VERSION "ZCUD_CAN1"

NS_ :

BS_:

BU_: ETC OGM POT SRS3 TRM ZCUD

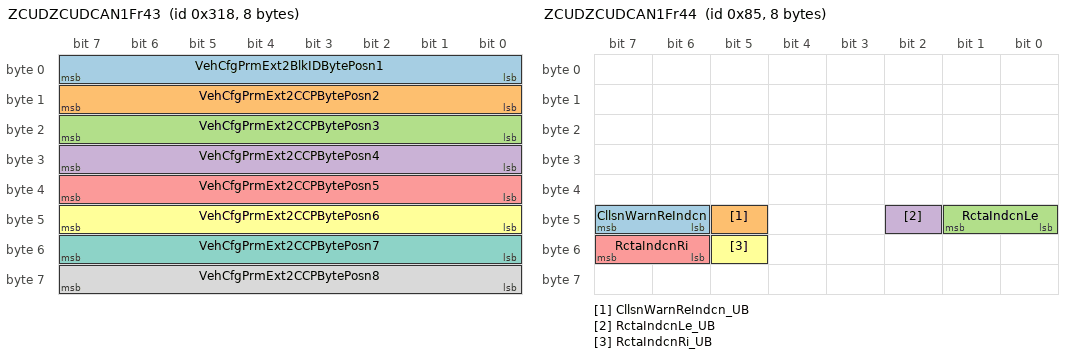
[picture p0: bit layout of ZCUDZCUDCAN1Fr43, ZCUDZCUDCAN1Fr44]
BO_ 792 ZCUDZCUDCAN1Fr43: 8 ZCUD
 SG_ VehCfgPrmExt2BlkIDBytePosn1 : 7|8@0+ (1,0) [0|255] "Unitless"  OGM,POT,SRS3,TRM
 SG_ VehCfgPrmExt2CCPBytePosn2 : 15|8@0+ (1,0) [0|255] "Unitless"  OGM,POT,SRS3,TRM
 SG_ VehCfgPrmExt2CCPBytePosn3 : 23|8@0+ (1,0) [0|255] "Unitless"  OGM,POT,SRS3,TRM
 SG_ VehCfgPrmExt2CCPBytePosn4 : 31|8@0+ (1,0) [0|255] "Unitless"  OGM,POT,SRS3,TRM
 SG_ VehCfgPrmExt2CCPBytePosn5 : 39|8@0+ (1,0) [0|255] "Unitless"  OGM,POT,SRS3,TRM
 SG_ VehCfgPrmExt2CCPBytePosn6 : 47|8@0+ (1,0) [0|255] "Unitless"  OGM,POT,SRS3,TRM
 SG_ VehCfgPrmExt2CCPBytePosn7 : 55|8@0+ (1,0) [0|255] "Unitless"  OGM,POT,SRS3,TRM
 SG_ VehCfgPrmExt2CCPBytePosn8 : 63|8@0+ (1,0) [0|255] "Unitless"  OGM,POT,SRS3,TRM

BO_ 133 ZCUDZCUDCAN1Fr44: 8 ZCUD
 SG_ CllsnWarnReIndcn : 47|2@0+ (1,0) [0|3] "" Vector__XXX
 SG_ CllsnWarnReIndcn_UB : 45|1@0+ (1,0) [0|1] "" Vector__XXX
 SG_ RctaIndcnLe : 41|2@0+ (1,0) [0|3] "" Vector__XXX
 SG_ RctaIndcnLe_UB : 42|1@0+ (1,0) [0|1] "" Vector__XXX
 SG_ RctaIndcnRi : 55|2@0+ (1,0) [0|3] "" Vector__XXX
 SG_ RctaIndcnRi_UB : 53|1@0+ (1,0) [0|1] "" Vector__XXX

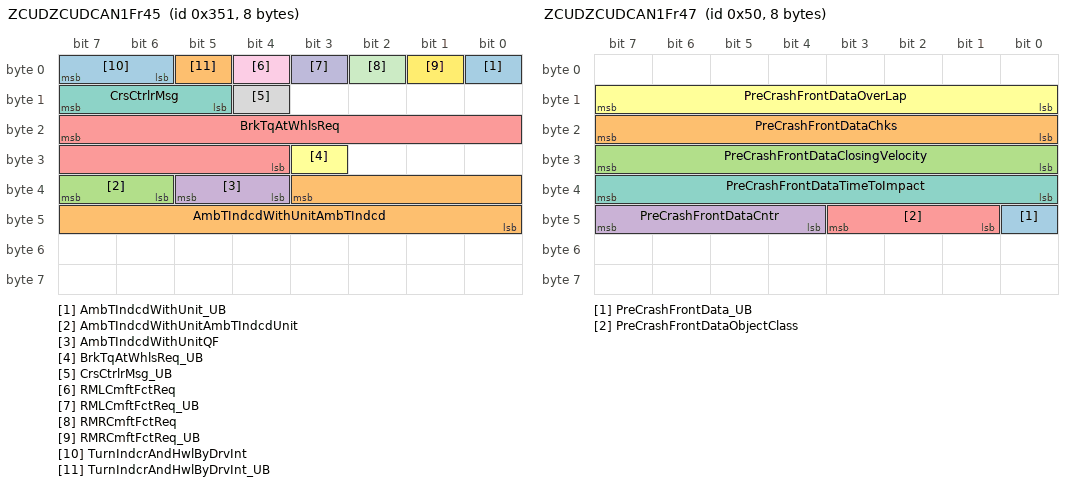
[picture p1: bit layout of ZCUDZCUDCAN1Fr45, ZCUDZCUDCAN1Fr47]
BO_ 849 ZCUDZCUDCAN1Fr45: 8 ZCUD
 SG_ AmbTIndcdWithUnit_UB : 0|1@0+ (1,0) [0|1] ""  SRS3
 SG_ AmbTIndcdWithUnitAmbTIndcd : 35|12@0+ (0.1,-100) [-100|309.5] "Unitless"  SRS3
 SG_ AmbTIndcdWithUnitAmbTIndcdUnit : 39|2@0+ (1,0) [0|3] ""  SRS3
 SG_ AmbTIndcdWithUnitQF : 37|2@0+ (1,0) [0|3] ""  SRS3
 SG_ BrkTqAtWhlsReq : 23|12@0+ (4,0) [0|16380] "Nm"  SRS3
 SG_ BrkTqAtWhlsReq_UB : 27|1@0+ (1,0) [0|1] ""  SRS3
 SG_ CrsCtrlrMsg : 15|3@0+ (1,0) [0|7] ""  SRS3
 SG_ CrsCtrlrMsg_UB : 12|1@0+ (1,0) [0|1] ""  SRS3
 SG_ RMLCmftFctReq : 4|1@0+ (1,0) [0|1] "" Vector__XXX
 SG_ RMLCmftFctReq_UB : 3|1@0+ (1,0) [0|1] "" Vector__XXX
 SG_ RMRCmftFctReq : 2|1@0+ (1,0) [0|1] "" Vector__XXX
 SG_ RMRCmftFctReq_UB : 1|1@0+ (1,0) [0|1] "" Vector__XXX
 SG_ TurnIndcrAndHwlByDrvInt : 7|2@0+ (1,0) [0|3] ""  SRS3
 SG_ TurnIndcrAndHwlByDrvInt_UB : 5|1@0+ (1,0) [0|1] ""  SRS3

BO_ 528 ZCUDZCUDCAN1Fr46: 8 ZCUD
 SG_ ADTakeoverReqGroup_UB : 7|1@0+ (1,0) [0|1] "" Vector__XXX
 SG_ ADTakeoverReqGroupADTakeoverAudi : 23|2@0+ (1,0) [0|3] "" Vector__XXX
 SG_ ADTakeoverReqGroupADTakeoverMsg : 6|3@0+ (1,0) [0|7] "" Vector__XXX
 SG_ ADTakeoverReqGroupChks : 15|8@0+ (1,0) [0|255] "Unitless" Vector__XXX
 SG_ ADTakeoverReqGroupCntr : 3|4@0+ (1,0) [0|15] "Unitless" Vector__XXX
 SG_ AsySftyFctStsToEDR_UB : 49|1@0+ (1,0) [0|1] ""  SRS3
 SG_ AsySftyFctStsToEDRACCFctSTs : 21|3@0+ (1,0) [0|7] ""  SRS3
 SG_ AsySftyFctStsToEDRACSFB1FctSts : 18|3@0+ (1,0) [0|7] ""  SRS3
 SG_ AsySftyFctStsToEDRACSFB2FctSts : 31|3@0+ (1,0) [0|7] ""  SRS3
 SG_ AsySftyFctStsToEDRACSFCFctSts : 28|3@0+ (1,0) [0|7] ""  SRS3
 SG_ AsySftyFctStsToEDRACSFDFctSts : 39|3@0+ (1,0) [0|7] ""  SRS3
 SG_ AsySftyFctStsToEDRACSFEFctSts : 36|3@0+ (1,0) [0|7] ""  SRS3
 SG_ AsySftyFctStsToEDRAEBSFctSts : 47|3@0+ (1,0) [0|7] ""  SRS3
 SG_ AsySftyFctStsToEDRCSFFctSts : 44|3@0+ (1,0) [0|7] ""  SRS3
 SG_ AsySftyFctStsToEDRESFFctSts : 55|3@0+ (1,0) [0|7] ""  SRS3
 SG_ AsySftyFctStsToEDRLDWSFctSts : 52|3@0+ (1,0) [0|7] ""  SRS3
 SG_ SeatDownLumPosCtrlDrvr : 63|7@0+ (1,0) [0|127] "%" Vector__XXX
 SG_ SeatDownLumPosCtrlDrvr_UB : 56|1@0+ (1,0) [0|1] "" Vector__XXX

BO_ 80 ZCUDZCUDCAN1Fr47: 8 ZCUD
 SG_ PreCrashFrontData_UB : 40|1@0+ (1,0) [0|1] ""  SRS3
 SG_ PreCrashFrontDataChks : 23|8@0+ (1,0) [0|255] "Unitless"  SRS3
 SG_ PreCrashFrontDataClosingVelocity : 31|8@0+ (0.167,0) [0|42.585] "m/s"  SRS3
 SG_ PreCrashFrontDataCntr : 47|4@0+ (1,0) [0|15] "Unitless"  SRS3
 SG_ PreCrashFrontDataObjectClass : 43|3@0+ (1,0) [0|7] ""  SRS3
 SG_ PreCrashFrontDataOverLap : 15|8@0+ (1,-100) [-100|100] "%"  SRS3
 SG_ PreCrashFrontDataTimeToImpact : 39|8@0+ (0.004,0) [0|1.02] "s"  SRS3

BO_ 521 ZCUDZCUDCAN1Fr48: 8 ZCUD
 SG_ DrvrSeatAdpvSideSpprtSetg : 45|2@0+ (1,0) [0|3] "" Vector__XXX
 SG_ DrvrSeatAdpvSideSpprtSetg_UB : 43|1@0+ (1,0) [0|1] "" Vector__XXX
 SG_ DrvrSeatSideSpprtSetg : 42|2@0+ (1,0) [0|3] "" Vector__XXX
 SG_ DrvrSeatSideSpprtSetg_UB : 40|1@0+ (1,0) [0|1] "" Vector__XXX
 SG_ HmiSeatHeatAutStrtRowSecLe : 25|1@0+ (1,0) [0|1] "" Vector__XXX
 SG_ HmiSeatHeatAutStrtRowSecLe_UB : 24|1@0+ (1,0) [0|1] "" Vector__XXX
 SG_ HmiSeatHeatAutStrtRowSecRi : 39|1@0+ (1,0) [0|1] "" Vector__XXX
 SG_ HmiSeatHeatAutStrtRowSecRi_UB : 38|1@0+ (1,0) [0|1] "" Vector__XXX
 SG_ HmiSeatHeatAutStrtRowThrdLe : 37|1@0+ (1,0) [0|1] "" Vector__XXX
 SG_ HmiSeatHeatAutStrtRowThrdLe_UB : 36|1@0+ (1,0) [0|1] "" Vector__XXX
 SG_ HmiSeatHeatAutStrtRowThrdRi : 35|1@0+ (1,0) [0|1] "" Vector__XXX
 SG_ HmiSeatHeatAutStrtRowThrdRi_UB : 34|1@0+ (1,0) [0|1] "" Vector__XXX
 SG_ HmiSeatVentAutStrtRowSecLe : 33|1@0+ (1,0) [0|1] "" Vector__XXX
 SG_ HmiSeatVentAutStrtRowSecLe_UB : 32|1@0+ (1,0) [0|1] "" Vector__XXX
 SG_ HmiSeatVentAutStrtRowSecRi : 47|1@0+ (1,0) [0|1] "" Vector__XXX
 SG_ HmiSeatVentAutStrtRowSecRi_UB : 46|1@0+ (1,0) [0|1] "" Vector__XXX
 SG_ SeatClimaDurgClimaHmiSeatHeatgFo : 23|2@0+ (1,0) [0|3] "" Vector__XXX
 SG_ SeatClimaDurgClimaHmiSeatHe_0000 : 21|1@0+ (1,0) [0|1] "" Vector__XXX
 SG_ SeatClimaDurgClimaHmiSeatHe_0001 : 20|2@0+ (1,0) [0|3] "" Vector__XXX
 SG_ SeatClimaDurgClimaHmiSeatHe_0002 : 18|1@0+ (1,0) [0|1] "" Vector__XXX
 SG_ SeatClimaDurgClimaHmiSeatVentnFo : 31|2@0+ (1,0) [0|3] "" Vector__XXX
 SG_ SeatClimaDurgClimaHmiSeatVe_0000 : 29|1@0+ (1,0) [0|1] "" Vector__XXX
 SG_ SeatClimaDurgClimaHmiSeatVe_0001 : 28|2@0+ (1,0) [0|3] "" Vector__XXX
 SG_ SeatClimaDurgClimaHmiSeatVe_0002 : 26|1@0+ (1,0) [0|1] "" Vector__XXX
 SG_ SeatMassgBackBlstrCtrlDrvr : 55|2@0+ (1,0) [0|3] "" Vector__XXX
 SG_ SeatMassgBackBlstrCtrlDrvr_UB : 53|1@0+ (1,0) [0|1] "" Vector__XXX
 SG_ SeatMassgBackBlstrEnaDrvr : 52|1@0+ (1,0) [0|1] "" Vector__XXX
 SG_ SeatMassgBackBlstrEnaDrvr_UB : 51|1@0+ (1,0) [0|1] "" Vector__XXX
 SG_ SeatMassgCushBlstrCtrlDrvr : 50|2@0+ (1,0) [0|3] "" Vector__XXX
 SG_ SeatMassgCushBlstrCtrlDrvr_UB : 48|1@0+ (1,0) [0|1] "" Vector__XXX
 SG_ SeatMassgCushBlstrEnaDrvr : 63|1@0+ (1,0) [0|1] "" Vector__XXX
 SG_ SeatMassgCushBlstrEnaDrvr_UB : 62|1@0+ (1,0) [0|1] "" Vector__XXX
 SG_ SeatMassgCushLiftCtrlDrvr : 61|1@0+ (1,0) [0|1] "" Vector__XXX
 SG_ SeatMassgCushLiftCtrlDrvr_UB : 60|1@0+ (1,0) [0|1] "" Vector__XXX
 SG_ SeatMassgCushLiftEnaDrvr : 59|1@0+ (1,0) [0|1] "" Vector__XXX
 SG_ SeatMassgCushLiftEnaDrvr_UB : 58|1@0+ (1,0) [0|1] "" Vector__XXX
 SG_ SeatMassgLumExtnCtrlDrvr : 57|2@0+ (1,0) [0|3] "" Vector__XXX
 SG_ SeatMassgLumExtnCtrlDrvr_UB : 16|1@0+ (1,0) [0|1] "" Vector__XXX
 SG_ WhlMotSysSpdAct : 7|16@0+ (1,-20000) [-20000|45535] "rpm"  SRS3
 SG_ WhlMotSysSpdAct_UB : 17|1@0+ (1,0) [0|1] ""  SRS3

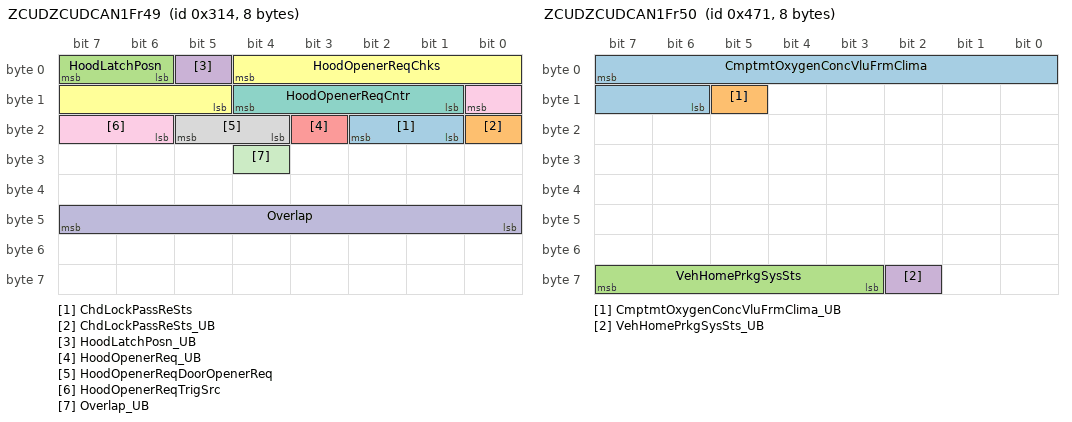
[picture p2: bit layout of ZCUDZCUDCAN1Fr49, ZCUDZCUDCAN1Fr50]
BO_ 788 ZCUDZCUDCAN1Fr49: 8 ZCUD
 SG_ ChdLockPassReSts : 18|2@0+ (1,0) [0|3] "" Vector__XXX
 SG_ ChdLockPassReSts_UB : 16|1@0+ (1,0) [0|1] "" Vector__XXX
 SG_ HoodLatchPosn : 7|2@0+ (1,0) [0|3] "" Vector__XXX
 SG_ HoodLatchPosn_UB : 5|1@0+ (1,0) [0|1] "" Vector__XXX
 SG_ HoodOpenerReq_UB : 19|1@0+ (1,0) [0|1] "" Vector__XXX
 SG_ HoodOpenerReqChks : 4|8@0+ (1,0) [0|255] "Unitless" Vector__XXX
 SG_ HoodOpenerReqCntr : 12|4@0+ (1,0) [0|15] "Unitless" Vector__XXX
 SG_ HoodOpenerReqDoorOpenerReq : 21|2@0+ (1,0) [0|3] "" Vector__XXX
 SG_ HoodOpenerReqTrigSrc : 8|3@0+ (1,0) [0|7] "" Vector__XXX
 SG_ Overlap : 47|8@0+ (1,-100) [-100|100] "%"  SRS3
 SG_ Overlap_UB : 28|1@0+ (1,0) [0|1] ""  SRS3

BO_ 1137 ZCUDZCUDCAN1Fr50: 8 ZCUD
 SG_ CmptmtOxygenConcVluFrmClima : 7|10@0+ (0.1,0) [0|100] "%"  OGM
 SG_ CmptmtOxygenConcVluFrmClima_UB : 13|1@0+ (1,0) [0|1] ""  OGM
 SG_ VehHomePrkgSysSts : 63|5@0+ (1,0) [0|31] ""  SRS3
 SG_ VehHomePrkgSysSts_UB : 58|1@0+ (1,0) [0|1] ""  SRS3

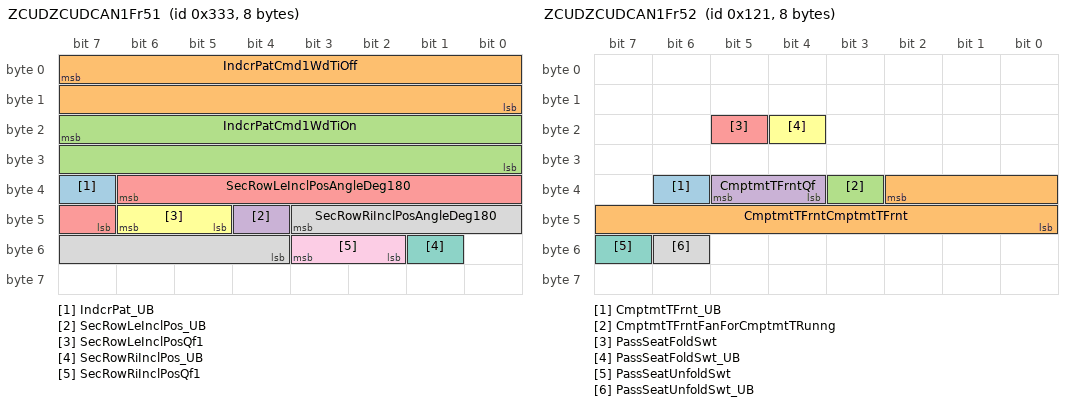
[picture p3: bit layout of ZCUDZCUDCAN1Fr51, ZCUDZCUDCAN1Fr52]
BO_ 819 ZCUDZCUDCAN1Fr51: 8 ZCUD
 SG_ IndcrPat_UB : 39|1@0+ (1,0) [0|1] ""  TRM
 SG_ IndcrPatCmd1WdTiOff : 7|16@0+ (0.001,0) [0|65.535] "s"  TRM
 SG_ IndcrPatCmd1WdTiOn : 23|16@0+ (0.001,0) [0|65.535] "s"  TRM
 SG_ SecRowLeInclPos_UB : 44|1@0+ (1,0) [0|1] "" Vector__XXX
 SG_ SecRowLeInclPosAngleDeg180 : 38|8@0+ (1,0) [0|180] "Deg" Vector__XXX
 SG_ SecRowLeInclPosQf1 : 46|2@0+ (1,0) [0|3] "" Vector__XXX
 SG_ SecRowRiInclPos_UB : 49|1@0+ (1,0) [0|1] "" Vector__XXX
 SG_ SecRowRiInclPosAngleDeg180 : 43|8@0+ (1,0) [0|180] "Deg" Vector__XXX
 SG_ SecRowRiInclPosQf1 : 51|2@0+ (1,0) [0|3] "" Vector__XXX

BO_ 289 ZCUDZCUDCAN1Fr52: 8 ZCUD
 SG_ CmptmtTFrnt_UB : 38|1@0+ (1,0) [0|1] "" Vector__XXX
 SG_ CmptmtTFrntCmptmtTFrnt : 34|11@0+ (0.1,-60) [-60|125] "degC" Vector__XXX
 SG_ CmptmtTFrntFanForCmptmtTRunng : 35|1@0+ (1,0) [0|1] "" Vector__XXX
 SG_ CmptmtTFrntQf : 37|2@0+ (1,0) [0|3] "" Vector__XXX
 SG_ PassSeatFoldSwt : 21|1@0+ (1,0) [0|1] "" Vector__XXX
 SG_ PassSeatFoldSwt_UB : 20|1@0+ (1,0) [0|1] "" Vector__XXX
 SG_ PassSeatUnfoldSwt : 55|1@0+ (1,0) [0|1] "" Vector__XXX
 SG_ PassSeatUnfoldSwt_UB : 54|1@0+ (1,0) [0|1] "" Vector__XXX

BO_ 1168 ZCUDZCUDCAN1Fr53: 8 ZCUD
 SG_ AmbTEstimd_UB : 5|1@0+ (1,0) [0|1] "" Vector__XXX
 SG_ AmbTEstimdAmbTEstimd : 2|11@0+ (0.1,-70) [-70|134.7] "degC" Vector__XXX
 SG_ AmbTEstimdQf : 3|1@0+ (1,0) [0|1] "" Vector__XXX
 SG_ AsyNoaBltFastn : 58|2@0+ (1,0) [0|3] "" Vector__XXX
 SG_ AsyNoaBltFastn_UB : 56|1@0+ (1,0) [0|1] "" Vector__XXX
 SG_ ChdLockDrvrReSts : 7|2@0+ (1,0) [0|3] "" Vector__XXX
 SG_ ChdLockDrvrReSts_UB : 4|1@0+ (1,0) [0|1] "" Vector__XXX
 SG_ SeatClimaDurgClima_UB : 63|1@0+ (1,0) [0|1] "" Vector__XXX
 SG_ SeatClimaDurgClimaHmiSeatHe_0003 : 41|2@0+ (1,0) [0|3] "" Vector__XXX
 SG_ SeatClimaDurgClimaHmiSeatHe_0004 : 43|2@0+ (1,0) [0|3] "" Vector__XXX
 SG_ SeatClimaDurgClimaHmiSeatHe_0005 : 45|2@0+ (1,0) [0|3] "" Vector__XXX
 SG_ SeatClimaDurgClimaHmiSeatHe_0006 : 47|2@0+ (1,0) [0|3] "" Vector__XXX
 SG_ SeatClimaDurgClimaHmiSeatVe_0003 : 49|2@0+ (1,0) [0|3] "" Vector__XXX
 SG_ SeatClimaDurgClimaHmiSeatVe_0004 : 51|2@0+ (1,0) [0|3] "" Vector__XXX
 SG_ SeatClimaDurgClimaHmiSeatVe_0005 : 53|2@0+ (1,0) [0|3] "" Vector__XXX
 SG_ SeatClimaDurgClimaHmiSeatVe_0006 : 55|2@0+ (1,0) [0|3] "" Vector__XXX
 SG_ SecRowLeSeatHeatgPwrAllwd : 39|8@0+ (1,0) [0|255] "Unitless" Vector__XXX
 SG_ SecRowLeSeatHeatgPwrAllwd_UB : 62|1@0+ (1,0) [0|1] "" Vector__XXX

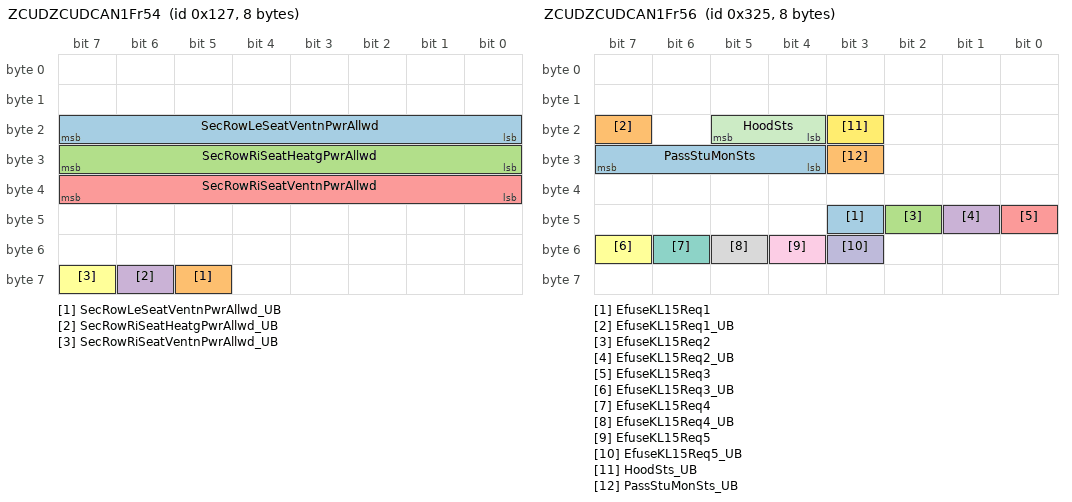
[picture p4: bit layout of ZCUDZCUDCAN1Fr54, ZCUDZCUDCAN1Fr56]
BO_ 295 ZCUDZCUDCAN1Fr54: 8 ZCUD
 SG_ SecRowLeSeatVentnPwrAllwd : 23|8@0+ (1,0) [0|255] "Unitless" Vector__XXX
 SG_ SecRowLeSeatVentnPwrAllwd_UB : 61|1@0+ (1,0) [0|1] "" Vector__XXX
 SG_ SecRowRiSeatHeatgPwrAllwd : 31|8@0+ (1,0) [0|255] "Unitless" Vector__XXX
 SG_ SecRowRiSeatHeatgPwrAllwd_UB : 62|1@0+ (1,0) [0|1] "" Vector__XXX
 SG_ SecRowRiSeatVentnPwrAllwd : 39|8@0+ (1,0) [0|255] "Unitless" Vector__XXX
 SG_ SecRowRiSeatVentnPwrAllwd_UB : 63|1@0+ (1,0) [0|1] "" Vector__XXX

BO_ 805 ZCUDZCUDCAN1Fr56: 8 ZCUD
 SG_ EfuseKL15Req1 : 43|1@0+ (1,0) [0|1] ""  SRS3
 SG_ EfuseKL15Req1_UB : 23|1@0+ (1,0) [0|1] ""  SRS3
 SG_ EfuseKL15Req2 : 42|1@0+ (1,0) [0|1] ""  SRS3
 SG_ EfuseKL15Req2_UB : 41|1@0+ (1,0) [0|1] ""  SRS3
 SG_ EfuseKL15Req3 : 40|1@0+ (1,0) [0|1] ""  SRS3
 SG_ EfuseKL15Req3_UB : 55|1@0+ (1,0) [0|1] ""  SRS3
 SG_ EfuseKL15Req4 : 54|1@0+ (1,0) [0|1] ""  SRS3
 SG_ EfuseKL15Req4_UB : 53|1@0+ (1,0) [0|1] ""  SRS3
 SG_ EfuseKL15Req5 : 52|1@0+ (1,0) [0|1] ""  SRS3
 SG_ EfuseKL15Req5_UB : 51|1@0+ (1,0) [0|1] ""  SRS3
 SG_ HoodSts : 21|2@0+ (1,0) [0|3] ""  SRS3
 SG_ HoodSts_UB : 19|1@0+ (1,0) [0|1] ""  SRS3
 SG_ PassStuMonSts : 31|4@0+ (1,0) [0|15] "Unitless"  SRS3
 SG_ PassStuMonSts_UB : 27|1@0+ (1,0) [0|1] ""  SRS3

BO_ 612 ZCUDZCUDCAN1Fr57: 8 ZCUD
 SG_ ChgFilElmRst : 57|2@0+ (1,0) [0|3] "Unitless"  OGM
 SG_ ChgFilElmRst_UB : 36|1@0+ (1,0) [0|1] ""  OGM
 SG_ DrvrStuMonSts : 20|4@0+ (1,0) [0|15] "Unitless"  SRS3
 SG_ DrvrStuMonSts_UB : 16|1@0+ (1,0) [0|1] ""  SRS3
 SG_ RollAgGlb_UB : 21|1@0+ (1,0) [0|1] "" Vector__XXX
 SG_ RollAgGlbQf : 23|2@0+ (1,0) [0|3] "" Vector__XXX
 SG_ RollAgGlbVal : 7|16@0- (3.0518E-005,0) [-0.999983306|0.999983306] "rad" Vector__XXX
 SG_ SecLeDiagcStopReq : 35|1@0+ (1,0) [0|1] "" Vector__XXX
 SG_ SecLeDiagcStopReq_UB : 34|1@0+ (1,0) [0|1] "" Vector__XXX
 SG_ SecRiDiagcStopReq : 33|1@0+ (1,0) [0|1] "" Vector__XXX
 SG_ SecRiDiagcStopReq_UB : 32|1@0+ (1,0) [0|1] "" Vector__XXX
 SG_ SecRowRiHeatgLvl : 63|2@0+ (1,0) [0|3] "" Vector__XXX
 SG_ SecRowRiHeatgLvl_UB : 61|1@0+ (1,0) [0|1] "" Vector__XXX
 SG_ SecRowRiVentnLvl : 60|2@0+ (1,0) [0|3] "" Vector__XXX
 SG_ SecRowRiVentnLvl_UB : 58|1@0+ (1,0) [0|1] "" Vector__XXX
 SG_ ThrdLeDiagcStopReq : 50|1@0+ (1,0) [0|1] "" Vector__XXX
 SG_ ThrdLeDiagcStopReq_UB : 49|1@0+ (1,0) [0|1] "" Vector__XXX
 SG_ ThrdRiDiagcStopReq : 48|1@0+ (1,0) [0|1] "" Vector__XXX
 SG_ ThrdRiDiagcStopReq_UB : 41|1@0+ (1,0) [0|1] "" Vector__XXX
 SG_ WinPosnStsAtDrvr : 47|5@0+ (1,0) [0|31] "" Vector__XXX
 SG_ WinPosnStsAtDrvr_UB : 42|1@0+ (1,0) [0|1] "" Vector__XXX
 SG_ WinPosnStsAtReLe : 55|5@0+ (1,0) [0|31] "" Vector__XXX
 SG_ WinPosnStsAtReLe_UB : 40|1@0+ (1,0) [0|1] "" Vector__XXX

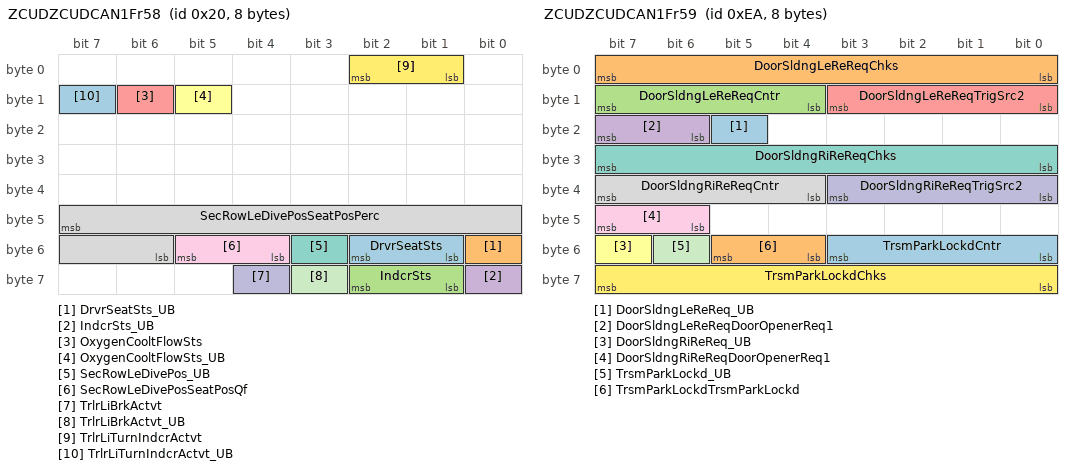
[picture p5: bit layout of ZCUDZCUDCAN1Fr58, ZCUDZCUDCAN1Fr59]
BO_ 32 ZCUDZCUDCAN1Fr58: 8 ZCUD
 SG_ DrvrSeatSts : 50|2@0+ (1,0) [0|3] "" Vector__XXX
 SG_ DrvrSeatSts_UB : 48|1@0+ (1,0) [0|1] "" Vector__XXX
 SG_ IndcrSts : 58|2@0+ (1,0) [0|3] ""  TRM
 SG_ IndcrSts_UB : 56|1@0+ (1,0) [0|1] ""  TRM
 SG_ OxygenCooltFlowSts : 14|1@0+ (1,0) [0|1] ""  OGM
 SG_ OxygenCooltFlowSts_UB : 13|1@0+ (1,0) [0|1] ""  OGM
 SG_ SecRowLeDivePos_UB : 51|1@0+ (1,0) [0|1] "" Vector__XXX
 SG_ SecRowLeDivePosSeatPosPerc : 47|10@0+ (0.1,0) [0|100] "%" Vector__XXX
 SG_ SecRowLeDivePosSeatPosQf : 53|2@0+ (1,0) [0|3] "" Vector__XXX
 SG_ TrlrLiBrkActvt : 60|1@0+ (1,0) [0|1] ""  TRM
 SG_ TrlrLiBrkActvt_UB : 59|1@0+ (1,0) [0|1] ""  TRM
 SG_ TrlrLiTurnIndcrActvt : 2|2@0+ (1,0) [0|3] ""  TRM
 SG_ TrlrLiTurnIndcrActvt_UB : 15|1@0+ (1,0) [0|1] ""  TRM

BO_ 234 ZCUDZCUDCAN1Fr59: 8 ZCUD
 SG_ DoorSldngLeReReq_UB : 21|1@0+ (1,0) [0|1] "" Vector__XXX
 SG_ DoorSldngLeReReqChks : 7|8@0+ (1,0) [0|255] "Unitless" Vector__XXX
 SG_ DoorSldngLeReReqCntr : 15|4@0+ (1,0) [0|15] "Unitless" Vector__XXX
 SG_ DoorSldngLeReReqDoorOpenerReq1 : 23|2@0+ (1,0) [0|3] "" Vector__XXX
 SG_ DoorSldngLeReReqTrigSrc2 : 11|4@0+ (1,0) [0|15] "" Vector__XXX
 SG_ DoorSldngRiReReq_UB : 55|1@0+ (1,0) [0|1] "" Vector__XXX
 SG_ DoorSldngRiReReqChks : 31|8@0+ (1,0) [0|255] "Unitless" Vector__XXX
 SG_ DoorSldngRiReReqCntr : 39|4@0+ (1,0) [0|15] "Unitless" Vector__XXX
 SG_ DoorSldngRiReReqDoorOpenerReq1 : 47|2@0+ (1,0) [0|3] "" Vector__XXX
 SG_ DoorSldngRiReReqTrigSrc2 : 35|4@0+ (1,0) [0|15] "" Vector__XXX
 SG_ TrsmParkLockd_UB : 54|1@0+ (1,0) [0|1] "" Vector__XXX
 SG_ TrsmParkLockdChks : 63|8@0+ (1,0) [0|255] "Unitless" Vector__XXX
 SG_ TrsmParkLockdCntr : 51|4@0+ (1,0) [0|15] "Unitless" Vector__XXX
 SG_ TrsmParkLockdTrsmParkLockd : 53|2@0+ (1,0) [0|3] "" Vector__XXX

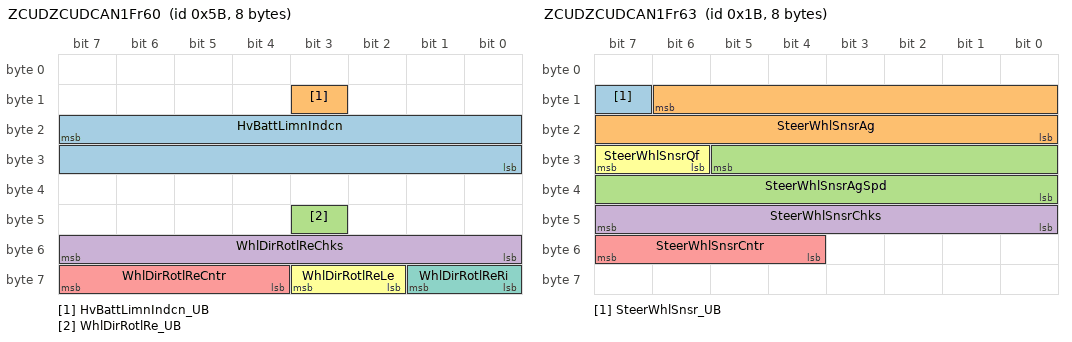
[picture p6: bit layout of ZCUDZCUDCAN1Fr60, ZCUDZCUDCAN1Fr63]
BO_ 91 ZCUDZCUDCAN1Fr60: 8 ZCUD
 SG_ HvBattLimnIndcn : 23|16@0+ (1,0) [0|65535] "Unitless" Vector__XXX
 SG_ HvBattLimnIndcn_UB : 11|1@0+ (1,0) [0|1] "" Vector__XXX
 SG_ WhlDirRotlRe_UB : 43|1@0+ (1,0) [0|1] ""  SRS3
 SG_ WhlDirRotlReChks : 55|8@0+ (1,0) [0|255] "Unitless"  SRS3
 SG_ WhlDirRotlReCntr : 63|4@0+ (1,0) [0|15] "Unitless"  SRS3
 SG_ WhlDirRotlReLe : 59|2@0+ (1,0) [0|3] ""  SRS3
 SG_ WhlDirRotlReRi : 57|2@0+ (1,0) [0|3] ""  SRS3

BO_ 27 ZCUDZCUDCAN1Fr63: 8 ZCUD
 SG_ SteerWhlSnsr_UB : 15|1@0+ (1,0) [0|1] "" Vector__XXX
 SG_ SteerWhlSnsrAg : 14|15@0- (0.0009765625,0) [-14.5|14.5] "rad" Vector__XXX
 SG_ SteerWhlSnsrAgSpd : 29|14@0- (0.0078125,0) [-50|50] "rad/s" Vector__XXX
 SG_ SteerWhlSnsrChks : 47|8@0+ (1,0) [0|255] "Unitless" Vector__XXX
 SG_ SteerWhlSnsrCntr : 55|4@0+ (1,0) [0|15] "Unitless" Vector__XXX
 SG_ SteerWhlSnsrQf : 31|2@0+ (1,0) [0|3] "" Vector__XXX

BO_ 533 ZCUDZCUDCAN1Fr65: 8 ZCUD
 SG_ ChrgnOrDisChrgnStsFb : 7|5@0+ (1,0) [0|31] "" Vector__XXX
 SG_ ChrgnOrDisChrgnStsFb_UB : 2|1@0+ (1,0) [0|1] "" Vector__XXX
 SG_ DrvrPfmncAlrmReqFromDHU : 15|3@0+ (1,0) [0|7] "" Vector__XXX
 SG_ DrvrPfmncAlrmReqFromDHU_UB : 12|1@0+ (1,0) [0|1] "" Vector__XXX
 SG_ OxygenSplyReq : 11|2@0+ (1,0) [0|3] ""  OGM
 SG_ OxygenSplyReq_UB : 9|1@0+ (1,0) [0|1] ""  OGM
 SG_ SecRowSeatLeChildLockSet : 52|1@0+ (1,0) [0|1] "" Vector__XXX
 SG_ SecRowSeatLeChildLockSet_UB : 51|1@0+ (1,0) [0|1] "" Vector__XXX
 SG_ SecRowSeatRiChildLockSet : 50|1@0+ (1,0) [0|1] "" Vector__XXX
 SG_ SecRowSeatRiChildLockSet_UB : 49|1@0+ (1,0) [0|1] "" Vector__XXX
 SG_ ThrdRowLeSeatHeatgPwrAllwd : 23|8@0+ (1,0) [0|255] "Unitless" Vector__XXX
 SG_ ThrdRowLeSeatHeatgPwrAllwd_UB : 8|1@0+ (1,0) [0|1] "" Vector__XXX
 SG_ ThrdRowLeSeatVentnPwrAllwd : 31|8@0+ (1,0) [0|255] "Unitless" Vector__XXX
 SG_ ThrdRowLeSeatVentnPwrAllwd_UB : 55|1@0+ (1,0) [0|1] "" Vector__XXX
 SG_ ThrdRowRiSeatHeatgPwrAllwd : 39|8@0+ (1,0) [0|255] "Unitless" Vector__XXX
 SG_ ThrdRowRiSeatHeatgPwrAllwd_UB : 54|1@0+ (1,0) [0|1] "" Vector__XXX
 SG_ ThrdRowRiSeatVentnPwrAllwd : 47|8@0+ (1,0) [0|255] "Unitless" Vector__XXX
 SG_ ThrdRowRiSeatVentnPwrAllwd_UB : 53|1@0+ (1,0) [0|1] "" Vector__XXX
 SG_ ThrdRowSeatLeChildLockSet : 63|1@0+ (1,0) [0|1] "" Vector__XXX
 SG_ ThrdRowSeatLeChildLockSet_UB : 62|1@0+ (1,0) [0|1] "" Vector__XXX
 SG_ ThrdRowSeatRiChildLockSet : 61|1@0+ (1,0) [0|1] "" Vector__XXX
 SG_ ThrdRowSeatRiChildLockSet_UB : 60|1@0+ (1,0) [0|1] "" Vector__XXX
 SG_ UpperLowerTrSelnSwt : 1|1@0+ (1,0) [0|1] "" Vector__XXX
 SG_ UpperLowerTrSelnSwt_UB : 0|1@0+ (1,0) [0|1] "" Vector__XXX

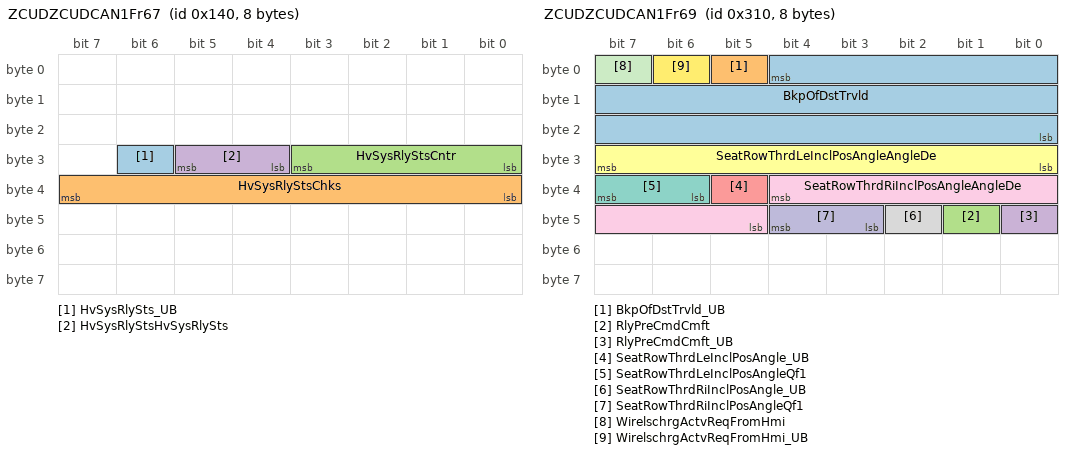
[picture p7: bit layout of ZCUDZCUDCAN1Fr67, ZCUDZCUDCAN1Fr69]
BO_ 320 ZCUDZCUDCAN1Fr67: 8 ZCUD
 SG_ HvSysRlySts_UB : 30|1@0+ (1,0) [0|1] "" Vector__XXX
 SG_ HvSysRlyStsChks : 39|8@0+ (1,0) [0|255] "Unitless" Vector__XXX
 SG_ HvSysRlyStsCntr : 27|4@0+ (1,0) [0|15] "Unitless" Vector__XXX
 SG_ HvSysRlyStsHvSysRlySts : 29|2@0+ (1,0) [0|3] "" Vector__XXX

BO_ 384 ZCUDZCUDCAN1Fr68: 8 ZCUD
 SG_ TrlrLiRvsgActvt : 56|1@0+ (1,0) [0|1] ""  TRM
 SG_ TrlrLiRvsgActvt_UB : 57|1@0+ (1,0) [0|1] ""  TRM

BO_ 784 ZCUDZCUDCAN1Fr69: 8 ZCUD
 SG_ BkpOfDstTrvld : 4|21@0+ (1,0) [0|2000000] "km"  OGM,POT,SRS3,TRM
 SG_ BkpOfDstTrvld_UB : 5|1@0+ (1,0) [0|1] ""  OGM,POT,SRS3,TRM
 SG_ RlyPreCmdCmft : 41|1@0+ (1,0) [0|1] ""  OGM
 SG_ RlyPreCmdCmft_UB : 40|1@0+ (1,0) [0|1] ""  OGM
 SG_ SeatRowThrdLeInclPosAngle_UB : 37|1@0+ (1,0) [0|1] "" Vector__XXX
 SG_ SeatRowThrdLeInclPosAngleAngleDe : 31|8@0+ (1,0) [0|180] "Deg" Vector__XXX
 SG_ SeatRowThrdLeInclPosAngleQf1 : 39|2@0+ (1,0) [0|3] "" Vector__XXX
 SG_ SeatRowThrdRiInclPosAngle_UB : 42|1@0+ (1,0) [0|1] "" Vector__XXX
 SG_ SeatRowThrdRiInclPosAngleAngleDe : 36|8@0+ (1,0) [0|180] "Deg" Vector__XXX
 SG_ SeatRowThrdRiInclPosAngleQf1 : 44|2@0+ (1,0) [0|3] "" Vector__XXX
 SG_ WirelschrgActvReqFromHmi : 7|1@0+ (1,0) [0|1] "" Vector__XXX
 SG_ WirelschrgActvReqFromHmi_UB : 6|1@0+ (1,0) [0|1] "" Vector__XXX

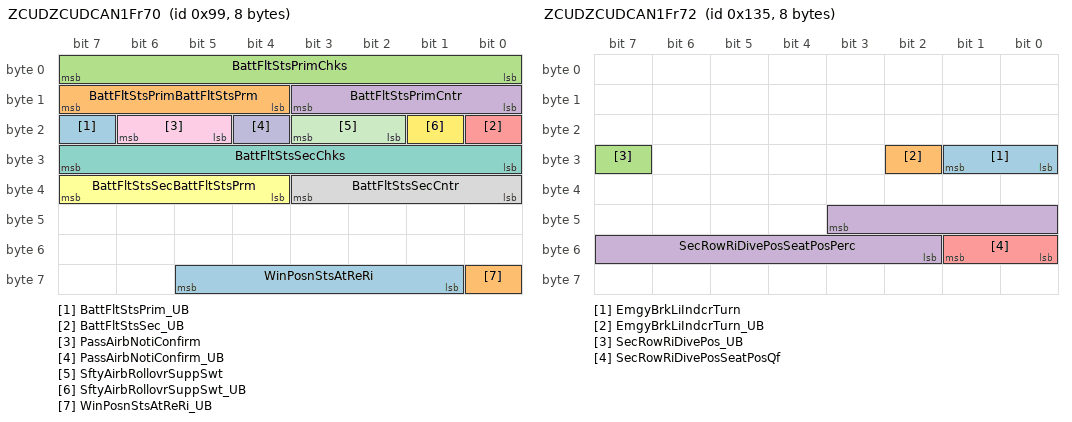
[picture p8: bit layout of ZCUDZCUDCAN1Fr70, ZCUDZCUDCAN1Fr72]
BO_ 153 ZCUDZCUDCAN1Fr70: 8 ZCUD
 SG_ BattFltStsPrim_UB : 23|1@0+ (1,0) [0|1] "" Vector__XXX
 SG_ BattFltStsPrimBattFltStsPrm : 15|4@0+ (1,0) [0|15] "" Vector__XXX
 SG_ BattFltStsPrimChks : 7|8@0+ (1,0) [0|255] "Unitless" Vector__XXX
 SG_ BattFltStsPrimCntr : 11|4@0+ (1,0) [0|15] "Unitless" Vector__XXX
 SG_ BattFltStsSec_UB : 16|1@0+ (1,0) [0|1] "" Vector__XXX
 SG_ BattFltStsSecBattFltStsPrm : 39|4@0+ (1,0) [0|15] "" Vector__XXX
 SG_ BattFltStsSecChks : 31|8@0+ (1,0) [0|255] "Unitless" Vector__XXX
 SG_ BattFltStsSecCntr : 35|4@0+ (1,0) [0|15] "Unitless" Vector__XXX
 SG_ PassAirbNotiConfirm : 22|2@0+ (1,0) [0|3] ""  SRS3
 SG_ PassAirbNotiConfirm_UB : 20|1@0+ (1,0) [0|1] ""  SRS3
 SG_ SftyAirbRollovrSuppSwt : 19|2@0+ (1,0) [0|3] ""  SRS3
 SG_ SftyAirbRollovrSuppSwt_UB : 17|1@0+ (1,0) [0|1] ""  SRS3
 SG_ WinPosnStsAtReRi : 61|5@0+ (1,0) [0|31] "" Vector__XXX
 SG_ WinPosnStsAtReRi_UB : 56|1@0+ (1,0) [0|1] "" Vector__XXX

BO_ 309 ZCUDZCUDCAN1Fr72: 8 ZCUD
 SG_ EmgyBrkLiIndcrTurn : 25|2@0+ (1,0) [0|3] ""  TRM
 SG_ EmgyBrkLiIndcrTurn_UB : 26|1@0+ (1,0) [0|1] ""  TRM
 SG_ SecRowRiDivePos_UB : 31|1@0+ (1,0) [0|1] "" Vector__XXX
 SG_ SecRowRiDivePosSeatPosPerc : 43|10@0+ (0.1,0) [0|100] "%" Vector__XXX
 SG_ SecRowRiDivePosSeatPosQf : 49|2@0+ (1,0) [0|3] "" Vector__XXX

BO_ 820 ZCUDZCUDCAN1Fr73: 8 ZCUD
 SG_ ExtrLtgSts_UB : 4|1@0+ (1,0) [0|1] ""  TRM
 SG_ ExtrLtgStsAFS : 23|2@0+ (1,0) [0|3] ""  TRM
 SG_ ExtrLtgStsAHBC : 21|2@0+ (1,0) [0|3] ""  TRM
 SG_ ExtrLtgStsAHL : 19|2@0+ (1,0) [0|3] ""  TRM
 SG_ ExtrLtgStsAllWL : 17|2@0+ (1,0) [0|3] ""  TRM
 SG_ ExtrLtgStsApproach : 31|2@0+ (1,0) [0|3] ""  TRM
 SG_ ExtrLtgStsChks : 15|8@0+ (1,0) [0|255] "Unitless"  TRM
 SG_ ExtrLtgStsCntr : 3|4@0+ (1,0) [0|15] "Unitless"  TRM
 SG_ ExtrLtgStsCornrgLi : 29|2@0+ (1,0) [0|3] ""  TRM
 SG_ ExtrLtgStsDBL : 27|2@0+ (1,0) [0|3] ""  TRM
 SG_ ExtrLtgStsDRL : 25|2@0+ (1,0) [0|3] ""  TRM
 SG_ ExtrLtgStsFlash : 39|2@0+ (1,0) [0|3] ""  TRM
 SG_ ExtrLtgStsFrntFog : 37|2@0+ (1,0) [0|3] ""  TRM
 SG_ ExtrLtgStsGoodbye : 35|2@0+ (1,0) [0|3] ""  TRM
 SG_ ExtrLtgStsHiBeam : 33|2@0+ (1,0) [0|3] ""  TRM
 SG_ ExtrLtgStsHomeSafe : 47|2@0+ (1,0) [0|3] ""  TRM
 SG_ ExtrLtgStsHWL : 45|2@0+ (1,0) [0|3] ""  TRM
 SG_ ExtrLtgStsLoBeam : 43|2@0+ (1,0) [0|3] ""  TRM
 SG_ ExtrLtgStsLtgShow : 41|2@0+ (1,0) [0|3] ""  TRM
 SG_ ExtrLtgStsPosLiFrnt : 55|2@0+ (1,0) [0|3] ""  TRM
 SG_ ExtrLtgStsPosLiRe : 53|2@0+ (1,0) [0|3] ""  TRM
 SG_ ExtrLtgStsReFog : 51|2@0+ (1,0) [0|3] ""  TRM
 SG_ ExtrLtgStsReverseLi : 49|2@0+ (1,0) [0|3] ""  TRM
 SG_ ExtrLtgStsStopLi : 63|2@0+ (1,0) [0|3] ""  TRM
 SG_ ExtrLtgStsTurnIndrLe : 61|2@0+ (1,0) [0|3] ""  TRM
 SG_ ExtrLtgStsTurnIndrRi : 59|2@0+ (1,0) [0|3] ""  TRM
 SG_ ExtrLtgStsWelcome : 57|2@0+ (1,0) [0|3] ""  TRM

BO_ 625 ZCUDZCUDCAN1Fr74: 8 ZCUD
 SG_ ActvnOfSymIllmn : 5|1@0+ (1,0) [0|1] "" Vector__XXX
 SG_ ActvnOfSymIllmn_UB : 4|1@0+ (1,0) [0|1] "" Vector__XXX
 SG_ CmptmtTRe_UB : 17|1@0+ (1,0) [0|1] "" Vector__XXX
 SG_ CmptmtTReCmptmtTFrnt : 15|11@0+ (0.1,-60) [-60|125] "degC" Vector__XXX
 SG_ CmptmtTReCmptmtTFrntQf : 20|2@0+ (1,0) [0|3] "" Vector__XXX
 SG_ CmptmtTReFanForCmptmtTRunng : 18|1@0+ (1,0) [0|1] "" Vector__XXX
 SG_ HmiSeatVentAutStrtRowThrdLe : 3|1@0+ (1,0) [0|1] "" Vector__XXX
 SG_ HmiSeatVentAutStrtRowThrdLe_UB : 2|1@0+ (1,0) [0|1] "" Vector__XXX
 SG_ HmiSeatVentAutStrtRowThrdRi : 1|1@0+ (1,0) [0|1] "" Vector__XXX
 SG_ HmiSeatVentAutStrtRowThrdRi_UB : 0|1@0+ (1,0) [0|1] "" Vector__XXX
 SG_ RcwmBeltReq : 50|2@0+ (1,0) [0|3] "" Vector__XXX
 SG_ RcwmBeltReq_UB : 48|1@0+ (1,0) [0|1] "" Vector__XXX
 SG_ SeatHeatRowThrdLeEna : 63|1@0+ (1,0) [0|1] "" Vector__XXX
 SG_ SeatHeatRowThrdLeEna_UB : 62|1@0+ (1,0) [0|1] "" Vector__XXX
 SG_ SeatHeatRowThrdRiEna : 61|1@0+ (1,0) [0|1] "" Vector__XXX
 SG_ SeatHeatRowThrdRiEna_UB : 60|1@0+ (1,0) [0|1] "" Vector__XXX
 SG_ SeatVentnRowSecLeEna : 59|1@0+ (1,0) [0|1] "" Vector__XXX
 SG_ SeatVentnRowSecLeEna_UB : 58|1@0+ (1,0) [0|1] "" Vector__XXX
 SG_ SeatVentnRowThrdLeEna : 57|1@0+ (1,0) [0|1] "" Vector__XXX
 SG_ SeatVentnRowThrdLeEna_UB : 56|1@0+ (1,0) [0|1] "" Vector__XXX
 SG_ SeatVentnRowThrdRiEna : 7|1@0+ (1,0) [0|1] "" Vector__XXX
 SG_ SeatVentnRowThrdRiEna_UB : 6|1@0+ (1,0) [0|1] "" Vector__XXX
 SG_ WinPosnStsAtPass : 55|5@0+ (1,0) [0|31] "" Vector__XXX
 SG_ WinPosnStsAtPass_UB : 40|1@0+ (1,0) [0|1] "" Vector__XXX

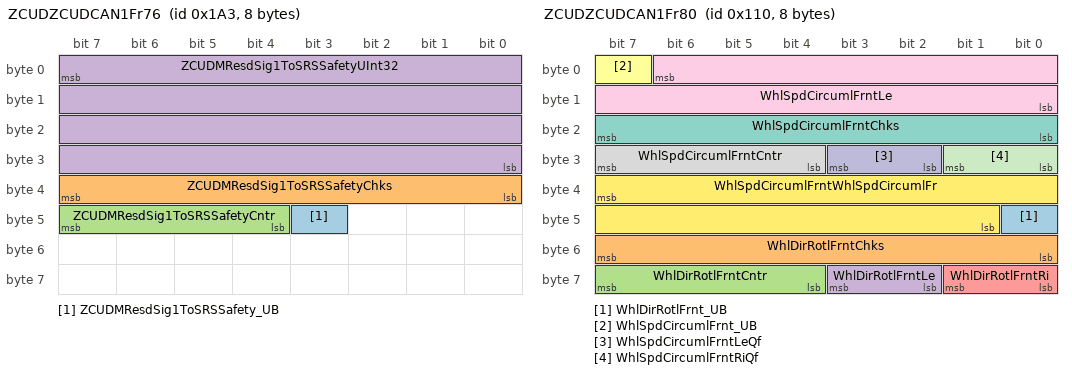
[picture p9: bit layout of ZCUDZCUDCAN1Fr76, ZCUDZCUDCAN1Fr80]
BO_ 419 ZCUDZCUDCAN1Fr76: 8 ZCUD
 SG_ ZCUDMResdSig1ToSRSSafety_UB : 43|1@0+ (1,0) [0|1] ""  SRS3
 SG_ ZCUDMResdSig1ToSRSSafetyChks : 39|8@0+ (1,0) [0|255] "Unitless"  SRS3
 SG_ ZCUDMResdSig1ToSRSSafetyCntr : 47|4@0+ (1,0) [0|15] "Unitless"  SRS3
 SG_ ZCUDMResdSig1ToSRSSafetyUInt32 : 7|32@0+ (1,0) [0|4294967295] "Unitless"  SRS3

BO_ 532 ZCUDZCUDCAN1Fr77: 8 ZCUD
 SG_ RoadIncln_UB : 11|1@0+ (1,0) [0|1] "" Vector__XXX
 SG_ RoadInclnQly : 47|2@0+ (1,0) [0|3] "" Vector__XXX
 SG_ RoadInclnRoadIncln : 31|16@0- (3.0518E-005,0) [-0.999983306|0.999983306] "rad" Vector__XXX
 SG_ SeatHeatRowSecLeEna : 44|1@0+ (1,0) [0|1] "" Vector__XXX
 SG_ SeatHeatRowSecLeEna_UB : 43|1@0+ (1,0) [0|1] "" Vector__XXX
 SG_ SeatHeatRowSecRiEna : 42|1@0+ (1,0) [0|1] "" Vector__XXX
 SG_ SeatHeatRowSecRiEna_UB : 41|1@0+ (1,0) [0|1] "" Vector__XXX
 SG_ SeatMassgFctDrvr_UB : 57|1@0+ (1,0) [0|1] "" Vector__XXX
 SG_ SeatMassgFctDrvrMassgInten : 60|2@0+ (1,0) [0|3] "" Vector__XXX
 SG_ SeatMassgFctDrvrMassgProg : 63|3@0+ (1,0) [0|7] "" Vector__XXX
 SG_ SeatMassgFctDrvrOnOff : 58|1@0+ (1,0) [0|1] "" Vector__XXX
 SG_ SeatMassgLumHeiCtrlDrvr : 15|2@0+ (1,0) [0|3] "" Vector__XXX
 SG_ SeatMassgLumHeiCtrlDrvr_UB : 13|1@0+ (1,0) [0|1] "" Vector__XXX
 SG_ SeatMassgLumMotrEnaDrvr : 10|2@0+ (1,0) [0|3] "" Vector__XXX
 SG_ SeatMassgLumMotrEnaDrvr_UB : 8|1@0+ (1,0) [0|1] "" Vector__XXX
 SG_ SeatMidLumPosCtrlDrvr : 7|7@0+ (1,0) [0|127] "%" Vector__XXX
 SG_ SeatMidLumPosCtrlDrvr_UB : 0|1@0+ (1,0) [0|1] "" Vector__XXX
 SG_ SeatUpLumPosCtrlDrvr : 23|7@0+ (1,0) [0|127] "%" Vector__XXX
 SG_ SeatUpLumPosCtrlDrvr_UB : 16|1@0+ (1,0) [0|1] "" Vector__XXX
 SG_ SeatVentnRowSecRiEna : 55|1@0+ (1,0) [0|1] "" Vector__XXX
 SG_ SeatVentnRowSecRiEna_UB : 54|1@0+ (1,0) [0|1] "" Vector__XXX

BO_ 431 ZCUDZCUDCAN1Fr78: 8 ZCUD
 SG_ RadioFrqAM : 7|11@0+ (1,522) [522|1710] "Unitless" Vector__XXX
 SG_ RadioFrqAM_UB : 12|1@0+ (1,0) [0|1] "" Vector__XXX
 SG_ ThrdLeSeatLumDisSts : 37|1@0+ (1,0) [0|1] "" Vector__XXX
 SG_ ThrdLeSeatLumDisSts_UB : 36|1@0+ (1,0) [0|1] "" Vector__XXX
 SG_ ThrdLeSeatMassDisSts : 35|1@0+ (1,0) [0|1] "" Vector__XXX
 SG_ ThrdLeSeatMassDisSts_UB : 34|1@0+ (1,0) [0|1] "" Vector__XXX
 SG_ ThrdLeSeatSideSpprtDisSts : 33|1@0+ (1,0) [0|1] "" Vector__XXX
 SG_ ThrdLeSeatSideSpprtDisSts_UB : 32|1@0+ (1,0) [0|1] "" Vector__XXX
 SG_ ThrdRiSeatLumDisSts : 47|1@0+ (1,0) [0|1] "" Vector__XXX
 SG_ ThrdRiSeatLumDisSts_UB : 46|1@0+ (1,0) [0|1] "" Vector__XXX
 SG_ ThrdRiSeatMassDisSts : 45|1@0+ (1,0) [0|1] "" Vector__XXX
 SG_ ThrdRiSeatMassDisSts_UB : 44|1@0+ (1,0) [0|1] "" Vector__XXX
 SG_ ThrdRiSeatSideSpprtDisSts : 43|1@0+ (1,0) [0|1] "" Vector__XXX
 SG_ ThrdRiSeatSideSpprtDisSts_UB : 42|1@0+ (1,0) [0|1] "" Vector__XXX
 SG_ ThrdRowLeSeatMotPosnCalReq : 29|1@0+ (1,0) [0|1] "" Vector__XXX
 SG_ ThrdRowLeSeatMotPosnCalReq_UB : 26|1@0+ (1,0) [0|1] "" Vector__XXX
 SG_ ThrdRowRiSeatMotPosnCalReq : 28|1@0+ (1,0) [0|1] "" Vector__XXX
 SG_ ThrdRowRiSeatMotPosnCalReq_UB : 27|1@0+ (1,0) [0|1] "" Vector__XXX
 SG_ WPRLActvReqFromHmi : 41|1@0+ (1,0) [0|1] "" Vector__XXX
 SG_ WPRLActvReqFromHmi_UB : 40|1@0+ (1,0) [0|1] "" Vector__XXX
 SG_ WPRRActvReqFromHmi : 55|1@0+ (1,0) [0|1] "" Vector__XXX
 SG_ WPRRActvReqFromHmi_UB : 54|1@0+ (1,0) [0|1] "" Vector__XXX

BO_ 272 ZCUDZCUDCAN1Fr80: 8 ZCUD
 SG_ WhlDirRotlFrnt_UB : 40|1@0+ (1,0) [0|1] ""  SRS3
 SG_ WhlDirRotlFrntChks : 55|8@0+ (1,0) [0|255] "Unitless"  SRS3
 SG_ WhlDirRotlFrntCntr : 63|4@0+ (1,0) [0|15] "Unitless"  SRS3
 SG_ WhlDirRotlFrntLe : 59|2@0+ (1,0) [0|3] ""  SRS3
 SG_ WhlDirRotlFrntRi : 57|2@0+ (1,0) [0|3] ""  SRS3
 SG_ WhlSpdCircumlFrnt_UB : 7|1@0+ (1,0) [0|1] ""  SRS3
 SG_ WhlSpdCircumlFrntChks : 23|8@0+ (1,0) [0|255] "Unitless"  SRS3
 SG_ WhlSpdCircumlFrntCntr : 31|4@0+ (1,0) [0|15] "Unitless"  SRS3
 SG_ WhlSpdCircumlFrntLe : 6|15@0+ (0.00391,0) [0|125.0027] "m/s"  SRS3
 SG_ WhlSpdCircumlFrntLeQf : 27|2@0+ (1,0) [0|3] ""  SRS3
 SG_ WhlSpdCircumlFrntRiQf : 25|2@0+ (1,0) [0|3] ""  SRS3
 SG_ WhlSpdCircumlFrntWhlSpdCircumlFr : 39|15@0+ (0.00391,0) [0|125.0027] "m/s"  SRS3

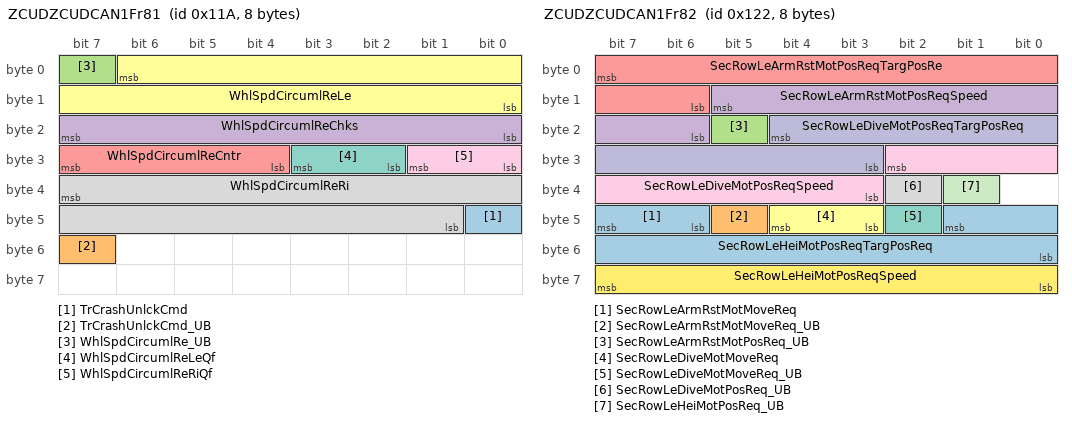
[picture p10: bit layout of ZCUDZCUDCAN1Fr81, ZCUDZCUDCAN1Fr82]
BO_ 282 ZCUDZCUDCAN1Fr81: 8 ZCUD
 SG_ TrCrashUnlckCmd : 40|1@0+ (1,0) [0|1] ""  POT
 SG_ TrCrashUnlckCmd_UB : 55|1@0+ (1,0) [0|1] ""  POT
 SG_ WhlSpdCircumlRe_UB : 7|1@0+ (1,0) [0|1] ""  SRS3
 SG_ WhlSpdCircumlReChks : 23|8@0+ (1,0) [0|255] "Unitless"  SRS3
 SG_ WhlSpdCircumlReCntr : 31|4@0+ (1,0) [0|15] "Unitless"  SRS3
 SG_ WhlSpdCircumlReLe : 6|15@0+ (0.00391,0) [0|125.0027] "m/s"  SRS3
 SG_ WhlSpdCircumlReLeQf : 27|2@0+ (1,0) [0|3] ""  SRS3
 SG_ WhlSpdCircumlReRi : 39|15@0+ (0.00391,0) [0|125.0027] "m/s"  SRS3
 SG_ WhlSpdCircumlReRiQf : 25|2@0+ (1,0) [0|3] ""  SRS3

BO_ 290 ZCUDZCUDCAN1Fr82: 8 ZCUD
 SG_ SecRowLeArmRstMotMoveReq : 47|2@0+ (1,0) [0|3] "" Vector__XXX
 SG_ SecRowLeArmRstMotMoveReq_UB : 45|1@0+ (1,0) [0|1] "" Vector__XXX
 SG_ SecRowLeArmRstMotPosReq_UB : 21|1@0+ (1,0) [0|1] "" Vector__XXX
 SG_ SecRowLeArmRstMotPosReqSpeed : 13|8@0+ (1,0) [0|255] "Unitless" Vector__XXX
 SG_ SecRowLeArmRstMotPosReqTargPosRe : 7|10@0+ (1,0) [0|1023] "Unitless" Vector__XXX
 SG_ SecRowLeDiveMotMoveReq : 44|2@0+ (1,0) [0|3] "" Vector__XXX
 SG_ SecRowLeDiveMotMoveReq_UB : 42|1@0+ (1,0) [0|1] "" Vector__XXX
 SG_ SecRowLeDiveMotPosReq_UB : 34|1@0+ (1,0) [0|1] "" Vector__XXX
 SG_ SecRowLeDiveMotPosReqSpeed : 26|8@0+ (1,0) [0|255] "Unitless" Vector__XXX
 SG_ SecRowLeDiveMotPosReqTargPosReq : 20|10@0+ (1,0) [0|1023] "Unitless" Vector__XXX
 SG_ SecRowLeHeiMotPosReq_UB : 33|1@0+ (1,0) [0|1] "" Vector__XXX
 SG_ SecRowLeHeiMotPosReqSpeed : 63|8@0+ (1,0) [0|255] "Unitless" Vector__XXX
 SG_ SecRowLeHeiMotPosReqTargPosReq : 41|10@0+ (1,0) [0|1023] "Unitless" Vector__XXX

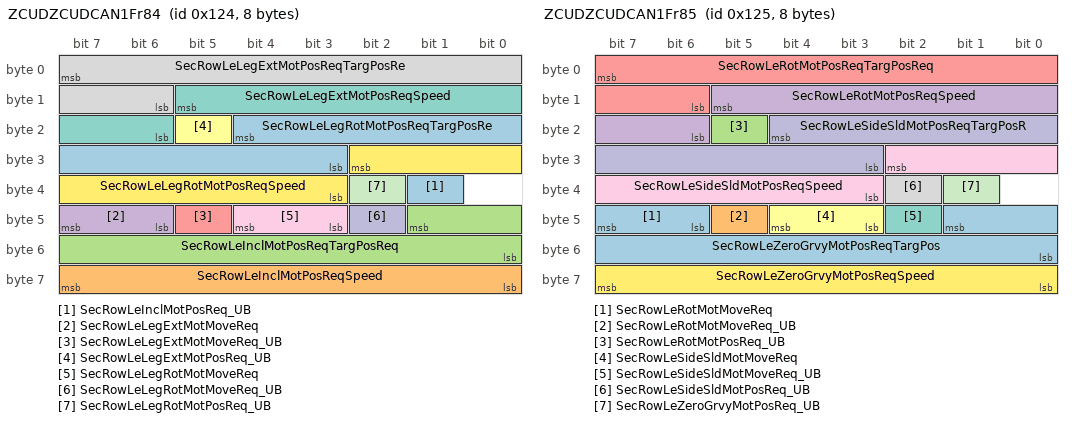
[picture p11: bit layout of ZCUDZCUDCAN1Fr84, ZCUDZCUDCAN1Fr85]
BO_ 292 ZCUDZCUDCAN1Fr84: 8 ZCUD
 SG_ SecRowLeInclMotPosReq_UB : 33|1@0+ (1,0) [0|1] "" Vector__XXX
 SG_ SecRowLeInclMotPosReqSpeed : 63|8@0+ (1,0) [0|255] "Unitless" Vector__XXX
 SG_ SecRowLeInclMotPosReqTargPosReq : 41|10@0+ (1,0) [0|1023] "Unitless" Vector__XXX
 SG_ SecRowLeLegExtMotMoveReq : 47|2@0+ (1,0) [0|3] "" Vector__XXX
 SG_ SecRowLeLegExtMotMoveReq_UB : 45|1@0+ (1,0) [0|1] "" Vector__XXX
 SG_ SecRowLeLegExtMotPosReq_UB : 21|1@0+ (1,0) [0|1] "" Vector__XXX
 SG_ SecRowLeLegExtMotPosReqSpeed : 13|8@0+ (1,0) [0|255] "Unitless" Vector__XXX
 SG_ SecRowLeLegExtMotPosReqTargPosRe : 7|10@0+ (1,0) [0|1023] "Unitless" Vector__XXX
 SG_ SecRowLeLegRotMotMoveReq : 44|2@0+ (1,0) [0|3] "" Vector__XXX
 SG_ SecRowLeLegRotMotMoveReq_UB : 42|1@0+ (1,0) [0|1] "" Vector__XXX
 SG_ SecRowLeLegRotMotPosReq_UB : 34|1@0+ (1,0) [0|1] "" Vector__XXX
 SG_ SecRowLeLegRotMotPosReqSpeed : 26|8@0+ (1,0) [0|255] "Unitless" Vector__XXX
 SG_ SecRowLeLegRotMotPosReqTargPosRe : 20|10@0+ (1,0) [0|1023] "Unitless" Vector__XXX

BO_ 293 ZCUDZCUDCAN1Fr85: 8 ZCUD
 SG_ SecRowLeRotMotMoveReq : 47|2@0+ (1,0) [0|3] "" Vector__XXX
 SG_ SecRowLeRotMotMoveReq_UB : 45|1@0+ (1,0) [0|1] "" Vector__XXX
 SG_ SecRowLeRotMotPosReq_UB : 21|1@0+ (1,0) [0|1] "" Vector__XXX
 SG_ SecRowLeRotMotPosReqSpeed : 13|8@0+ (1,0) [0|255] "Unitless" Vector__XXX
 SG_ SecRowLeRotMotPosReqTargPosReq : 7|10@0+ (1,0) [0|1023] "Unitless" Vector__XXX
 SG_ SecRowLeSideSldMotMoveReq : 44|2@0+ (1,0) [0|3] "" Vector__XXX
 SG_ SecRowLeSideSldMotMoveReq_UB : 42|1@0+ (1,0) [0|1] "" Vector__XXX
 SG_ SecRowLeSideSldMotPosReq_UB : 34|1@0+ (1,0) [0|1] "" Vector__XXX
 SG_ SecRowLeSideSldMotPosReqSpeed : 26|8@0+ (1,0) [0|255] "Unitless" Vector__XXX
 SG_ SecRowLeSideSldMotPosReqTargPosR : 20|10@0+ (1,0) [0|1023] "Unitless" Vector__XXX
 SG_ SecRowLeZeroGrvyMotPosReq_UB : 33|1@0+ (1,0) [0|1] "" Vector__XXX
 SG_ SecRowLeZeroGrvyMotPosReqSpeed : 63|8@0+ (1,0) [0|255] "Unitless" Vector__XXX
 SG_ SecRowLeZeroGrvyMotPosReqTargPos : 41|10@0+ (1,0) [0|1023] "Unitless" Vector__XXX

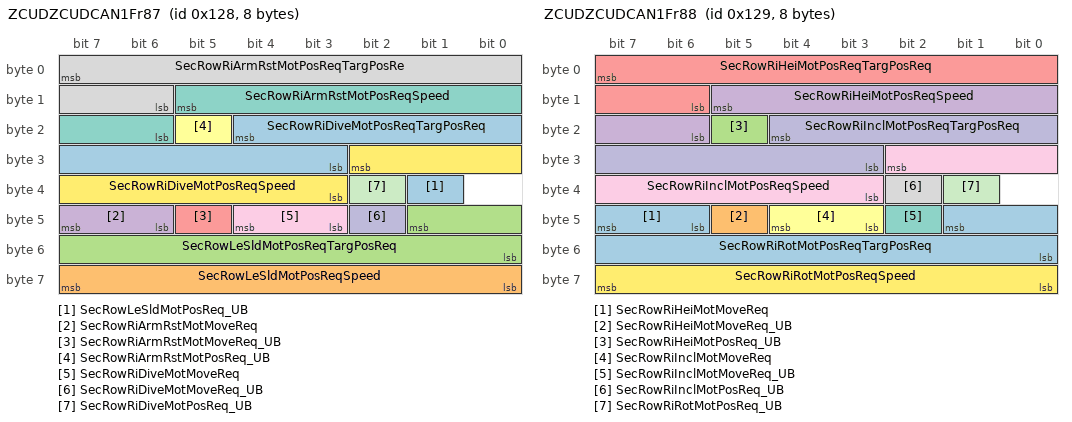
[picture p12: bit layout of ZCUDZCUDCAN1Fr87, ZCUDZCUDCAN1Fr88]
BO_ 296 ZCUDZCUDCAN1Fr87: 8 ZCUD
 SG_ SecRowLeSldMotPosReq_UB : 33|1@0+ (1,0) [0|1] "" Vector__XXX
 SG_ SecRowLeSldMotPosReqSpeed : 63|8@0+ (1,0) [0|255] "Unitless" Vector__XXX
 SG_ SecRowLeSldMotPosReqTargPosReq : 41|10@0+ (1,0) [0|1023] "Unitless" Vector__XXX
 SG_ SecRowRiArmRstMotMoveReq : 47|2@0+ (1,0) [0|3] "" Vector__XXX
 SG_ SecRowRiArmRstMotMoveReq_UB : 45|1@0+ (1,0) [0|1] "" Vector__XXX
 SG_ SecRowRiArmRstMotPosReq_UB : 21|1@0+ (1,0) [0|1] "" Vector__XXX
 SG_ SecRowRiArmRstMotPosReqSpeed : 13|8@0+ (1,0) [0|255] "Unitless" Vector__XXX
 SG_ SecRowRiArmRstMotPosReqTargPosRe : 7|10@0+ (1,0) [0|1023] "Unitless" Vector__XXX
 SG_ SecRowRiDiveMotMoveReq : 44|2@0+ (1,0) [0|3] "" Vector__XXX
 SG_ SecRowRiDiveMotMoveReq_UB : 42|1@0+ (1,0) [0|1] "" Vector__XXX
 SG_ SecRowRiDiveMotPosReq_UB : 34|1@0+ (1,0) [0|1] "" Vector__XXX
 SG_ SecRowRiDiveMotPosReqSpeed : 26|8@0+ (1,0) [0|255] "Unitless" Vector__XXX
 SG_ SecRowRiDiveMotPosReqTargPosReq : 20|10@0+ (1,0) [0|1023] "Unitless" Vector__XXX

BO_ 297 ZCUDZCUDCAN1Fr88: 8 ZCUD
 SG_ SecRowRiHeiMotMoveReq : 47|2@0+ (1,0) [0|3] "" Vector__XXX
 SG_ SecRowRiHeiMotMoveReq_UB : 45|1@0+ (1,0) [0|1] "" Vector__XXX
 SG_ SecRowRiHeiMotPosReq_UB : 21|1@0+ (1,0) [0|1] "" Vector__XXX
 SG_ SecRowRiHeiMotPosReqSpeed : 13|8@0+ (1,0) [0|255] "Unitless" Vector__XXX
 SG_ SecRowRiHeiMotPosReqTargPosReq : 7|10@0+ (1,0) [0|1023] "Unitless" Vector__XXX
 SG_ SecRowRiInclMotMoveReq : 44|2@0+ (1,0) [0|3] "" Vector__XXX
 SG_ SecRowRiInclMotMoveReq_UB : 42|1@0+ (1,0) [0|1] "" Vector__XXX
 SG_ SecRowRiInclMotPosReq_UB : 34|1@0+ (1,0) [0|1] "" Vector__XXX
 SG_ SecRowRiInclMotPosReqSpeed : 26|8@0+ (1,0) [0|255] "Unitless" Vector__XXX
 SG_ SecRowRiInclMotPosReqTargPosReq : 20|10@0+ (1,0) [0|1023] "Unitless" Vector__XXX
 SG_ SecRowRiRotMotPosReq_UB : 33|1@0+ (1,0) [0|1] "" Vector__XXX
 SG_ SecRowRiRotMotPosReqSpeed : 63|8@0+ (1,0) [0|255] "Unitless" Vector__XXX
 SG_ SecRowRiRotMotPosReqTargPosReq : 41|10@0+ (1,0) [0|1023] "Unitless" Vector__XXX

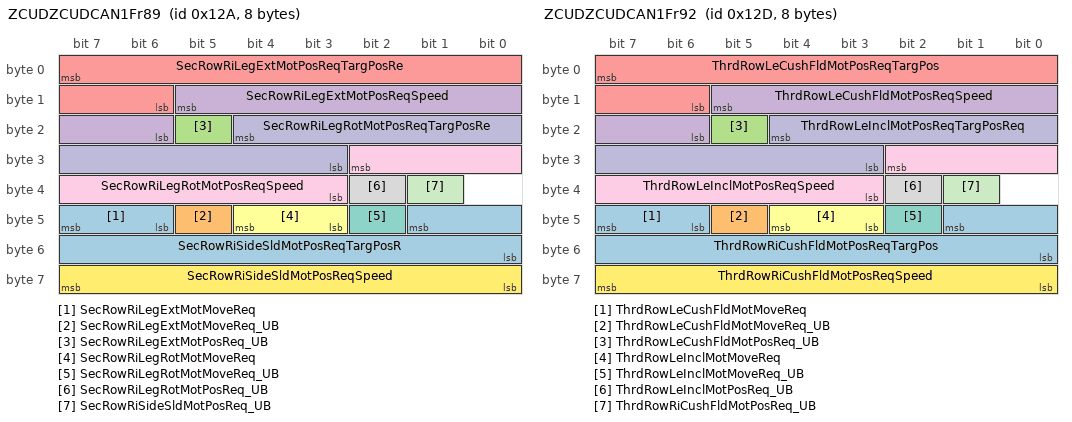
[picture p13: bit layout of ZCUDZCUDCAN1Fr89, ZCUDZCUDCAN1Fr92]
BO_ 298 ZCUDZCUDCAN1Fr89: 8 ZCUD
 SG_ SecRowRiLegExtMotMoveReq : 47|2@0+ (1,0) [0|3] "" Vector__XXX
 SG_ SecRowRiLegExtMotMoveReq_UB : 45|1@0+ (1,0) [0|1] "" Vector__XXX
 SG_ SecRowRiLegExtMotPosReq_UB : 21|1@0+ (1,0) [0|1] "" Vector__XXX
 SG_ SecRowRiLegExtMotPosReqSpeed : 13|8@0+ (1,0) [0|255] "Unitless" Vector__XXX
 SG_ SecRowRiLegExtMotPosReqTargPosRe : 7|10@0+ (1,0) [0|1023] "Unitless" Vector__XXX
 SG_ SecRowRiLegRotMotMoveReq : 44|2@0+ (1,0) [0|3] "" Vector__XXX
 SG_ SecRowRiLegRotMotMoveReq_UB : 42|1@0+ (1,0) [0|1] "" Vector__XXX
 SG_ SecRowRiLegRotMotPosReq_UB : 34|1@0+ (1,0) [0|1] "" Vector__XXX
 SG_ SecRowRiLegRotMotPosReqSpeed : 26|8@0+ (1,0) [0|255] "Unitless" Vector__XXX
 SG_ SecRowRiLegRotMotPosReqTargPosRe : 20|10@0+ (1,0) [0|1023] "Unitless" Vector__XXX
 SG_ SecRowRiSideSldMotPosReq_UB : 33|1@0+ (1,0) [0|1] "" Vector__XXX
 SG_ SecRowRiSideSldMotPosReqSpeed : 63|8@0+ (1,0) [0|255] "Unitless" Vector__XXX
 SG_ SecRowRiSideSldMotPosReqTargPosR : 41|10@0+ (1,0) [0|1023] "Unitless" Vector__XXX

BO_ 300 ZCUDZCUDCAN1Fr91: 8 ZCUD
 SG_ SecRowLeHeiMotMoveReq : 41|2@0+ (1,0) [0|3] "" Vector__XXX
 SG_ SecRowLeHeiMotMoveReq_UB : 55|1@0+ (1,0) [0|1] "" Vector__XXX
 SG_ SecRowLeInclMotMoveReq : 54|2@0+ (1,0) [0|3] "" Vector__XXX
 SG_ SecRowLeInclMotMoveReq_UB : 52|1@0+ (1,0) [0|1] "" Vector__XXX
 SG_ SecRowLeSldMotMoveReq : 51|2@0+ (1,0) [0|3] "" Vector__XXX
 SG_ SecRowLeSldMotMoveReq_UB : 49|1@0+ (1,0) [0|1] "" Vector__XXX
 SG_ SecRowLeZeroGrvyMotMoveReq : 48|2@0+ (1,0) [0|3] "" Vector__XXX
 SG_ SecRowLeZeroGrvyMotMoveReq_UB : 62|1@0+ (1,0) [0|1] "" Vector__XXX
 SG_ SecRowRiRotMotMoveReq : 61|2@0+ (1,0) [0|3] "" Vector__XXX
 SG_ SecRowRiRotMotMoveReq_UB : 59|1@0+ (1,0) [0|1] "" Vector__XXX
 SG_ SecRowRiSideSldMotMoveReq : 58|2@0+ (1,0) [0|3] "" Vector__XXX
 SG_ SecRowRiSideSldMotMoveReq_UB : 56|1@0+ (1,0) [0|1] "" Vector__XXX
 SG_ SecRowRiSldMotMoveReq : 47|2@0+ (1,0) [0|3] "" Vector__XXX
 SG_ SecRowRiSldMotMoveReq_UB : 45|1@0+ (1,0) [0|1] "" Vector__XXX
 SG_ SecRowRiSldMotPosReq_UB : 21|1@0+ (1,0) [0|1] "" Vector__XXX
 SG_ SecRowRiSldMotPosReqSpeed : 13|8@0+ (1,0) [0|255] "Unitless" Vector__XXX
 SG_ SecRowRiSldMotPosReqTargPosReq : 7|10@0+ (1,0) [0|1023] "Unitless" Vector__XXX
 SG_ SecRowRiZeroGrvyMotMoveReq : 44|2@0+ (1,0) [0|3] "" Vector__XXX
 SG_ SecRowRiZeroGrvyMotMoveReq_UB : 42|1@0+ (1,0) [0|1] "" Vector__XXX
 SG_ SecRowRiZeroGrvyMotPosReq_UB : 34|1@0+ (1,0) [0|1] "" Vector__XXX
 SG_ SecRowRiZeroGrvyMotPosReqSpeed : 26|8@0+ (1,0) [0|255] "Unitless" Vector__XXX
 SG_ SecRowRiZeroGrvyMotPosReqTargPos : 20|10@0+ (1,0) [0|1023] "Unitless" Vector__XXX

BO_ 301 ZCUDZCUDCAN1Fr92: 8 ZCUD
 SG_ ThrdRowLeCushFldMotMoveReq : 47|2@0+ (1,0) [0|3] "" Vector__XXX
 SG_ ThrdRowLeCushFldMotMoveReq_UB : 45|1@0+ (1,0) [0|1] "" Vector__XXX
 SG_ ThrdRowLeCushFldMotPosReq_UB : 21|1@0+ (1,0) [0|1] "" Vector__XXX
 SG_ ThrdRowLeCushFldMotPosReqSpeed : 13|8@0+ (1,0) [0|255] "Unitless" Vector__XXX
 SG_ ThrdRowLeCushFldMotPosReqTargPos : 7|10@0+ (1,0) [0|1023] "Unitless" Vector__XXX
 SG_ ThrdRowLeInclMotMoveReq : 44|2@0+ (1,0) [0|3] "" Vector__XXX
 SG_ ThrdRowLeInclMotMoveReq_UB : 42|1@0+ (1,0) [0|1] "" Vector__XXX
 SG_ ThrdRowLeInclMotPosReq_UB : 34|1@0+ (1,0) [0|1] "" Vector__XXX
 SG_ ThrdRowLeInclMotPosReqSpeed : 26|8@0+ (1,0) [0|255] "Unitless" Vector__XXX
 SG_ ThrdRowLeInclMotPosReqTargPosReq : 20|10@0+ (1,0) [0|1023] "Unitless" Vector__XXX
 SG_ ThrdRowRiCushFldMotPosReq_UB : 33|1@0+ (1,0) [0|1] "" Vector__XXX
 SG_ ThrdRowRiCushFldMotPosReqSpeed : 63|8@0+ (1,0) [0|255] "Unitless" Vector__XXX
 SG_ ThrdRowRiCushFldMotPosReqTargPos : 41|10@0+ (1,0) [0|1023] "Unitless" Vector__XXX

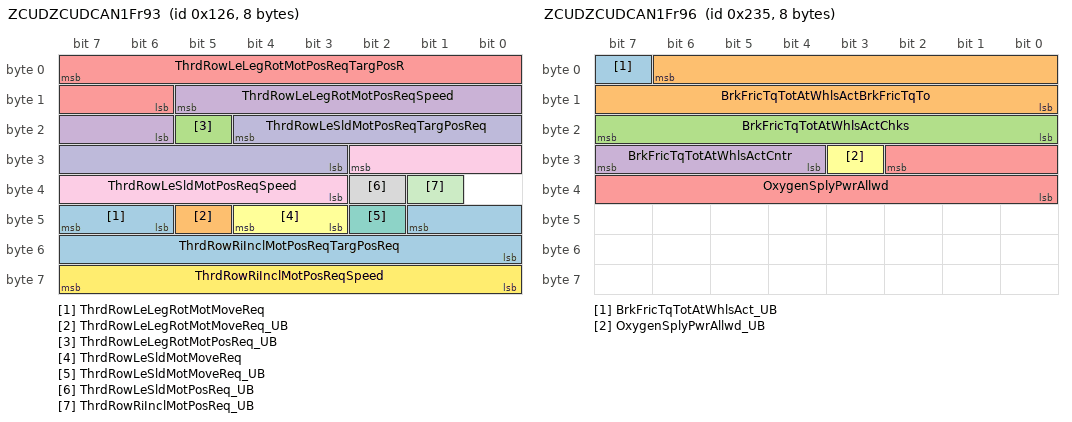
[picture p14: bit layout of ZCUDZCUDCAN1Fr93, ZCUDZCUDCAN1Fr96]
BO_ 294 ZCUDZCUDCAN1Fr93: 8 ZCUD
 SG_ ThrdRowLeLegRotMotMoveReq : 47|2@0+ (1,0) [0|3] "" Vector__XXX
 SG_ ThrdRowLeLegRotMotMoveReq_UB : 45|1@0+ (1,0) [0|1] "" Vector__XXX
 SG_ ThrdRowLeLegRotMotPosReq_UB : 21|1@0+ (1,0) [0|1] "" Vector__XXX
 SG_ ThrdRowLeLegRotMotPosReqSpeed : 13|8@0+ (1,0) [0|255] "Unitless" Vector__XXX
 SG_ ThrdRowLeLegRotMotPosReqTargPosR : 7|10@0+ (1,0) [0|1023] "Unitless" Vector__XXX
 SG_ ThrdRowLeSldMotMoveReq : 44|2@0+ (1,0) [0|3] "" Vector__XXX
 SG_ ThrdRowLeSldMotMoveReq_UB : 42|1@0+ (1,0) [0|1] "" Vector__XXX
 SG_ ThrdRowLeSldMotPosReq_UB : 34|1@0+ (1,0) [0|1] "" Vector__XXX
 SG_ ThrdRowLeSldMotPosReqSpeed : 26|8@0+ (1,0) [0|255] "Unitless" Vector__XXX
 SG_ ThrdRowLeSldMotPosReqTargPosReq : 20|10@0+ (1,0) [0|1023] "Unitless" Vector__XXX
 SG_ ThrdRowRiInclMotPosReq_UB : 33|1@0+ (1,0) [0|1] "" Vector__XXX
 SG_ ThrdRowRiInclMotPosReqSpeed : 63|8@0+ (1,0) [0|255] "Unitless" Vector__XXX
 SG_ ThrdRowRiInclMotPosReqTargPosReq : 41|10@0+ (1,0) [0|1023] "Unitless" Vector__XXX

BO_ 303 ZCUDZCUDCAN1Fr95: 8 ZCUD
 SG_ SecRowLeRotLckMotMoveReq : 55|2@0+ (1,0) [0|3] "" Vector__XXX
 SG_ SecRowLeRotLckMotMoveReq_UB : 53|1@0+ (1,0) [0|1] "" Vector__XXX
 SG_ SecRowRiRotLckMotMoveReq : 52|2@0+ (1,0) [0|3] "" Vector__XXX
 SG_ SecRowRiRotLckMotMoveReq_UB : 50|1@0+ (1,0) [0|1] "" Vector__XXX
 SG_ ThrdRowLeCushFldLckMotReq : 63|2@0+ (1,0) [0|3] "" Vector__XXX
 SG_ ThrdRowLeCushFldLckMotReq_UB : 61|1@0+ (1,0) [0|1] "" Vector__XXX
 SG_ ThrdRowRiCushFldLckMotReq : 60|2@0+ (1,0) [0|3] "" Vector__XXX
 SG_ ThrdRowRiCushFldLckMotReq_UB : 58|1@0+ (1,0) [0|1] "" Vector__XXX
 SG_ ThrdRowRiCushFldMotMoveReq : 33|2@0+ (1,0) [0|3] "" Vector__XXX
 SG_ ThrdRowRiCushFldMotMoveReq_UB : 49|1@0+ (1,0) [0|1] "" Vector__XXX
 SG_ ThrdRowRiInclMotMoveReq : 41|2@0+ (1,0) [0|3] "" Vector__XXX
 SG_ ThrdRowRiInclMotMoveReq_UB : 48|1@0+ (1,0) [0|1] "" Vector__XXX
 SG_ ThrdRowRiLegRotMotMoveReq : 47|2@0+ (1,0) [0|3] "" Vector__XXX
 SG_ ThrdRowRiLegRotMotMoveReq_UB : 45|1@0+ (1,0) [0|1] "" Vector__XXX
 SG_ ThrdRowRiLegRotMotPosReq_UB : 21|1@0+ (1,0) [0|1] "" Vector__XXX
 SG_ ThrdRowRiLegRotMotPosReqSpeed : 13|8@0+ (1,0) [0|255] "Unitless" Vector__XXX
 SG_ ThrdRowRiLegRotMotPosReqTargPosR : 7|10@0+ (1,0) [0|1023] "Unitless" Vector__XXX
 SG_ ThrdRowRiSldMotMoveReq : 44|2@0+ (1,0) [0|3] "" Vector__XXX
 SG_ ThrdRowRiSldMotMoveReq_UB : 42|1@0+ (1,0) [0|1] "" Vector__XXX
 SG_ ThrdRowRiSldMotPosReq_UB : 34|1@0+ (1,0) [0|1] "" Vector__XXX
 SG_ ThrdRowRiSldMotPosReqSpeed : 26|8@0+ (1,0) [0|255] "Unitless" Vector__XXX
 SG_ ThrdRowRiSldMotPosReqTargPosReq : 20|10@0+ (1,0) [0|1023] "Unitless" Vector__XXX

BO_ 565 ZCUDZCUDCAN1Fr96: 8 ZCUD
 SG_ BrkFricTqTotAtWhlsAct_UB : 7|1@0+ (1,0) [0|1] ""  SRS3
 SG_ BrkFricTqTotAtWhlsActBrkFricTqTo : 6|15@0+ (1,0) [0|20000] "NewtonMeter"  SRS3
 SG_ BrkFricTqTotAtWhlsActChks : 23|8@0+ (1,0) [0|255] "Unitless"  SRS3
 SG_ BrkFricTqTotAtWhlsActCntr : 31|4@0+ (1,0) [0|15] "Unitless"  SRS3
 SG_ OxygenSplyPwrAllwd : 26|11@0+ (1,0) [0|2047] "W"  OGM
 SG_ OxygenSplyPwrAllwd_UB : 27|1@0+ (1,0) [0|1] ""  OGM

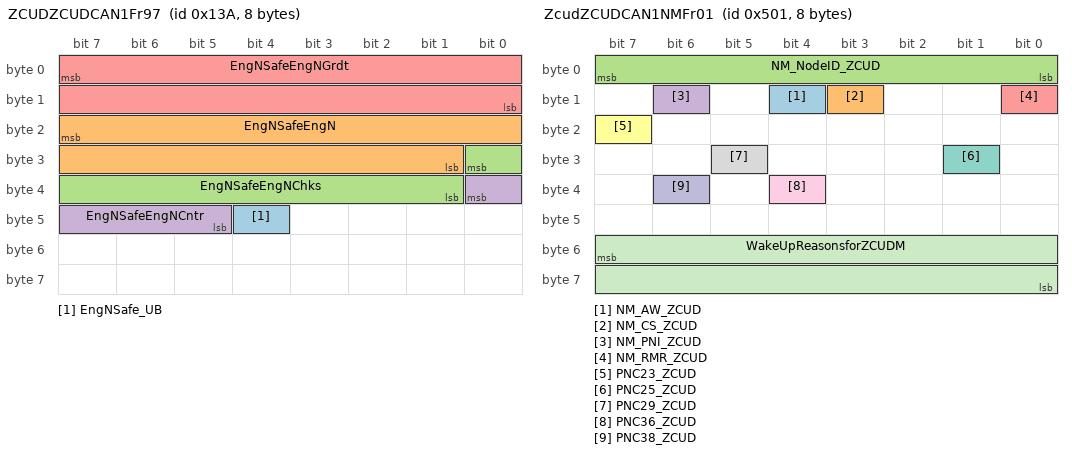
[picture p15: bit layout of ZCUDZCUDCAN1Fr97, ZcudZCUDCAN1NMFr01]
BO_ 314 ZCUDZCUDCAN1Fr97: 8 ZCUD
 SG_ EngNSafe_UB : 44|1@0+ (1,0) [0|1] ""  SRS3
 SG_ EngNSafeEngN : 23|15@0+ (0.5,0) [0|16383.5] "rpm"  SRS3
 SG_ EngNSafeEngNChks : 24|8@0+ (1,0) [0|255] "Unitless"  SRS3
 SG_ EngNSafeEngNCntr : 32|4@0+ (1,0) [0|15] "Unitless"  SRS3
 SG_ EngNSafeEngNGrdt : 7|16@0- (1,0) [-30000|32767] "RpmPerSec"  SRS3

BO_ 1281 ZcudZCUDCAN1NMFr01: 8 ZCUD
 SG_ NM_AW_ZCUD : 12|1@0+ (1,0) [0|0] ""  TRM
 SG_ NM_CS_ZCUD : 11|1@0+ (1,0) [0|0] ""  TRM
 SG_ NM_NodeID_ZCUD : 7|8@0+ (1,0) [0|0] ""  TRM
 SG_ NM_PNI_ZCUD : 14|1@0+ (1,0) [0|0] ""  TRM
 SG_ NM_RMR_ZCUD : 8|1@0+ (1,0) [0|0] ""  TRM
 SG_ PNC23_ZCUD : 23|1@0+ (1,0) [0|0] ""  TRM
 SG_ PNC25_ZCUD : 25|1@0+ (1,0) [0|0] ""  TRM
 SG_ PNC29_ZCUD : 29|1@0+ (1,0) [0|0] ""  TRM
 SG_ PNC36_ZCUD : 36|1@0+ (1,0) [0|0] ""  TRM
 SG_ PNC38_ZCUD : 38|1@0+ (1,0) [0|0] ""  TRM
 SG_ WakeUpReasonsforZCUDM : 55|16@0+ (1,0) [0|65535] "" Vector__XXX

CM_ SG_ 792 VehCfgPrmExt2BlkIDBytePosn1 "CarConfigExtended2 BlockID";
CM_ SG_ 792 VehCfgPrmExt2CCPBytePosn2 "CarConfigExtended2 BytePos2";
CM_ SG_ 792 VehCfgPrmExt2CCPBytePosn3 "CarConfigExtended2 BytePos3";
CM_ SG_ 792 VehCfgPrmExt2CCPBytePosn4 "CarConfigExtended2 BytePos4";
CM_ SG_ 792 VehCfgPrmExt2CCPBytePosn5 "CarConfigExtended2 BytePos5";
CM_ SG_ 792 VehCfgPrmExt2CCPBytePosn6 "CarConfigExtended2 BytePos6";
CM_ SG_ 792 VehCfgPrmExt2CCPBytePosn7 "CarConfigExtended2 BytePos7";
CM_ SG_ 792 VehCfgPrmExt2CCPBytePosn8 "CarConfigExtended2 BytePos8";
CM_ SG_ 133 CllsnWarnReIndcn "Request to activate collision warning against rear object";
CM_ SG_ 133 RctaIndcnLe "RCTA left warning signal";
CM_ SG_ 133 RctaIndcnRi "RCTA right warning signal";
CM_ SG_ 849 AmbTIndcdWithUnitAmbTIndcd "Indicated ambient temperature";
CM_ SG_ 849 AmbTIndcdWithUnitAmbTIndcdUnit "Unit of the indicated temperature";
CM_ SG_ 849 AmbTIndcdWithUnitQF "QF";
CM_ SG_ 849 BrkTqAtWhlsReq "Contains driver requested brake torque and driver support system requested brake torque. The signal is always positive and acts in opposite vehicle motion direction.";
CM_ SG_ 849 CrsCtrlrMsg "The signal triggers visual messages in DIM to inform the driver relevant information about the Cruise Controller";
CM_ SG_ 849 RMLCmftFctReq "Whether the electrical seatbelt comfort functions is turned ON or OFF by the driver";
CM_ SG_ 849 RMRCmftFctReq "Whether the electrical seatbelt comfort functions is turned ON or OFF by the passenger";
CM_ SG_ 849 TurnIndcrAndHwlByDrvInt "Combine turn switch signals and hazard lights signal";
CM_ SG_ 528 ADTakeoverReqGroupADTakeoverAudi "This is to send audio notifications to alert the driver.";
CM_ SG_ 528 ADTakeoverReqGroupADTakeoverMsg "This message group contains messages that ask driver to pay attention to road, or take over the vehicle.";
CM_ SG_ 528 ADTakeoverReqGroupChks "E2E protect";
CM_ SG_ 528 ADTakeoverReqGroupCntr "E2E protect";
CM_ SG_ 528 AsySftyFctStsToEDRACCFctSTs "The signal indicates the function status of the ACC function.";
CM_ SG_ 528 AsySftyFctStsToEDRACSFB1FctSts "The signal indicates the function status of the HWA function.";
CM_ SG_ 528 AsySftyFctStsToEDRACSFB2FctSts "The signal indicates the function status of the ACSF B2.";
CM_ SG_ 528 AsySftyFctStsToEDRACSFCFctSts "The signal indicates the function status of the ALCA function.";
CM_ SG_ 528 AsySftyFctStsToEDRACSFDFctSts "The signal indicates the function status of the ACSF D.";
CM_ SG_ 528 AsySftyFctStsToEDRACSFEFctSts "The signal indicates the function status of the ACSF E.";
CM_ SG_ 528 AsySftyFctStsToEDRAEBSFctSts "The signal indicates the function status of the AEB and FCW function.";
CM_ SG_ 528 AsySftyFctStsToEDRCSFFctSts "The signal indicates the function status of the LKA function.";
CM_ SG_ 528 AsySftyFctStsToEDRESFFctSts "The signal indicates the function status of the ELKA function.";
CM_ SG_ 528 AsySftyFctStsToEDRLDWSFctSts "The signal indicates the function status of the LDW function.";
CM_ SG_ 528 SeatDownLumPosCtrlDrvr "Control lumbar air for bottom part of the driver seat";
CM_ SG_ 80 PreCrashFrontDataChks "crc";
CM_ SG_ 80 PreCrashFrontDataClosingVelocity "collision relative velocity";
CM_ SG_ 80 PreCrashFrontDataCntr "counter";
CM_ SG_ 80 PreCrashFrontDataObjectClass "object type";
CM_ SG_ 80 PreCrashFrontDataOverLap "overlap";
CM_ SG_ 80 PreCrashFrontDataTimeToImpact "time to impact";
CM_ SG_ 521 DrvrSeatAdpvSideSpprtSetg "driver seat adaptive side support setting";
CM_ SG_ 521 DrvrSeatSideSpprtSetg "Driver adaptive side wing adjustment switch on/off";
CM_ SG_ 521 HmiSeatHeatAutStrtRowSecLe "HmiSeatHeatAutStrtRowSecLe";
CM_ SG_ 521 HmiSeatHeatAutStrtRowSecRi "HmiSeatHeatAutStrtRowSecRi";
CM_ SG_ 521 HmiSeatHeatAutStrtRowThrdLe "HmiSeatHeatAutStrtRowThrdLe";
CM_ SG_ 521 HmiSeatHeatAutStrtRowThrdRi "HmiSeatHeatAutStrtRowThrdRi";
CM_ SG_ 521 HmiSeatVentAutStrtRowSecLe "HmiSeatVentAutStrtRowSecLe";
CM_ SG_ 521 HmiSeatVentAutStrtRowSecRi "HmiSeatVentAutStrtRowSecRi";
CM_ SG_ 521 SeatClimaDurgClimaHmiSeatHeatgFo "Used to activate seat heating during parking climatisation.";
CM_ SG_ 521 SeatClimaDurgClimaHmiSeatHe_0001 "Used to activate seat heating during parking climatisation.";
CM_ SG_ 521 SeatClimaDurgClimaHmiSeatVentnFo "Used to activate seat ventilation during parking climatisation.";
CM_ SG_ 521 SeatClimaDurgClimaHmiSeatVe_0001 "Used to activate seat ventilation during parking climatisation.";
CM_ SG_ 521 SeatMassgBackBlstrCtrlDrvr "Backrest Bolster Control";
CM_ SG_ 521 SeatMassgBackBlstrEnaDrvr "Backrest Bolster Enable";
CM_ SG_ 521 SeatMassgCushBlstrCtrlDrvr "Cushion Bolster Control";
CM_ SG_ 521 SeatMassgCushBlstrEnaDrvr "Cushion Bolster Enable";
CM_ SG_ 521 SeatMassgCushLiftCtrlDrvr "Used by air cell adjustment, trigger to deflate or inflate the cushion air cells automatically.";
CM_ SG_ 521 SeatMassgCushLiftEnaDrvr "Configuration signal to tell the massage module if it should expect cushion lift components.";
CM_ SG_ 521 SeatMassgLumExtnCtrlDrvr "Used by air cell adjustment, deflate or inflate the lumbar air cells.";
CM_ SG_ 521 WhlMotSysSpdAct "The actual rotational speed of rear motor";
CM_ SG_ 788 ChdLockPassReSts "Child protection Passenger rear door, child lock status.";
CM_ SG_ 788 HoodLatchPosn "Hood latch position status";
CM_ SG_ 788 HoodOpenerReqChks "Signal checksum";
CM_ SG_ 788 HoodOpenerReqCntr "Signal counter";
CM_ SG_ 788 HoodOpenerReqDoorOpenerReq "Hood opener request";
CM_ SG_ 788 HoodOpenerReqTrigSrc "Hood opener request trigger source";
CM_ SG_ 788 Overlap "predicted Object Overlap, i.e. the portion of the ego vehicle covered by the collision object, is between 25% and 100%.";
CM_ SG_ 1137 CmptmtOxygenConcVluFrmClima "Oxygen concentration information from Oxygen concentration sensor.";
CM_ SG_ 1137 VehHomePrkgSysSts "Home zone parking system status.";
CM_ SG_ 819 IndcrPatCmd1WdTiOff "Used for Hazard Sleep (subfunction to Hazard Warning Light).

This signal holds the pattern of the flashing to use when buses are asleep and TRM/DCUs shall flash synchronized by themselves.

Holds both on and off timing in two separate record items. HWL Off time";
CM_ SG_ 819 IndcrPatCmd1WdTiOn "Used for Hazard Sleep (subfunction to Hazard Warning Light).

This signal holds the pattern of the flashing to use when buses are asleep and TRM/DCUs shall flash synchronized by themselves.

Holds both on and off timing in two separate record items. HWL On time";
CM_ SG_ 819 SecRowLeInclPosAngleDeg180 "Second row left seat inclination position";
CM_ SG_ 819 SecRowLeInclPosQf1 "Qf";
CM_ SG_ 819 SecRowRiInclPosAngleDeg180 "Second row right seat inclination position";
CM_ SG_ 819 SecRowRiInclPosQf1 "Qf";
CM_ SG_ 289 CmptmtTFrntCmptmtTFrnt "Measured temperature in compartment. ";
CM_ SG_ 289 CmptmtTFrntFanForCmptmtTRunng "Fan for component temperature requirement.";
CM_ SG_ 289 CmptmtTFrntQf "Component temperature sensor signal quality.";
CM_ SG_ 289 PassSeatFoldSwt "Passenger seat folding switch";
CM_ SG_ 289 PassSeatUnfoldSwt "Passenger seat expansion switch";
CM_ SG_ 1168 AmbTEstimdAmbTEstimd "Estimated/filtered/modelled amibient temperature based on information from ambient temp sensor and all other available temperature sensors and vehicle information.  Estimated ambient temperature";
CM_ SG_ 1168 AmbTEstimdQf "Estimated/filtered/modelled amibient temperature based on information from ambient temp sensor and all other available temperature sensors and vehicle information.  Quality factor for estimated signal";
CM_ SG_ 1168 AsyNoaBltFastn "Haptic warning for take over in NOA state";
CM_ SG_ 1168 ChdLockDrvrReSts "Child protection Driver rear door, child lock status.";
CM_ SG_ 1168 SeatClimaDurgClimaHmiSeatHe_0003 "Seat heating status for first row left seat";
CM_ SG_ 1168 SeatClimaDurgClimaHmiSeatHe_0004 "Seat heating status for first row right seat.";
CM_ SG_ 1168 SeatClimaDurgClimaHmiSeatHe_0005 "Seat heating status for second row left status.";
CM_ SG_ 1168 SeatClimaDurgClimaHmiSeatHe_0006 "Seat heating status for second row right seat.";
CM_ SG_ 1168 SeatClimaDurgClimaHmiSeatVe_0003 "Seat ventialtion status for first row left seat";
CM_ SG_ 1168 SeatClimaDurgClimaHmiSeatVe_0004 "Seat ventilation status for first row right";
CM_ SG_ 1168 SeatClimaDurgClimaHmiSeatVe_0005 "Seat ventilation status for second row left";
CM_ SG_ 1168 SeatClimaDurgClimaHmiSeatVe_0006 "Seat ventilation status for second row right";
CM_ SG_ 1168 SecRowLeSeatHeatgPwrAllwd "Power limitation for second row left seat climatization.";
CM_ SG_ 295 SecRowLeSeatVentnPwrAllwd "Allowed second row left seat ventilation power.";
CM_ SG_ 295 SecRowRiSeatHeatgPwrAllwd "Power limitation for second row right seat climatization.";
CM_ SG_ 295 SecRowRiSeatVentnPwrAllwd "Allowed second row right seat ventilation power.";
CM_ SG_ 805 EfuseKL15Req1 "ON/OFF";
CM_ SG_ 805 EfuseKL15Req2 "ON/OFF";
CM_ SG_ 805 EfuseKL15Req3 "ON/OFF";
CM_ SG_ 805 EfuseKL15Req4 "ON/OFF";
CM_ SG_ 805 EfuseKL15Req5 "ON/OFF";
CM_ SG_ 805 HoodSts "HoodSts - Hood Status
Ukwn - Unknown status
Opend - Opened
Clsd - Closed";
CM_ SG_ 805 PassStuMonSts "Front passenger body position detection and front and back child seat detection";
CM_ SG_ 612 ChgFilElmRst "Replace and reset the filter element";
CM_ SG_ 612 DrvrStuMonSts "Driver's body position detection";
CM_ SG_ 612 RollAgGlbQf "Lateral inclination of vehicle against horizon Qualifier flag";
CM_ SG_ 612 RollAgGlbVal "Lateral inclination of vehicle against horizon Roll angle in radians";
CM_ SG_ 612 SecLeDiagcStopReq "Second row left seat diagnostic stop request";
CM_ SG_ 612 SecRiDiagcStopReq "Second row right seat diagnostic stop request";
CM_ SG_ 612 SecRowRiHeatgLvl "Second row right seat heating level.";
CM_ SG_ 612 SecRowRiVentnLvl "Second row right seat ventilation level.";
CM_ SG_ 612 ThrdLeDiagcStopReq "Third row left seat diagnostic stop request";
CM_ SG_ 612 ThrdRiDiagcStopReq "Third row right seat diagnostic stop request";
CM_ SG_ 612 WinPosnStsAtDrvr "Signal sent to inform the rest of the car of the window position status for the front driver side door. The value of the signal is either an approximated percentage of openness, of the window is moving or if the position is unkown.
";
CM_ SG_ 612 WinPosnStsAtReLe "Signal sent to inform the rest of the car of the window position status for the rear driver side door. The value of the signal is either an approximated percentage of openness, of the window is moving or if the position is unkown.

";
CM_ SG_ 32 DrvrSeatSts "Describes if an occupant is detected in the driver seat.";
CM_ SG_ 32 IndcrSts "Provides the state and not the event of HWL/Direction Indicator.";
CM_ SG_ 32 OxygenCooltFlowSts "When the cooling flow of the oxygen generator  greater than 2L/min";
CM_ SG_ 32 SecRowLeDivePosSeatPosPerc "Second row left seat dive position";
CM_ SG_ 32 SecRowLeDivePosSeatPosQf "Qf";
CM_ SG_ 32 TrlrLiBrkActvt "Brake Light request for trailer if connected.";
CM_ SG_ 32 TrlrLiTurnIndcrActvt "Turn Indicators activation Trailer.";
CM_ SG_ 234 DoorSldngLeReReqChks "Checksum for E2E";
CM_ SG_ 234 DoorSldngLeReReqCntr "Counter for E2E";
CM_ SG_ 234 DoorSldngLeReReqDoorOpenerReq1 "DoorOpenerReq
DoorOpenerIdle - No request
DoorOpenerOpen - Request to Open
DoorOpenerCls - Request to Close
DoorOpenerStop - Request to stop any ongoing power sliding door movement";
CM_ SG_ 234 DoorSldngLeReReqTrigSrc2 "TrigSrc";
CM_ SG_ 234 DoorSldngRiReReqChks "Checksum for E2E";
CM_ SG_ 234 DoorSldngRiReReqCntr "Counter for E2E";
CM_ SG_ 234 DoorSldngRiReReqDoorOpenerReq1 "DoorOpenerReq
DoorOpenerIdle - No request
DoorOpenerOpen - Request to Open
DoorOpenerCls - Request to Close
DoorOpenerStop - Request to stop any ongoing power slding door movement";
CM_ SG_ 234 DoorSldngRiReReqTrigSrc2 "TrigSrc";
CM_ SG_ 234 TrsmParkLockdChks "Checksum for TrsmParkLockd";
CM_ SG_ 234 TrsmParkLockdCntr "Counter for TrsmParkLockd";
CM_ SG_ 234 TrsmParkLockdTrsmParkLockd "Transmission park lock status";
CM_ SG_ 91 HvBattLimnIndcn "Propulsion related LOS (Limited Operation Strategy) information from Hv Battery. LOS";
CM_ SG_ 91 WhlDirRotlReChks "checksum";
CM_ SG_ 91 WhlDirRotlReCntr "counter";
CM_ SG_ 91 WhlDirRotlReLe "Rotational direction for the rear individual wheels. Wheel rotation direction of rear left wheel.";
CM_ SG_ 91 WhlDirRotlReRi "Rotational direction for the rear individual wheels. Wheel rotation direction of rear right wheel.";
CM_ SG_ 27 SteerWhlSnsrAg "Actual steering wheel angle from the actual centre position of the steering wheel. ";
CM_ SG_ 27 SteerWhlSnsrAgSpd "Actual steering wheel angle from the actual centre position of the steering wheel. Steering angle speed with steering wheel rotation direction.  ";
CM_ SG_ 27 SteerWhlSnsrChks "Checksum for steering wheel sensor data.";
CM_ SG_ 27 SteerWhlSnsrCntr "Counter value for steering wheel sensor data.";
CM_ SG_ 27 SteerWhlSnsrQf "Qf for steering wheel sensor information";
CM_ SG_ 533 ChrgnOrDisChrgnStsFb "Propulsion subsystem feedback charging and discharging status";
CM_ SG_ 533 DrvrPfmncAlrmReqFromDHU "this singal indicate the level of fatigue alarm.";
CM_ SG_ 533 OxygenSplyReq "Oxygen supply on or off request to oxygen supply generater";
CM_ SG_ 533 SecRowSeatLeChildLockSet "Second row left seat child lock set status";
CM_ SG_ 533 SecRowSeatRiChildLockSet "Second row right seat child lock set status";
CM_ SG_ 533 ThrdRowLeSeatHeatgPwrAllwd "Power limitation for second row left seat climatization.";
CM_ SG_ 533 ThrdRowLeSeatVentnPwrAllwd "Allowed third row left seat ventilation power.";
CM_ SG_ 533 ThrdRowRiSeatHeatgPwrAllwd "Power limitation for third row right seat climatization.";
CM_ SG_ 533 ThrdRowRiSeatVentnPwrAllwd "Allowed third row right seat ventilation power.";
CM_ SG_ 533 ThrdRowSeatLeChildLockSet "Third row left seat child lock set status";
CM_ SG_ 533 ThrdRowSeatRiChildLockSet "Third row right seat child lock set status";
CM_ SG_ 533 UpperLowerTrSelnSwt "To select open upper tailgate only or open upper and lower tailgate together";
CM_ SG_ 320 HvSysRlyStsChks "Checksum for E2E";
CM_ SG_ 320 HvSysRlyStsCntr "Counter for E2E";
CM_ SG_ 320 HvSysRlyStsHvSysRlySts "Actual state of the main contactors.";
CM_ SG_ 384 TrlrLiRvsgActvt "Activation of reverse light.";
CM_ SG_ 784 BkpOfDstTrvld "total traveled distance.";
CM_ SG_ 784 RlyPreCmdCmft "Before the comfort relay is disconnected, a pre-disconnection signal needs to be sent to inform the relevant parties.";
CM_ SG_ 784 SeatRowThrdLeInclPosAngleAngleDe "A backrest angle value of 0 degrees is the same as the backrest position being horizontal with the headrest pointing straight forwards.
A backrest angle value of 180 degrees is the same as the backrest position being horizontal with the headrest pointing straight backwards. 
The signal resolution is 1 degree.";
CM_ SG_ 784 SeatRowThrdLeInclPosAngleQf1 "QualityFactor";
CM_ SG_ 784 SeatRowThrdRiInclPosAngleAngleDe "Third row right seat inclination angle";
CM_ SG_ 784 SeatRowThrdRiInclPosAngleQf1 "Qf";
CM_ SG_ 784 WirelschrgActvReqFromHmi "On Off";
CM_ SG_ 153 BattFltStsPrimBattFltStsPrm "Battery fault status primary.";
CM_ SG_ 153 BattFltStsPrimChks "CheckSum";
CM_ SG_ 153 BattFltStsPrimCntr "Counter";
CM_ SG_ 153 BattFltStsSecBattFltStsPrm "Battery fault status Secondary";
CM_ SG_ 153 BattFltStsSecChks "CheckSum";
CM_ SG_ 153 BattFltStsSecCntr "Counter";
CM_ SG_ 153 PassAirbNotiConfirm "Passenger airbag message confirmation feedback";
CM_ SG_ 153 SftyAirbRollovrSuppSwt "Aigbag roll over deactivate switch request";
CM_ SG_ 153 WinPosnStsAtReRi "Signal sent to inform the rest of the car of the window position status for the rear passenger side door. The value of the signal is either an approximated percentage of openness, of the window is moving or if the position is unkown.
";
CM_ SG_ 309 EmgyBrkLiIndcrTurn "Activation of both rear direction indicators for EBL.";
CM_ SG_ 309 SecRowRiDivePosSeatPosPerc "Second row right seat dive position";
CM_ SG_ 309 SecRowRiDivePosSeatPosQf "Qf";
CM_ SG_ 820 ExtrLtgStsAFS "AFS status";
CM_ SG_ 820 ExtrLtgStsAHBC "AHBC Status";
CM_ SG_ 820 ExtrLtgStsAHL "AHL Status";
CM_ SG_ 820 ExtrLtgStsAllWL "All Weather Light Status";
CM_ SG_ 820 ExtrLtgStsApproach "Approach Light Status";
CM_ SG_ 820 ExtrLtgStsChks "Checksum";
CM_ SG_ 820 ExtrLtgStsCntr "Counter";
CM_ SG_ 820 ExtrLtgStsCornrgLi "Cornering Light Status";
CM_ SG_ 820 ExtrLtgStsDBL "DBL Stataus";
CM_ SG_ 820 ExtrLtgStsDRL "DRL Status";
CM_ SG_ 820 ExtrLtgStsFlash "Flash Light Status";
CM_ SG_ 820 ExtrLtgStsFrntFog "Front Fog Light Status";
CM_ SG_ 820 ExtrLtgStsGoodbye "Good Bye Light Status";
CM_ SG_ 820 ExtrLtgStsHiBeam "Hi Beam Status";
CM_ SG_ 820 ExtrLtgStsHomeSafe "Home Safe Light Status";
CM_ SG_ 820 ExtrLtgStsHWL "HWL Status";
CM_ SG_ 820 ExtrLtgStsLoBeam "Low Beam Status";
CM_ SG_ 820 ExtrLtgStsLtgShow "Light Show Status";
CM_ SG_ 820 ExtrLtgStsPosLiFrnt "Position Light Front Status";
CM_ SG_ 820 ExtrLtgStsPosLiRe "Position Light Rear Status";
CM_ SG_ 820 ExtrLtgStsReFog "Rear Fog Light Status";
CM_ SG_ 820 ExtrLtgStsReverseLi "Reverse Light Status";
CM_ SG_ 820 ExtrLtgStsStopLi "Stop Light Status";
CM_ SG_ 820 ExtrLtgStsTurnIndrLe "Turn Indicator Left Status";
CM_ SG_ 820 ExtrLtgStsTurnIndrRi "Turn Indicator Right Status
";
CM_ SG_ 820 ExtrLtgStsWelcome "Welcome Light Status";
CM_ SG_ 625 ActvnOfSymIllmn "PWM signal to control vehicle switches symbol background illumination.";
CM_ SG_ 625 CmptmtTReCmptmtTFrnt "Rear incar temperature.";
CM_ SG_ 625 CmptmtTReCmptmtTFrntQf "Rear incar temperature quality flag";
CM_ SG_ 625 CmptmtTReFanForCmptmtTRunng "Fan for component temperature requirement.";
CM_ SG_ 625 HmiSeatVentAutStrtRowThrdLe "HmiSeatVentAutStrtRowThrdLe";
CM_ SG_ 625 HmiSeatVentAutStrtRowThrdRi "HmiSeatVentAutStrtRowThrdRi";
CM_ SG_ 625 RcwmBeltReq "ASM-CMSR send a request for seat belt pre-tighten";
CM_ SG_ 625 SeatHeatRowThrdLeEna "Seatheating enable";
CM_ SG_ 625 SeatHeatRowThrdRiEna "Seatheating enable";
CM_ SG_ 625 SeatVentnRowSecLeEna "SeatVentilation  enable";
CM_ SG_ 625 SeatVentnRowThrdLeEna "SeatVentilation  enable";
CM_ SG_ 625 SeatVentnRowThrdRiEna "SeatVentilation  enable";
CM_ SG_ 625 WinPosnStsAtPass "Signal sent to inform the rest of the car of the window position status for the front passenger side door. The value of the signal is either an approximated percentage of openness, of the window is moving or if the position is unkown.
";
CM_ SG_ 419 ZCUDMResdSig1ToSRSSafetyChks "ZCUDMResdSig1ToSRSSafety";
CM_ SG_ 419 ZCUDMResdSig1ToSRSSafetyCntr "ZCUDMResdSig1ToSRSSafety";
CM_ SG_ 419 ZCUDMResdSig1ToSRSSafetyUInt32 "ZCUDMResdSig1ToSRSSafety";
CM_ SG_ 532 RoadInclnQly "Road inclination information. The road inclination is negative when the vehicle is facing uphill and positive when the vehicle is facing downhill. Quality information for road inclination";
CM_ SG_ 532 RoadInclnRoadIncln "Road inclination information. The road inclination is negative when the vehicle is facing uphill and positive when the vehicle is facing downhill.";
CM_ SG_ 532 SeatHeatRowSecLeEna "Seatheating enable";
CM_ SG_ 532 SeatHeatRowSecRiEna "Seatheating enable";
CM_ SG_ 532 SeatMassgFctDrvrMassgInten "Seat Massage Intensity Selection Row First Driver";
CM_ SG_ 532 SeatMassgFctDrvrMassgProg "Seat Massage Program Selection Row First Driver";
CM_ SG_ 532 SeatMassgFctDrvrOnOff "Seat Massage On or Off Row First Driver";
CM_ SG_ 532 SeatMassgLumHeiCtrlDrvr "Seat Massage Lumbar Height Control Row First Driver";
CM_ SG_ 532 SeatMassgLumMotrEnaDrvr "Seat Massage Lumbar Motor Enable Row First Driver";
CM_ SG_ 532 SeatMidLumPosCtrlDrvr "Control lumbar air for middle part of the driver seat";
CM_ SG_ 532 SeatUpLumPosCtrlDrvr "Control lumbar air for upper part of the driver seat";
CM_ SG_ 532 SeatVentnRowSecRiEna "SeatVentilation  enable";
CM_ SG_ 431 RadioFrqAM "radio frequency analog";
CM_ SG_ 431 ThrdLeSeatLumDisSts "Third left seat lumber disable status";
CM_ SG_ 431 ThrdLeSeatMassDisSts "Third left seat massage disable status";
CM_ SG_ 431 ThrdLeSeatSideSpprtDisSts "Third left seat side support disable status";
CM_ SG_ 431 ThrdRiSeatLumDisSts "Third right seat lumber disable status";
CM_ SG_ 431 ThrdRiSeatMassDisSts "Third right seat massage disable status";
CM_ SG_ 431 ThrdRiSeatSideSpprtDisSts "Third right seat side support disable status";
CM_ SG_ 431 ThrdRowLeSeatMotPosnCalReq "ThrdRowLeSeatMotPosnCalReq";
CM_ SG_ 431 ThrdRowRiSeatMotPosnCalReq "ThrdRowRiSeatMotPosnCalReq";
CM_ SG_ 431 WPRLActvReqFromHmi "on off";
CM_ SG_ 431 WPRRActvReqFromHmi "on off";
CM_ SG_ 272 WhlDirRotlFrntChks "check sum";
CM_ SG_ 272 WhlDirRotlFrntCntr "counter";
CM_ SG_ 272 WhlDirRotlFrntLe "Rotational direction for the front individual wheels. Wheel rotation direction of front left wheel.";
CM_ SG_ 272 WhlDirRotlFrntRi "Rotational direction for the front individual wheels. Wheel rotation direction of front right wheel.";
CM_ SG_ 272 WhlSpdCircumlFrntChks "Individual wheel speed from front wheel speed sensors. Checksum";
CM_ SG_ 272 WhlSpdCircumlFrntCntr "Individual wheel speed from front wheel speed sensors. Counter";
CM_ SG_ 272 WhlSpdCircumlFrntLe "Individual wheel speed from front wheel speed sensors. Wheel speed from front left wheel speed sensor using nominal value of wheel radius.";
CM_ SG_ 272 WhlSpdCircumlFrntLeQf "Individual wheel speed from front wheel speed sensors. Qf for wheel speed sensor";
CM_ SG_ 272 WhlSpdCircumlFrntRiQf "Individual wheel speed from front wheel speed sensors. Qf for wheel speed sensor";
CM_ SG_ 272 WhlSpdCircumlFrntWhlSpdCircumlFr "Individual wheel speed from front wheel speed sensors. Wheel speed from front right wheel speed sensor using nominal value of wheel radius";
CM_ SG_ 282 TrCrashUnlckCmd "Trunk Crash Unlock Command";
CM_ SG_ 282 WhlSpdCircumlReChks "Individual wheel speed from rear wheel speed sensors. Checksum";
CM_ SG_ 282 WhlSpdCircumlReCntr "Individual wheel speed from rear wheel speed sensors. Counter";
CM_ SG_ 282 WhlSpdCircumlReLe "Individual wheel speed from rear wheel speed sensors. Wheel speed from rear left wheel speed sensor using nominal value of wheel radius.";
CM_ SG_ 282 WhlSpdCircumlReLeQf "Individual wheel speed from rear wheel speed sensors. Qf for wheel speed sensor";
CM_ SG_ 282 WhlSpdCircumlReRi "Individual wheel speed from rear wheel speed sensors. Wheel speed from rear right wheel speed sensor using nominal value of wheel radius.";
CM_ SG_ 282 WhlSpdCircumlReRiQf "Individual wheel speed from rear wheel speed sensors. Qf for wheel speed sensor";
CM_ SG_ 290 SecRowLeArmRstMotMoveReq "Second row left seat armrest motor move request";
CM_ SG_ 290 SecRowLeArmRstMotPosReqSpeed "speed";
CM_ SG_ 290 SecRowLeArmRstMotPosReqTargPosRe "Second row left seat armrest motor target position request";
CM_ SG_ 290 SecRowLeDiveMotMoveReq "Second row left seat dive motor move request";
CM_ SG_ 290 SecRowLeDiveMotPosReqSpeed "speed";
CM_ SG_ 290 SecRowLeDiveMotPosReqTargPosReq "Second row left seat dive motor target position request";
CM_ SG_ 290 SecRowLeHeiMotPosReqSpeed "speed";
CM_ SG_ 290 SecRowLeHeiMotPosReqTargPosReq "Second row left seat height motor target position request";
CM_ SG_ 292 SecRowLeInclMotPosReqSpeed "speed";
CM_ SG_ 292 SecRowLeInclMotPosReqTargPosReq "Second row left seat inclination motor target position request";
CM_ SG_ 292 SecRowLeLegExtMotMoveReq "Second row left seat legrest extension motor move request";
CM_ SG_ 292 SecRowLeLegExtMotPosReqSpeed "speed";
CM_ SG_ 292 SecRowLeLegExtMotPosReqTargPosRe "Second row left seat legrest extension motor target position request";
CM_ SG_ 292 SecRowLeLegRotMotMoveReq "Second row left seat legrest rotation motor move request";
CM_ SG_ 292 SecRowLeLegRotMotPosReqSpeed "speed";
CM_ SG_ 292 SecRowLeLegRotMotPosReqTargPosRe "Second row left seat legrest rotation motor target position request";
CM_ SG_ 293 SecRowLeRotMotMoveReq "Second row left seat rotation motor move request";
CM_ SG_ 293 SecRowLeRotMotPosReqSpeed "speed";
CM_ SG_ 293 SecRowLeRotMotPosReqTargPosReq "Second row left seat rotation motor target position request";
CM_ SG_ 293 SecRowLeSideSldMotMoveReq "Second row left seat side slide motor move request";
CM_ SG_ 293 SecRowLeSideSldMotPosReqSpeed "speed";
CM_ SG_ 293 SecRowLeSideSldMotPosReqTargPosR "Second row left seat side slide motor target position request";
CM_ SG_ 293 SecRowLeZeroGrvyMotPosReqSpeed "speed";
CM_ SG_ 293 SecRowLeZeroGrvyMotPosReqTargPos "Second row left seat zero gravity motor target position request";
CM_ SG_ 296 SecRowLeSldMotPosReqSpeed "speed";
CM_ SG_ 296 SecRowLeSldMotPosReqTargPosReq "Second row left seat slide motor target position request";
CM_ SG_ 296 SecRowRiArmRstMotMoveReq "Second row right seat armrest motor move request";
CM_ SG_ 296 SecRowRiArmRstMotPosReqSpeed "speed";
CM_ SG_ 296 SecRowRiArmRstMotPosReqTargPosRe "Second row right seat armrest motor target position request";
CM_ SG_ 296 SecRowRiDiveMotMoveReq "Second row right seat dive motor move request";
CM_ SG_ 296 SecRowRiDiveMotPosReqSpeed "speed";
CM_ SG_ 296 SecRowRiDiveMotPosReqTargPosReq "Second row right seat dive motor target position request";
CM_ SG_ 297 SecRowRiHeiMotMoveReq "Second row right seat height motor move request";
CM_ SG_ 297 SecRowRiHeiMotPosReqSpeed "speed";
CM_ SG_ 297 SecRowRiHeiMotPosReqTargPosReq "Second row right seat height motor target position request";
CM_ SG_ 297 SecRowRiInclMotMoveReq "Second row right seat inclination motor move request";
CM_ SG_ 297 SecRowRiInclMotPosReqSpeed "speed";
CM_ SG_ 297 SecRowRiInclMotPosReqTargPosReq "Second row right seat inclination motor target position request";
CM_ SG_ 297 SecRowRiRotMotPosReqSpeed "speed";
CM_ SG_ 297 SecRowRiRotMotPosReqTargPosReq "Second row right seat rotation motor target position request";
CM_ SG_ 298 SecRowRiLegExtMotMoveReq "Second row right seat legrest extension motor move request";
CM_ SG_ 298 SecRowRiLegExtMotPosReqSpeed "speed";
CM_ SG_ 298 SecRowRiLegExtMotPosReqTargPosRe "Second row right seat legrest extension motor target position request";
CM_ SG_ 298 SecRowRiLegRotMotMoveReq "Second row right seat legrest rotation motor move request";
CM_ SG_ 298 SecRowRiLegRotMotPosReqSpeed "speed";
CM_ SG_ 298 SecRowRiLegRotMotPosReqTargPosRe "Second row right seat legrest rotation motor target position request";
CM_ SG_ 298 SecRowRiSideSldMotPosReqSpeed "speed";
CM_ SG_ 298 SecRowRiSideSldMotPosReqTargPosR "Second row right seat side slide motor target position request";
CM_ SG_ 300 SecRowLeHeiMotMoveReq "Second row left seat height motor move request";
CM_ SG_ 300 SecRowLeInclMotMoveReq "Second row left seat inclination motor move request";
CM_ SG_ 300 SecRowLeSldMotMoveReq "Second row left seat slide motor move request";
CM_ SG_ 300 SecRowLeZeroGrvyMotMoveReq "Second row left seat zero gravity motor move request";
CM_ SG_ 300 SecRowRiRotMotMoveReq "Second row right seat rotation motor move request";
CM_ SG_ 300 SecRowRiSideSldMotMoveReq "Second row right seat side slide motor move request";
CM_ SG_ 300 SecRowRiSldMotMoveReq "Second row right seat slide motor move request";
CM_ SG_ 300 SecRowRiSldMotPosReqSpeed "speed";
CM_ SG_ 300 SecRowRiSldMotPosReqTargPosReq "Second row right seat slide motor target position request";
CM_ SG_ 300 SecRowRiZeroGrvyMotMoveReq "Second row right seat zero gravity motor move request";
CM_ SG_ 300 SecRowRiZeroGrvyMotPosReqSpeed "speed";
CM_ SG_ 300 SecRowRiZeroGrvyMotPosReqTargPos "Second row right seat zero gravity motor target position request";
CM_ SG_ 301 ThrdRowLeCushFldMotMoveReq "Third row left seat cushion fold motor move request";
CM_ SG_ 301 ThrdRowLeCushFldMotPosReqSpeed "Speed";
CM_ SG_ 301 ThrdRowLeCushFldMotPosReqTargPos "Third row left seat cushion fold motor target position request";
CM_ SG_ 301 ThrdRowLeInclMotMoveReq "Third row left seat inclination motor move request";
CM_ SG_ 301 ThrdRowLeInclMotPosReqSpeed "Speed";
CM_ SG_ 301 ThrdRowLeInclMotPosReqTargPosReq "Third row left seat inclination motor target position request";
CM_ SG_ 301 ThrdRowRiCushFldMotPosReqSpeed "Third row right seat cushion fold motor speed";
CM_ SG_ 301 ThrdRowRiCushFldMotPosReqTargPos "Third row right seat cushion fold motor target postion request";
CM_ SG_ 294 ThrdRowLeLegRotMotMoveReq "Third row left seat legrest rotation motor move request";
CM_ SG_ 294 ThrdRowLeLegRotMotPosReqSpeed "Speed";
CM_ SG_ 294 ThrdRowLeLegRotMotPosReqTargPosR "Third row left seat legrest rotation motor target position request";
CM_ SG_ 294 ThrdRowLeSldMotMoveReq "Third row left seat slide motor move request";
CM_ SG_ 294 ThrdRowLeSldMotPosReqSpeed "Speed";
CM_ SG_ 294 ThrdRowLeSldMotPosReqTargPosReq "Third row left seat slide motor target position request";
CM_ SG_ 294 ThrdRowRiInclMotPosReqSpeed "Third row right seat inclination motor speed";
CM_ SG_ 294 ThrdRowRiInclMotPosReqTargPosReq "Third row right seat inclination motor target postion request";
CM_ SG_ 303 SecRowLeRotLckMotMoveReq "Second row left seat rotation lock motor move request";
CM_ SG_ 303 SecRowRiRotLckMotMoveReq "Second row right seat rotation lock motor move request";
CM_ SG_ 303 ThrdRowLeCushFldLckMotReq "Third row left seat cushion fold lock motor move request";
CM_ SG_ 303 ThrdRowRiCushFldLckMotReq "Third row right seat cushion fold lock motor move request";
CM_ SG_ 303 ThrdRowRiCushFldMotMoveReq "Third row right seat cushion fold motor move request";
CM_ SG_ 303 ThrdRowRiInclMotMoveReq "Third row right seat inclination motor move request";
CM_ SG_ 303 ThrdRowRiLegRotMotMoveReq "Third row right seat legrest rotation motor move request";
CM_ SG_ 303 ThrdRowRiLegRotMotPosReqSpeed "Third row right seat legrest rotation motor speed";
CM_ SG_ 303 ThrdRowRiLegRotMotPosReqTargPosR "Third row right seat legrest rotation motor target postion request";
CM_ SG_ 303 ThrdRowRiSldMotMoveReq "Third row right seat slide motor move request";
CM_ SG_ 303 ThrdRowRiSldMotPosReqSpeed "Third row right seat slide motor speed";
CM_ SG_ 303 ThrdRowRiSldMotPosReqTargPosReq "Third row right seat slide motor target postion request";
CM_ SG_ 565 BrkFricTqTotAtWhlsActBrkFricTqTo "Total actual friction brake toque at all four wheels.";
CM_ SG_ 565 BrkFricTqTotAtWhlsActChks "Total actual friction brake toque at all four wheels. Checksum";
CM_ SG_ 565 BrkFricTqTotAtWhlsActCntr "Total actual friction brake toque at all four wheels. Counter";
CM_ SG_ 565 OxygenSplyPwrAllwd "Power allowed for oxygen supply function";
CM_ SG_ 314 EngNSafeEngN "Engine Speed [rpm] and Engine Speed derivative [rpm/s]";
CM_ SG_ 314 EngNSafeEngNChks "Engine Speed [rpm] and Engine Speed derivative [rpm/s]";
CM_ SG_ 314 EngNSafeEngNCntr "Engine Speed [rpm] and Engine Speed derivative [rpm/s]";
CM_ SG_ 314 EngNSafeEngNGrdt "Engine Speed [rpm] and Engine Speed derivative [rpm/s]";
CM_ SG_ 1281 WakeUpReasonsforZCUDM "WakeUpReasons";
BA_DEF_ BO_  "NmAsrMessage" ENUM  "No","Yes";
BA_DEF_ BO_  "GenMsgStartDelayTime" INT 0 65536;
BA_DEF_ BO_  "GenMsgSendType" ENUM  "cyclic","spontaneous","not-used","not-used","not-used","cyclicAndSpontaneous","not-used","cyclicIfActive","NoMsgSendType";
BA_DEF_ BO_  "GenMsgILSupport" ENUM  "No","Yes";
BA_DEF_ BO_  "GenMsgDelayTime" INT 0 65536;
BA_DEF_ BO_  "GenMsgCycleTime" INT 0 65536;
BA_DEF_ BO_  "CANFD_BRS" ENUM  "0","1";
BA_DEF_ BO_  "VFrameFormat" ENUM  "StandardCAN","ExtendedCAN","reserved","J1939PG","reserved","reserved","reserved","reserved","reserved","reserved","reserved","reserved","reserved","reserved","StandardCAN_FD","ExtendedCAN_FD";
BA_DEF_ SG_  "GenSigStartValue" HEX 0 80000000;
BA_DEF_ SG_  "GenSigSendType" ENUM  "Cyclic","OnWrite","OnWriteWithRepetition","OnChange","OnChangeWithRepetition","IfActive","IfActiveWithRepetition","NoSigSendType";
BA_DEF_ SG_  "GenSigFuncType" ENUM  "NoFunction","n/a","n/a","n/a","n/a","n/a","n/a","n/a","n/a","n/a","n/a","n/a","n/a","n/a","n/a","CHK","CNTR","n/a","n/a","n/a","CNTR_AR_01","CRC_AR_01_BOTH","CRC_AR_01_ALT","CRC_AR_01_LOW","CRC_AR_01_NIBBLE","CNTR_AR_04","CRC_AR_04A","CNTR_AR_05","CRC_AR_05";
BA_DEF_ SG_  "GenSigDataID" STRING ;
BA_DEF_ SG_  "SystemSignalLongSymbol" STRING ;
BA_DEF_ BO_  "SystemMessageLongSymbol" STRING ;
BA_DEF_DEF_  "NmAsrMessage" "No";
BA_DEF_DEF_  "GenMsgStartDelayTime" 0;
BA_DEF_DEF_  "GenMsgSendType" "NoMsgSendType";
BA_DEF_DEF_  "GenMsgILSupport" "Yes";
BA_DEF_DEF_  "GenMsgDelayTime" 0;
BA_DEF_DEF_  "GenMsgCycleTime" 0;
BA_DEF_DEF_  "CANFD_BRS" "1";
BA_DEF_DEF_  "VFrameFormat" "J1939PG";
BA_DEF_DEF_  "GenSigStartValue" 0;
BA_DEF_DEF_  "GenSigSendType" "NoSigSendType";
BA_DEF_DEF_  "GenSigFuncType" "NoFunction";
BA_DEF_DEF_  "GenSigDataID" "";
BA_DEF_DEF_  "SystemSignalLongSymbol" "";
BA_DEF_DEF_  "SystemMessageLongSymbol" "";
BA_ "VFrameFormat" BO_ 792 0;
BA_ "GenMsgSendType" BO_ 792 1;
BA_ "GenMsgDelayTime" BO_ 792 90;
BA_ "VFrameFormat" BO_ 133 0;
BA_ "GenMsgSendType" BO_ 133 0;
BA_ "GenMsgCycleTime" BO_ 133 25;
BA_ "VFrameFormat" BO_ 849 0;
BA_ "GenMsgSendType" BO_ 849 0;
BA_ "GenMsgCycleTime" BO_ 849 420;
BA_ "VFrameFormat" BO_ 528 0;
BA_ "GenMsgSendType" BO_ 528 0;
BA_ "GenMsgCycleTime" BO_ 528 120;
BA_ "VFrameFormat" BO_ 80 0;
BA_ "GenMsgSendType" BO_ 80 0;
BA_ "GenMsgCycleTime" BO_ 80 10;
BA_ "VFrameFormat" BO_ 521 0;
BA_ "GenMsgSendType" BO_ 521 0;
BA_ "GenMsgCycleTime" BO_ 521 100;
BA_ "VFrameFormat" BO_ 788 0;
BA_ "GenMsgSendType" BO_ 788 0;
BA_ "GenMsgCycleTime" BO_ 788 20;
BA_ "VFrameFormat" BO_ 1137 0;
BA_ "GenMsgSendType" BO_ 1137 0;
BA_ "GenMsgCycleTime" BO_ 1137 800;
BA_ "VFrameFormat" BO_ 819 0;
BA_ "GenMsgSendType" BO_ 819 0;
BA_ "GenMsgCycleTime" BO_ 819 250;
BA_ "VFrameFormat" BO_ 289 0;
BA_ "GenMsgSendType" BO_ 289 0;
BA_ "GenMsgCycleTime" BO_ 289 30;
BA_ "VFrameFormat" BO_ 1168 0;
BA_ "GenMsgSendType" BO_ 1168 0;
BA_ "GenMsgCycleTime" BO_ 1168 60;
BA_ "VFrameFormat" BO_ 295 0;
BA_ "GenMsgSendType" BO_ 295 0;
BA_ "GenMsgCycleTime" BO_ 295 100;
BA_ "VFrameFormat" BO_ 805 0;
BA_ "GenMsgSendType" BO_ 805 0;
BA_ "GenMsgCycleTime" BO_ 805 135;
BA_ "VFrameFormat" BO_ 612 0;
BA_ "GenMsgSendType" BO_ 612 0;
BA_ "GenMsgCycleTime" BO_ 612 120;
BA_ "VFrameFormat" BO_ 32 0;
BA_ "GenMsgSendType" BO_ 32 0;
BA_ "GenMsgCycleTime" BO_ 32 200;
BA_ "VFrameFormat" BO_ 234 0;
BA_ "GenMsgSendType" BO_ 234 0;
BA_ "GenMsgCycleTime" BO_ 234 40;
BA_ "VFrameFormat" BO_ 91 0;
BA_ "GenMsgSendType" BO_ 91 0;
BA_ "GenMsgCycleTime" BO_ 91 15;
BA_ "VFrameFormat" BO_ 27 0;
BA_ "GenMsgSendType" BO_ 27 0;
BA_ "GenMsgCycleTime" BO_ 27 10;
BA_ "VFrameFormat" BO_ 533 0;
BA_ "GenMsgSendType" BO_ 533 0;
BA_ "GenMsgCycleTime" BO_ 533 60;
BA_ "VFrameFormat" BO_ 320 0;
BA_ "GenMsgSendType" BO_ 320 0;
BA_ "GenMsgCycleTime" BO_ 320 200;
BA_ "VFrameFormat" BO_ 384 0;
BA_ "GenMsgSendType" BO_ 384 0;
BA_ "GenMsgCycleTime" BO_ 384 200;
BA_ "VFrameFormat" BO_ 784 0;
BA_ "GenMsgSendType" BO_ 784 0;
BA_ "GenMsgCycleTime" BO_ 784 175;
BA_ "VFrameFormat" BO_ 153 0;
BA_ "GenMsgSendType" BO_ 153 0;
BA_ "GenMsgCycleTime" BO_ 153 70;
BA_ "VFrameFormat" BO_ 309 0;
BA_ "GenMsgSendType" BO_ 309 0;
BA_ "GenMsgCycleTime" BO_ 309 200;
BA_ "VFrameFormat" BO_ 820 0;
BA_ "GenMsgSendType" BO_ 820 0;
BA_ "GenMsgCycleTime" BO_ 820 200;
BA_ "VFrameFormat" BO_ 625 0;
BA_ "GenMsgSendType" BO_ 625 0;
BA_ "GenMsgCycleTime" BO_ 625 70;
BA_ "VFrameFormat" BO_ 419 0;
BA_ "GenMsgSendType" BO_ 419 0;
BA_ "GenMsgCycleTime" BO_ 419 50;
BA_ "VFrameFormat" BO_ 532 0;
BA_ "GenMsgSendType" BO_ 532 0;
BA_ "GenMsgCycleTime" BO_ 532 100;
BA_ "VFrameFormat" BO_ 431 0;
BA_ "GenMsgSendType" BO_ 431 0;
BA_ "GenMsgCycleTime" BO_ 431 50;
BA_ "VFrameFormat" BO_ 272 0;
BA_ "GenMsgSendType" BO_ 272 0;
BA_ "GenMsgCycleTime" BO_ 272 15;
BA_ "VFrameFormat" BO_ 282 0;
BA_ "GenMsgSendType" BO_ 282 0;
BA_ "GenMsgCycleTime" BO_ 282 15;
BA_ "VFrameFormat" BO_ 290 0;
BA_ "GenMsgSendType" BO_ 290 0;
BA_ "GenMsgCycleTime" BO_ 290 30;
BA_ "VFrameFormat" BO_ 292 0;
BA_ "GenMsgSendType" BO_ 292 0;
BA_ "GenMsgCycleTime" BO_ 292 30;
BA_ "VFrameFormat" BO_ 293 0;
BA_ "GenMsgSendType" BO_ 293 0;
BA_ "GenMsgCycleTime" BO_ 293 30;
BA_ "VFrameFormat" BO_ 296 0;
BA_ "GenMsgSendType" BO_ 296 0;
BA_ "GenMsgCycleTime" BO_ 296 30;
BA_ "VFrameFormat" BO_ 297 0;
BA_ "GenMsgSendType" BO_ 297 0;
BA_ "GenMsgCycleTime" BO_ 297 30;
BA_ "VFrameFormat" BO_ 298 0;
BA_ "GenMsgSendType" BO_ 298 0;
BA_ "GenMsgCycleTime" BO_ 298 30;
BA_ "VFrameFormat" BO_ 300 0;
BA_ "GenMsgSendType" BO_ 300 0;
BA_ "GenMsgCycleTime" BO_ 300 30;
BA_ "VFrameFormat" BO_ 301 0;
BA_ "GenMsgSendType" BO_ 301 0;
BA_ "GenMsgCycleTime" BO_ 301 30;
BA_ "VFrameFormat" BO_ 294 0;
BA_ "GenMsgSendType" BO_ 294 0;
BA_ "GenMsgCycleTime" BO_ 294 30;
BA_ "VFrameFormat" BO_ 303 0;
BA_ "GenMsgSendType" BO_ 303 0;
BA_ "GenMsgCycleTime" BO_ 303 30;
BA_ "VFrameFormat" BO_ 565 0;
BA_ "GenMsgSendType" BO_ 565 0;
BA_ "GenMsgCycleTime" BO_ 565 70;
BA_ "VFrameFormat" BO_ 314 0;
BA_ "GenMsgSendType" BO_ 314 0;
BA_ "GenMsgCycleTime" BO_ 314 30;
BA_ "VFrameFormat" BO_ 1281 0;
BA_ "GenMsgSendType" BO_ 1281 1;
BA_ "GenMsgILSupport" BO_ 1281 0;
BA_ "NmAsrMessage" BO_ 1281 1;
BA_ "GenMsgDelayTime" BO_ 1281 20;
BA_ "GenSigSendType" SG_ 792 VehCfgPrmExt2BlkIDBytePosn1 1;
BA_ "GenSigSendType" SG_ 792 VehCfgPrmExt2CCPBytePosn2 1;
BA_ "GenSigSendType" SG_ 792 VehCfgPrmExt2CCPBytePosn3 1;
BA_ "GenSigSendType" SG_ 792 VehCfgPrmExt2CCPBytePosn4 1;
BA_ "GenSigSendType" SG_ 792 VehCfgPrmExt2CCPBytePosn5 1;
BA_ "GenSigSendType" SG_ 792 VehCfgPrmExt2CCPBytePosn6 1;
BA_ "GenSigSendType" SG_ 792 VehCfgPrmExt2CCPBytePosn7 1;
BA_ "GenSigSendType" SG_ 792 VehCfgPrmExt2CCPBytePosn8 1;
BA_ "GenSigSendType" SG_ 133 CllsnWarnReIndcn 0;
BA_ "GenSigSendType" SG_ 133 RctaIndcnLe 0;
BA_ "GenSigSendType" SG_ 133 RctaIndcnRi 0;
BA_ "GenSigSendType" SG_ 849 AmbTIndcdWithUnitAmbTIndcd 0;
BA_ "GenSigStartValue" SG_ 849 AmbTIndcdWithUnitAmbTIndcd 1000;
BA_ "GenSigSendType" SG_ 849 AmbTIndcdWithUnitAmbTIndcdUnit 0;
BA_ "GenSigSendType" SG_ 849 AmbTIndcdWithUnitQF 0;
BA_ "GenSigSendType" SG_ 849 BrkTqAtWhlsReq 0;
BA_ "GenSigSendType" SG_ 849 CrsCtrlrMsg 0;
BA_ "GenSigSendType" SG_ 849 RMLCmftFctReq 0;
BA_ "GenSigSendType" SG_ 849 RMRCmftFctReq 0;
BA_ "GenSigSendType" SG_ 849 TurnIndcrAndHwlByDrvInt 0;
BA_ "GenSigSendType" SG_ 528 ADTakeoverReqGroupADTakeoverAudi 0;
BA_ "SystemSignalLongSymbol" SG_ 528 ADTakeoverReqGroupADTakeoverAudi "ADTakeoverReqGroupADTakeoverAudio";
BA_ "GenSigSendType" SG_ 528 ADTakeoverReqGroupADTakeoverMsg 0;
BA_ "GenSigSendType" SG_ 528 ADTakeoverReqGroupChks 0;
BA_ "GenSigSendType" SG_ 528 ADTakeoverReqGroupCntr 0;
BA_ "GenSigSendType" SG_ 528 AsySftyFctStsToEDRACCFctSTs 0;
BA_ "GenSigSendType" SG_ 528 AsySftyFctStsToEDRACSFB1FctSts 0;
BA_ "GenSigSendType" SG_ 528 AsySftyFctStsToEDRACSFB2FctSts 0;
BA_ "GenSigSendType" SG_ 528 AsySftyFctStsToEDRACSFCFctSts 0;
BA_ "GenSigSendType" SG_ 528 AsySftyFctStsToEDRACSFDFctSts 0;
BA_ "GenSigSendType" SG_ 528 AsySftyFctStsToEDRACSFEFctSts 0;
BA_ "GenSigSendType" SG_ 528 AsySftyFctStsToEDRAEBSFctSts 0;
BA_ "GenSigSendType" SG_ 528 AsySftyFctStsToEDRCSFFctSts 0;
BA_ "GenSigSendType" SG_ 528 AsySftyFctStsToEDRESFFctSts 0;
BA_ "GenSigSendType" SG_ 528 AsySftyFctStsToEDRLDWSFctSts 0;
BA_ "GenSigSendType" SG_ 528 SeatDownLumPosCtrlDrvr 0;
BA_ "GenSigStartValue" SG_ 80 PreCrashFrontData_UB 1;
BA_ "GenSigSendType" SG_ 80 PreCrashFrontDataChks 0;
BA_ "GenSigFuncType" SG_ 80 PreCrashFrontDataChks 15;
BA_ "GenSigDataID" SG_ 80 PreCrashFrontDataChks "0x411";
BA_ "GenSigSendType" SG_ 80 PreCrashFrontDataClosingVelocity 0;
BA_ "GenSigSendType" SG_ 80 PreCrashFrontDataCntr 0;
BA_ "GenSigFuncType" SG_ 80 PreCrashFrontDataCntr 16;
BA_ "GenSigSendType" SG_ 80 PreCrashFrontDataObjectClass 0;
BA_ "GenSigSendType" SG_ 80 PreCrashFrontDataOverLap 0;
BA_ "GenSigStartValue" SG_ 80 PreCrashFrontDataOverLap 100;
BA_ "GenSigSendType" SG_ 80 PreCrashFrontDataTimeToImpact 0;
BA_ "GenSigStartValue" SG_ 80 PreCrashFrontDataTimeToImpact 250;
BA_ "GenSigSendType" SG_ 521 DrvrSeatAdpvSideSpprtSetg 0;
BA_ "GenSigSendType" SG_ 521 DrvrSeatSideSpprtSetg 0;
BA_ "GenSigSendType" SG_ 521 HmiSeatHeatAutStrtRowSecLe 0;
BA_ "GenSigSendType" SG_ 521 HmiSeatHeatAutStrtRowSecRi 0;
BA_ "GenSigSendType" SG_ 521 HmiSeatHeatAutStrtRowThrdLe 0;
BA_ "GenSigSendType" SG_ 521 HmiSeatHeatAutStrtRowThrdRi 0;
BA_ "GenSigSendType" SG_ 521 HmiSeatVentAutStrtRowSecLe 0;
BA_ "GenSigSendType" SG_ 521 HmiSeatVentAutStrtRowSecRi 0;
BA_ "GenSigSendType" SG_ 521 SeatClimaDurgClimaHmiSeatHeatgFo 0;
BA_ "SystemSignalLongSymbol" SG_ 521 SeatClimaDurgClimaHmiSeatHeatgFo "SeatClimaDurgClimaHmiSeatHeatgForRowThrdLe";
BA_ "SystemSignalLongSymbol" SG_ 521 SeatClimaDurgClimaHmiSeatHe_0000 "SeatClimaDurgClimaHmiSeatHeatgForRowThrdLe_UB";
BA_ "GenSigSendType" SG_ 521 SeatClimaDurgClimaHmiSeatHe_0001 0;
BA_ "SystemSignalLongSymbol" SG_ 521 SeatClimaDurgClimaHmiSeatHe_0001 "SeatClimaDurgClimaHmiSeatHeatgForRowThrdRi";
BA_ "SystemSignalLongSymbol" SG_ 521 SeatClimaDurgClimaHmiSeatHe_0002 "SeatClimaDurgClimaHmiSeatHeatgForRowThrdRi_UB";
BA_ "GenSigSendType" SG_ 521 SeatClimaDurgClimaHmiSeatVentnFo 0;
BA_ "SystemSignalLongSymbol" SG_ 521 SeatClimaDurgClimaHmiSeatVentnFo "SeatClimaDurgClimaHmiSeatVentnForRowThrdLe";
BA_ "SystemSignalLongSymbol" SG_ 521 SeatClimaDurgClimaHmiSeatVe_0000 "SeatClimaDurgClimaHmiSeatVentnForRowThrdLe_UB";
BA_ "GenSigSendType" SG_ 521 SeatClimaDurgClimaHmiSeatVe_0001 0;
BA_ "SystemSignalLongSymbol" SG_ 521 SeatClimaDurgClimaHmiSeatVe_0001 "SeatClimaDurgClimaHmiSeatVentnForRowThrdRi";
BA_ "SystemSignalLongSymbol" SG_ 521 SeatClimaDurgClimaHmiSeatVe_0002 "SeatClimaDurgClimaHmiSeatVentnForRowThrdRi_UB";
BA_ "GenSigSendType" SG_ 521 SeatMassgBackBlstrCtrlDrvr 0;
BA_ "GenSigSendType" SG_ 521 SeatMassgBackBlstrEnaDrvr 0;
BA_ "GenSigSendType" SG_ 521 SeatMassgCushBlstrCtrlDrvr 0;
BA_ "GenSigSendType" SG_ 521 SeatMassgCushBlstrEnaDrvr 0;
BA_ "GenSigSendType" SG_ 521 SeatMassgCushLiftCtrlDrvr 0;
BA_ "GenSigSendType" SG_ 521 SeatMassgCushLiftEnaDrvr 0;
BA_ "GenSigSendType" SG_ 521 SeatMassgLumExtnCtrlDrvr 0;
BA_ "GenSigSendType" SG_ 521 WhlMotSysSpdAct 0;
BA_ "GenSigStartValue" SG_ 521 WhlMotSysSpdAct 20000;
BA_ "GenSigSendType" SG_ 788 ChdLockPassReSts 0;
BA_ "GenSigSendType" SG_ 788 HoodLatchPosn 0;
BA_ "GenSigSendType" SG_ 788 HoodOpenerReqChks 0;
BA_ "GenSigStartValue" SG_ 788 HoodOpenerReqChks 255;
BA_ "GenSigSendType" SG_ 788 HoodOpenerReqCntr 0;
BA_ "GenSigSendType" SG_ 788 HoodOpenerReqDoorOpenerReq 0;
BA_ "GenSigSendType" SG_ 788 HoodOpenerReqTrigSrc 0;
BA_ "GenSigSendType" SG_ 788 Overlap 0;
BA_ "GenSigStartValue" SG_ 788 Overlap 100;
BA_ "GenSigSendType" SG_ 1137 CmptmtOxygenConcVluFrmClima 0;
BA_ "GenSigSendType" SG_ 1137 VehHomePrkgSysSts 0;
BA_ "GenSigSendType" SG_ 819 IndcrPatCmd1WdTiOff 0;
BA_ "GenSigSendType" SG_ 819 IndcrPatCmd1WdTiOn 0;
BA_ "GenSigSendType" SG_ 819 SecRowLeInclPosAngleDeg180 0;
BA_ "GenSigSendType" SG_ 819 SecRowLeInclPosQf1 0;
BA_ "GenSigSendType" SG_ 819 SecRowRiInclPosAngleDeg180 0;
BA_ "GenSigSendType" SG_ 819 SecRowRiInclPosQf1 0;
BA_ "GenSigSendType" SG_ 289 CmptmtTFrntCmptmtTFrnt 0;
BA_ "GenSigStartValue" SG_ 289 CmptmtTFrntCmptmtTFrnt 600;
BA_ "GenSigSendType" SG_ 289 CmptmtTFrntFanForCmptmtTRunng 0;
BA_ "GenSigSendType" SG_ 289 CmptmtTFrntQf 0;
BA_ "GenSigStartValue" SG_ 289 CmptmtTFrntQf 1;
BA_ "GenSigSendType" SG_ 289 PassSeatFoldSwt 0;
BA_ "GenSigSendType" SG_ 289 PassSeatUnfoldSwt 0;
BA_ "GenSigSendType" SG_ 1168 AmbTEstimdAmbTEstimd 0;
BA_ "GenSigStartValue" SG_ 1168 AmbTEstimdAmbTEstimd 700;
BA_ "GenSigSendType" SG_ 1168 AmbTEstimdQf 0;
BA_ "GenSigSendType" SG_ 1168 AsyNoaBltFastn 0;
BA_ "GenSigSendType" SG_ 1168 ChdLockDrvrReSts 0;
BA_ "GenSigSendType" SG_ 1168 SeatClimaDurgClimaHmiSeatHe_0003 0;
BA_ "SystemSignalLongSymbol" SG_ 1168 SeatClimaDurgClimaHmiSeatHe_0003 "SeatClimaDurgClimaHmiSeatHeatgForRowFirstLe";
BA_ "GenSigSendType" SG_ 1168 SeatClimaDurgClimaHmiSeatHe_0004 0;
BA_ "SystemSignalLongSymbol" SG_ 1168 SeatClimaDurgClimaHmiSeatHe_0004 "SeatClimaDurgClimaHmiSeatHeatgForRowFirstRi";
BA_ "GenSigSendType" SG_ 1168 SeatClimaDurgClimaHmiSeatHe_0005 0;
BA_ "SystemSignalLongSymbol" SG_ 1168 SeatClimaDurgClimaHmiSeatHe_0005 "SeatClimaDurgClimaHmiSeatHeatgForRowSecLe";
BA_ "GenSigSendType" SG_ 1168 SeatClimaDurgClimaHmiSeatHe_0006 0;
BA_ "SystemSignalLongSymbol" SG_ 1168 SeatClimaDurgClimaHmiSeatHe_0006 "SeatClimaDurgClimaHmiSeatHeatgForRowSecRi";
BA_ "GenSigSendType" SG_ 1168 SeatClimaDurgClimaHmiSeatVe_0003 0;
BA_ "SystemSignalLongSymbol" SG_ 1168 SeatClimaDurgClimaHmiSeatVe_0003 "SeatClimaDurgClimaHmiSeatVentnForRowFirstLe";
BA_ "GenSigSendType" SG_ 1168 SeatClimaDurgClimaHmiSeatVe_0004 0;
BA_ "SystemSignalLongSymbol" SG_ 1168 SeatClimaDurgClimaHmiSeatVe_0004 "SeatClimaDurgClimaHmiSeatVentnForRowFirstRi";
BA_ "GenSigSendType" SG_ 1168 SeatClimaDurgClimaHmiSeatVe_0005 0;
BA_ "SystemSignalLongSymbol" SG_ 1168 SeatClimaDurgClimaHmiSeatVe_0005 "SeatClimaDurgClimaHmiSeatVentnForRowSecLe";
BA_ "GenSigSendType" SG_ 1168 SeatClimaDurgClimaHmiSeatVe_0006 0;
BA_ "SystemSignalLongSymbol" SG_ 1168 SeatClimaDurgClimaHmiSeatVe_0006 "SeatClimaDurgClimaHmiSeatVentnForRowSecRi";
BA_ "GenSigSendType" SG_ 1168 SecRowLeSeatHeatgPwrAllwd 0;
BA_ "GenSigStartValue" SG_ 1168 SecRowLeSeatHeatgPwrAllwd 100;
BA_ "GenSigSendType" SG_ 295 SecRowLeSeatVentnPwrAllwd 0;
BA_ "GenSigSendType" SG_ 295 SecRowRiSeatHeatgPwrAllwd 0;
BA_ "GenSigSendType" SG_ 295 SecRowRiSeatVentnPwrAllwd 0;
BA_ "GenSigSendType" SG_ 805 EfuseKL15Req1 0;
BA_ "GenSigSendType" SG_ 805 EfuseKL15Req2 0;
BA_ "GenSigSendType" SG_ 805 EfuseKL15Req3 0;
BA_ "GenSigSendType" SG_ 805 EfuseKL15Req4 0;
BA_ "GenSigSendType" SG_ 805 EfuseKL15Req5 0;
BA_ "GenSigSendType" SG_ 805 HoodSts 0;
BA_ "GenSigSendType" SG_ 805 PassStuMonSts 0;
BA_ "GenSigSendType" SG_ 612 ChgFilElmRst 0;
BA_ "GenSigSendType" SG_ 612 DrvrStuMonSts 0;
BA_ "GenSigSendType" SG_ 612 RollAgGlbQf 0;
BA_ "GenSigStartValue" SG_ 612 RollAgGlbQf 1;
BA_ "GenSigSendType" SG_ 612 RollAgGlbVal 0;
BA_ "GenSigSendType" SG_ 612 SecLeDiagcStopReq 0;
BA_ "GenSigSendType" SG_ 612 SecRiDiagcStopReq 0;
BA_ "GenSigSendType" SG_ 612 SecRowRiHeatgLvl 0;
BA_ "GenSigSendType" SG_ 612 SecRowRiVentnLvl 0;
BA_ "GenSigSendType" SG_ 612 ThrdLeDiagcStopReq 0;
BA_ "GenSigSendType" SG_ 612 ThrdRiDiagcStopReq 0;
BA_ "GenSigSendType" SG_ 612 WinPosnStsAtDrvr 0;
BA_ "GenSigSendType" SG_ 612 WinPosnStsAtReLe 0;
BA_ "GenSigSendType" SG_ 32 DrvrSeatSts 0;
BA_ "GenSigStartValue" SG_ 32 DrvrSeatSts 1;
BA_ "GenSigSendType" SG_ 32 IndcrSts 0;
BA_ "GenSigSendType" SG_ 32 OxygenCooltFlowSts 0;
BA_ "GenSigSendType" SG_ 32 SecRowLeDivePosSeatPosPerc 0;
BA_ "GenSigSendType" SG_ 32 SecRowLeDivePosSeatPosQf 0;
BA_ "GenSigSendType" SG_ 32 TrlrLiBrkActvt 0;
BA_ "GenSigSendType" SG_ 32 TrlrLiTurnIndcrActvt 0;
BA_ "GenSigSendType" SG_ 234 DoorSldngLeReReqChks 0;
BA_ "GenSigStartValue" SG_ 234 DoorSldngLeReReqChks 255;
BA_ "GenSigSendType" SG_ 234 DoorSldngLeReReqCntr 0;
BA_ "GenSigSendType" SG_ 234 DoorSldngLeReReqDoorOpenerReq1 0;
BA_ "GenSigSendType" SG_ 234 DoorSldngLeReReqTrigSrc2 0;
BA_ "GenSigSendType" SG_ 234 DoorSldngRiReReqChks 0;
BA_ "GenSigStartValue" SG_ 234 DoorSldngRiReReqChks 255;
BA_ "GenSigSendType" SG_ 234 DoorSldngRiReReqCntr 0;
BA_ "GenSigSendType" SG_ 234 DoorSldngRiReReqDoorOpenerReq1 0;
BA_ "GenSigSendType" SG_ 234 DoorSldngRiReReqTrigSrc2 0;
BA_ "GenSigSendType" SG_ 234 TrsmParkLockdChks 0;
BA_ "GenSigFuncType" SG_ 234 TrsmParkLockdChks 15;
BA_ "GenSigDataID" SG_ 234 TrsmParkLockdChks "0x32";
BA_ "GenSigSendType" SG_ 234 TrsmParkLockdCntr 0;
BA_ "GenSigFuncType" SG_ 234 TrsmParkLockdCntr 16;
BA_ "GenSigSendType" SG_ 234 TrsmParkLockdTrsmParkLockd 0;
BA_ "GenSigStartValue" SG_ 234 TrsmParkLockdTrsmParkLockd 3;
BA_ "GenSigSendType" SG_ 91 HvBattLimnIndcn 0;
BA_ "GenSigSendType" SG_ 91 WhlDirRotlReChks 0;
BA_ "GenSigFuncType" SG_ 91 WhlDirRotlReChks 15;
BA_ "GenSigDataID" SG_ 91 WhlDirRotlReChks "0x227";
BA_ "GenSigSendType" SG_ 91 WhlDirRotlReCntr 0;
BA_ "GenSigFuncType" SG_ 91 WhlDirRotlReCntr 16;
BA_ "GenSigSendType" SG_ 91 WhlDirRotlReLe 0;
BA_ "GenSigSendType" SG_ 91 WhlDirRotlReRi 0;
BA_ "GenSigSendType" SG_ 27 SteerWhlSnsrAg 0;
BA_ "GenSigSendType" SG_ 27 SteerWhlSnsrAgSpd 0;
BA_ "GenSigSendType" SG_ 27 SteerWhlSnsrChks 0;
BA_ "GenSigFuncType" SG_ 27 SteerWhlSnsrChks 15;
BA_ "GenSigDataID" SG_ 27 SteerWhlSnsrChks "0x33";
BA_ "GenSigSendType" SG_ 27 SteerWhlSnsrCntr 0;
BA_ "GenSigFuncType" SG_ 27 SteerWhlSnsrCntr 16;
BA_ "GenSigSendType" SG_ 27 SteerWhlSnsrQf 0;
BA_ "GenSigStartValue" SG_ 27 SteerWhlSnsrQf 1;
BA_ "GenSigSendType" SG_ 533 ChrgnOrDisChrgnStsFb 0;
BA_ "GenSigSendType" SG_ 533 DrvrPfmncAlrmReqFromDHU 0;
BA_ "GenSigSendType" SG_ 533 OxygenSplyReq 0;
BA_ "GenSigSendType" SG_ 533 SecRowSeatLeChildLockSet 0;
BA_ "GenSigSendType" SG_ 533 SecRowSeatRiChildLockSet 0;
BA_ "GenSigSendType" SG_ 533 ThrdRowLeSeatHeatgPwrAllwd 0;
BA_ "GenSigSendType" SG_ 533 ThrdRowLeSeatVentnPwrAllwd 0;
BA_ "GenSigSendType" SG_ 533 ThrdRowRiSeatHeatgPwrAllwd 0;
BA_ "GenSigSendType" SG_ 533 ThrdRowRiSeatVentnPwrAllwd 0;
BA_ "GenSigSendType" SG_ 533 ThrdRowSeatLeChildLockSet 0;
BA_ "GenSigSendType" SG_ 533 ThrdRowSeatRiChildLockSet 0;
BA_ "GenSigSendType" SG_ 533 UpperLowerTrSelnSwt 0;
BA_ "GenSigSendType" SG_ 320 HvSysRlyStsChks 0;
BA_ "GenSigFuncType" SG_ 320 HvSysRlyStsChks 15;
BA_ "GenSigDataID" SG_ 320 HvSysRlyStsChks "0x15";
BA_ "GenSigSendType" SG_ 320 HvSysRlyStsCntr 0;
BA_ "GenSigFuncType" SG_ 320 HvSysRlyStsCntr 16;
BA_ "GenSigSendType" SG_ 320 HvSysRlyStsHvSysRlySts 0;
BA_ "GenSigStartValue" SG_ 320 HvSysRlyStsHvSysRlySts 2;
BA_ "GenSigSendType" SG_ 384 TrlrLiRvsgActvt 0;
BA_ "GenSigSendType" SG_ 784 BkpOfDstTrvld 0;
BA_ "GenSigSendType" SG_ 784 RlyPreCmdCmft 0;
BA_ "GenSigSendType" SG_ 784 SeatRowThrdLeInclPosAngleAngleDe 0;
BA_ "SystemSignalLongSymbol" SG_ 784 SeatRowThrdLeInclPosAngleAngleDe "SeatRowThrdLeInclPosAngleAngleDeg180";
BA_ "GenSigSendType" SG_ 784 SeatRowThrdLeInclPosAngleQf1 0;
BA_ "GenSigSendType" SG_ 784 SeatRowThrdRiInclPosAngleAngleDe 0;
BA_ "SystemSignalLongSymbol" SG_ 784 SeatRowThrdRiInclPosAngleAngleDe "SeatRowThrdRiInclPosAngleAngleDeg180";
BA_ "GenSigSendType" SG_ 784 SeatRowThrdRiInclPosAngleQf1 0;
BA_ "GenSigSendType" SG_ 784 WirelschrgActvReqFromHmi 0;
BA_ "GenSigSendType" SG_ 153 BattFltStsPrimBattFltStsPrm 0;
BA_ "GenSigSendType" SG_ 153 BattFltStsPrimChks 0;
BA_ "GenSigFuncType" SG_ 153 BattFltStsPrimChks 15;
BA_ "GenSigDataID" SG_ 153 BattFltStsPrimChks "0x1784";
BA_ "GenSigSendType" SG_ 153 BattFltStsPrimCntr 0;
BA_ "GenSigFuncType" SG_ 153 BattFltStsPrimCntr 16;
BA_ "GenSigSendType" SG_ 153 BattFltStsSecBattFltStsPrm 0;
BA_ "GenSigSendType" SG_ 153 BattFltStsSecChks 0;
BA_ "GenSigFuncType" SG_ 153 BattFltStsSecChks 15;
BA_ "GenSigDataID" SG_ 153 BattFltStsSecChks "0x1BF8";
BA_ "GenSigSendType" SG_ 153 BattFltStsSecCntr 0;
BA_ "GenSigFuncType" SG_ 153 BattFltStsSecCntr 16;
BA_ "GenSigSendType" SG_ 153 PassAirbNotiConfirm 0;
BA_ "GenSigSendType" SG_ 153 SftyAirbRollovrSuppSwt 0;
BA_ "GenSigSendType" SG_ 153 WinPosnStsAtReRi 0;
BA_ "GenSigSendType" SG_ 309 EmgyBrkLiIndcrTurn 0;
BA_ "GenSigStartValue" SG_ 309 EmgyBrkLiIndcrTurn 1;
BA_ "GenSigSendType" SG_ 309 SecRowRiDivePosSeatPosPerc 0;
BA_ "GenSigSendType" SG_ 309 SecRowRiDivePosSeatPosQf 0;
BA_ "GenSigSendType" SG_ 820 ExtrLtgStsAFS 0;
BA_ "GenSigSendType" SG_ 820 ExtrLtgStsAHBC 0;
BA_ "GenSigSendType" SG_ 820 ExtrLtgStsAHL 0;
BA_ "GenSigSendType" SG_ 820 ExtrLtgStsAllWL 0;
BA_ "GenSigSendType" SG_ 820 ExtrLtgStsApproach 0;
BA_ "GenSigSendType" SG_ 820 ExtrLtgStsChks 0;
BA_ "GenSigFuncType" SG_ 820 ExtrLtgStsChks 15;
BA_ "GenSigDataID" SG_ 820 ExtrLtgStsChks "0x44C";
BA_ "GenSigSendType" SG_ 820 ExtrLtgStsCntr 0;
BA_ "GenSigFuncType" SG_ 820 ExtrLtgStsCntr 16;
BA_ "GenSigSendType" SG_ 820 ExtrLtgStsCornrgLi 0;
BA_ "GenSigSendType" SG_ 820 ExtrLtgStsDBL 0;
BA_ "GenSigSendType" SG_ 820 ExtrLtgStsDRL 0;
BA_ "GenSigSendType" SG_ 820 ExtrLtgStsFlash 0;
BA_ "GenSigSendType" SG_ 820 ExtrLtgStsFrntFog 0;
BA_ "GenSigSendType" SG_ 820 ExtrLtgStsGoodbye 0;
BA_ "GenSigSendType" SG_ 820 ExtrLtgStsHiBeam 0;
BA_ "GenSigSendType" SG_ 820 ExtrLtgStsHomeSafe 0;
BA_ "GenSigSendType" SG_ 820 ExtrLtgStsHWL 0;
BA_ "GenSigSendType" SG_ 820 ExtrLtgStsLoBeam 0;
BA_ "GenSigSendType" SG_ 820 ExtrLtgStsLtgShow 0;
BA_ "GenSigSendType" SG_ 820 ExtrLtgStsPosLiFrnt 0;
BA_ "GenSigSendType" SG_ 820 ExtrLtgStsPosLiRe 0;
BA_ "GenSigSendType" SG_ 820 ExtrLtgStsReFog 0;
BA_ "GenSigSendType" SG_ 820 ExtrLtgStsReverseLi 0;
BA_ "GenSigSendType" SG_ 820 ExtrLtgStsStopLi 0;
BA_ "GenSigSendType" SG_ 820 ExtrLtgStsTurnIndrLe 0;
BA_ "GenSigSendType" SG_ 820 ExtrLtgStsTurnIndrRi 0;
BA_ "GenSigSendType" SG_ 820 ExtrLtgStsWelcome 0;
BA_ "GenSigSendType" SG_ 625 ActvnOfSymIllmn 0;
BA_ "GenSigSendType" SG_ 625 CmptmtTReCmptmtTFrnt 0;
BA_ "GenSigStartValue" SG_ 625 CmptmtTReCmptmtTFrnt 600;
BA_ "GenSigSendType" SG_ 625 CmptmtTReCmptmtTFrntQf 0;
BA_ "GenSigStartValue" SG_ 625 CmptmtTReCmptmtTFrntQf 1;
BA_ "GenSigSendType" SG_ 625 CmptmtTReFanForCmptmtTRunng 0;
BA_ "GenSigSendType" SG_ 625 HmiSeatVentAutStrtRowThrdLe 0;
BA_ "GenSigSendType" SG_ 625 HmiSeatVentAutStrtRowThrdRi 0;
BA_ "GenSigSendType" SG_ 625 RcwmBeltReq 0;
BA_ "GenSigSendType" SG_ 625 SeatHeatRowThrdLeEna 0;
BA_ "GenSigSendType" SG_ 625 SeatHeatRowThrdRiEna 0;
BA_ "GenSigSendType" SG_ 625 SeatVentnRowSecLeEna 0;
BA_ "GenSigSendType" SG_ 625 SeatVentnRowThrdLeEna 0;
BA_ "GenSigSendType" SG_ 625 SeatVentnRowThrdRiEna 0;
BA_ "GenSigSendType" SG_ 625 WinPosnStsAtPass 0;
BA_ "GenSigSendType" SG_ 419 ZCUDMResdSig1ToSRSSafetyChks 0;
BA_ "GenSigSendType" SG_ 419 ZCUDMResdSig1ToSRSSafetyCntr 0;
BA_ "GenSigSendType" SG_ 419 ZCUDMResdSig1ToSRSSafetyUInt32 0;
BA_ "GenSigSendType" SG_ 532 RoadInclnQly 0;
BA_ "GenSigStartValue" SG_ 532 RoadInclnQly 1;
BA_ "GenSigSendType" SG_ 532 RoadInclnRoadIncln 0;
BA_ "GenSigSendType" SG_ 532 SeatHeatRowSecLeEna 0;
BA_ "GenSigSendType" SG_ 532 SeatHeatRowSecRiEna 0;
BA_ "GenSigSendType" SG_ 532 SeatMassgFctDrvrMassgInten 0;
BA_ "GenSigSendType" SG_ 532 SeatMassgFctDrvrMassgProg 0;
BA_ "GenSigSendType" SG_ 532 SeatMassgFctDrvrOnOff 0;
BA_ "GenSigSendType" SG_ 532 SeatMassgLumHeiCtrlDrvr 0;
BA_ "GenSigSendType" SG_ 532 SeatMassgLumMotrEnaDrvr 0;
BA_ "GenSigSendType" SG_ 532 SeatMidLumPosCtrlDrvr 0;
BA_ "GenSigSendType" SG_ 532 SeatUpLumPosCtrlDrvr 0;
BA_ "GenSigSendType" SG_ 532 SeatVentnRowSecRiEna 0;
BA_ "GenSigSendType" SG_ 431 RadioFrqAM 0;
BA_ "GenSigSendType" SG_ 431 ThrdLeSeatLumDisSts 0;
BA_ "GenSigSendType" SG_ 431 ThrdLeSeatMassDisSts 0;
BA_ "GenSigSendType" SG_ 431 ThrdLeSeatSideSpprtDisSts 0;
BA_ "GenSigSendType" SG_ 431 ThrdRiSeatLumDisSts 0;
BA_ "GenSigSendType" SG_ 431 ThrdRiSeatMassDisSts 0;
BA_ "GenSigSendType" SG_ 431 ThrdRiSeatSideSpprtDisSts 0;
BA_ "GenSigSendType" SG_ 431 ThrdRowLeSeatMotPosnCalReq 0;
BA_ "GenSigSendType" SG_ 431 ThrdRowRiSeatMotPosnCalReq 0;
BA_ "GenSigSendType" SG_ 431 WPRLActvReqFromHmi 0;
BA_ "GenSigSendType" SG_ 431 WPRRActvReqFromHmi 0;
BA_ "GenSigSendType" SG_ 272 WhlDirRotlFrntChks 0;
BA_ "GenSigFuncType" SG_ 272 WhlDirRotlFrntChks 15;
BA_ "GenSigDataID" SG_ 272 WhlDirRotlFrntChks "0x228";
BA_ "GenSigSendType" SG_ 272 WhlDirRotlFrntCntr 0;
BA_ "GenSigFuncType" SG_ 272 WhlDirRotlFrntCntr 16;
BA_ "GenSigSendType" SG_ 272 WhlDirRotlFrntLe 0;
BA_ "GenSigSendType" SG_ 272 WhlDirRotlFrntRi 0;
BA_ "GenSigSendType" SG_ 272 WhlSpdCircumlFrntChks 0;
BA_ "GenSigFuncType" SG_ 272 WhlSpdCircumlFrntChks 15;
BA_ "GenSigDataID" SG_ 272 WhlSpdCircumlFrntChks "0x6F";
BA_ "GenSigSendType" SG_ 272 WhlSpdCircumlFrntCntr 0;
BA_ "GenSigFuncType" SG_ 272 WhlSpdCircumlFrntCntr 16;
BA_ "GenSigSendType" SG_ 272 WhlSpdCircumlFrntLe 0;
BA_ "GenSigSendType" SG_ 272 WhlSpdCircumlFrntLeQf 0;
BA_ "GenSigStartValue" SG_ 272 WhlSpdCircumlFrntLeQf 1;
BA_ "GenSigSendType" SG_ 272 WhlSpdCircumlFrntRiQf 0;
BA_ "GenSigStartValue" SG_ 272 WhlSpdCircumlFrntRiQf 1;
BA_ "GenSigSendType" SG_ 272 WhlSpdCircumlFrntWhlSpdCircumlFr 0;
BA_ "SystemSignalLongSymbol" SG_ 272 WhlSpdCircumlFrntWhlSpdCircumlFr "WhlSpdCircumlFrntWhlSpdCircumlFrntRi";
BA_ "GenSigSendType" SG_ 282 TrCrashUnlckCmd 0;
BA_ "GenSigSendType" SG_ 282 WhlSpdCircumlReChks 0;
BA_ "GenSigFuncType" SG_ 282 WhlSpdCircumlReChks 15;
BA_ "GenSigDataID" SG_ 282 WhlSpdCircumlReChks "0x7C";
BA_ "GenSigSendType" SG_ 282 WhlSpdCircumlReCntr 0;
BA_ "GenSigFuncType" SG_ 282 WhlSpdCircumlReCntr 16;
BA_ "GenSigSendType" SG_ 282 WhlSpdCircumlReLe 0;
BA_ "GenSigSendType" SG_ 282 WhlSpdCircumlReLeQf 0;
BA_ "GenSigStartValue" SG_ 282 WhlSpdCircumlReLeQf 1;
BA_ "GenSigSendType" SG_ 282 WhlSpdCircumlReRi 0;
BA_ "GenSigSendType" SG_ 282 WhlSpdCircumlReRiQf 0;
BA_ "GenSigStartValue" SG_ 282 WhlSpdCircumlReRiQf 1;
BA_ "GenSigSendType" SG_ 290 SecRowLeArmRstMotMoveReq 0;
BA_ "GenSigSendType" SG_ 290 SecRowLeArmRstMotPosReqSpeed 0;
BA_ "GenSigSendType" SG_ 290 SecRowLeArmRstMotPosReqTargPosRe 0;
BA_ "GenSigStartValue" SG_ 290 SecRowLeArmRstMotPosReqTargPosRe 1023;
BA_ "SystemSignalLongSymbol" SG_ 290 SecRowLeArmRstMotPosReqTargPosRe "SecRowLeArmRstMotPosReqTargPosReq";
BA_ "GenSigSendType" SG_ 290 SecRowLeDiveMotMoveReq 0;
BA_ "GenSigSendType" SG_ 290 SecRowLeDiveMotPosReqSpeed 0;
BA_ "GenSigSendType" SG_ 290 SecRowLeDiveMotPosReqTargPosReq 0;
BA_ "GenSigStartValue" SG_ 290 SecRowLeDiveMotPosReqTargPosReq 1023;
BA_ "GenSigSendType" SG_ 290 SecRowLeHeiMotPosReqSpeed 0;
BA_ "GenSigSendType" SG_ 290 SecRowLeHeiMotPosReqTargPosReq 0;
BA_ "GenSigStartValue" SG_ 290 SecRowLeHeiMotPosReqTargPosReq 1023;
BA_ "GenSigSendType" SG_ 292 SecRowLeInclMotPosReqSpeed 0;
BA_ "GenSigSendType" SG_ 292 SecRowLeInclMotPosReqTargPosReq 0;
BA_ "GenSigStartValue" SG_ 292 SecRowLeInclMotPosReqTargPosReq 1023;
BA_ "GenSigSendType" SG_ 292 SecRowLeLegExtMotMoveReq 0;
BA_ "GenSigSendType" SG_ 292 SecRowLeLegExtMotPosReqSpeed 0;
BA_ "GenSigSendType" SG_ 292 SecRowLeLegExtMotPosReqTargPosRe 0;
BA_ "GenSigStartValue" SG_ 292 SecRowLeLegExtMotPosReqTargPosRe 1023;
BA_ "SystemSignalLongSymbol" SG_ 292 SecRowLeLegExtMotPosReqTargPosRe "SecRowLeLegExtMotPosReqTargPosReq";
BA_ "GenSigSendType" SG_ 292 SecRowLeLegRotMotMoveReq 0;
BA_ "GenSigSendType" SG_ 292 SecRowLeLegRotMotPosReqSpeed 0;
BA_ "GenSigSendType" SG_ 292 SecRowLeLegRotMotPosReqTargPosRe 0;
BA_ "GenSigStartValue" SG_ 292 SecRowLeLegRotMotPosReqTargPosRe 1023;
BA_ "SystemSignalLongSymbol" SG_ 292 SecRowLeLegRotMotPosReqTargPosRe "SecRowLeLegRotMotPosReqTargPosReq";
BA_ "GenSigSendType" SG_ 293 SecRowLeRotMotMoveReq 0;
BA_ "GenSigSendType" SG_ 293 SecRowLeRotMotPosReqSpeed 0;
BA_ "GenSigSendType" SG_ 293 SecRowLeRotMotPosReqTargPosReq 0;
BA_ "GenSigStartValue" SG_ 293 SecRowLeRotMotPosReqTargPosReq 1023;
BA_ "GenSigSendType" SG_ 293 SecRowLeSideSldMotMoveReq 0;
BA_ "GenSigSendType" SG_ 293 SecRowLeSideSldMotPosReqSpeed 0;
BA_ "GenSigSendType" SG_ 293 SecRowLeSideSldMotPosReqTargPosR 0;
BA_ "GenSigStartValue" SG_ 293 SecRowLeSideSldMotPosReqTargPosR 1023;
BA_ "SystemSignalLongSymbol" SG_ 293 SecRowLeSideSldMotPosReqTargPosR "SecRowLeSideSldMotPosReqTargPosReq";
BA_ "GenSigSendType" SG_ 293 SecRowLeZeroGrvyMotPosReqSpeed 0;
BA_ "GenSigSendType" SG_ 293 SecRowLeZeroGrvyMotPosReqTargPos 0;
BA_ "GenSigStartValue" SG_ 293 SecRowLeZeroGrvyMotPosReqTargPos 1023;
BA_ "SystemSignalLongSymbol" SG_ 293 SecRowLeZeroGrvyMotPosReqTargPos "SecRowLeZeroGrvyMotPosReqTargPosReq";
BA_ "GenSigSendType" SG_ 296 SecRowLeSldMotPosReqSpeed 0;
BA_ "GenSigSendType" SG_ 296 SecRowLeSldMotPosReqTargPosReq 0;
BA_ "GenSigStartValue" SG_ 296 SecRowLeSldMotPosReqTargPosReq 1023;
BA_ "GenSigSendType" SG_ 296 SecRowRiArmRstMotMoveReq 0;
BA_ "GenSigSendType" SG_ 296 SecRowRiArmRstMotPosReqSpeed 0;
BA_ "GenSigSendType" SG_ 296 SecRowRiArmRstMotPosReqTargPosRe 0;
BA_ "GenSigStartValue" SG_ 296 SecRowRiArmRstMotPosReqTargPosRe 1023;
BA_ "SystemSignalLongSymbol" SG_ 296 SecRowRiArmRstMotPosReqTargPosRe "SecRowRiArmRstMotPosReqTargPosReq";
BA_ "GenSigSendType" SG_ 296 SecRowRiDiveMotMoveReq 0;
BA_ "GenSigSendType" SG_ 296 SecRowRiDiveMotPosReqSpeed 0;
BA_ "GenSigSendType" SG_ 296 SecRowRiDiveMotPosReqTargPosReq 0;
BA_ "GenSigStartValue" SG_ 296 SecRowRiDiveMotPosReqTargPosReq 1023;
BA_ "GenSigSendType" SG_ 297 SecRowRiHeiMotMoveReq 0;
BA_ "GenSigSendType" SG_ 297 SecRowRiHeiMotPosReqSpeed 0;
BA_ "GenSigSendType" SG_ 297 SecRowRiHeiMotPosReqTargPosReq 0;
BA_ "GenSigStartValue" SG_ 297 SecRowRiHeiMotPosReqTargPosReq 1023;
BA_ "GenSigSendType" SG_ 297 SecRowRiInclMotMoveReq 0;
BA_ "GenSigSendType" SG_ 297 SecRowRiInclMotPosReqSpeed 0;
BA_ "GenSigSendType" SG_ 297 SecRowRiInclMotPosReqTargPosReq 0;
BA_ "GenSigStartValue" SG_ 297 SecRowRiInclMotPosReqTargPosReq 1023;
BA_ "GenSigSendType" SG_ 297 SecRowRiRotMotPosReqSpeed 0;
BA_ "GenSigSendType" SG_ 297 SecRowRiRotMotPosReqTargPosReq 0;
BA_ "GenSigStartValue" SG_ 297 SecRowRiRotMotPosReqTargPosReq 1023;
BA_ "GenSigSendType" SG_ 298 SecRowRiLegExtMotMoveReq 0;
BA_ "GenSigSendType" SG_ 298 SecRowRiLegExtMotPosReqSpeed 0;
BA_ "GenSigSendType" SG_ 298 SecRowRiLegExtMotPosReqTargPosRe 0;
BA_ "GenSigStartValue" SG_ 298 SecRowRiLegExtMotPosReqTargPosRe 1023;
BA_ "SystemSignalLongSymbol" SG_ 298 SecRowRiLegExtMotPosReqTargPosRe "SecRowRiLegExtMotPosReqTargPosReq";
BA_ "GenSigSendType" SG_ 298 SecRowRiLegRotMotMoveReq 0;
BA_ "GenSigSendType" SG_ 298 SecRowRiLegRotMotPosReqSpeed 0;
BA_ "GenSigSendType" SG_ 298 SecRowRiLegRotMotPosReqTargPosRe 0;
BA_ "GenSigStartValue" SG_ 298 SecRowRiLegRotMotPosReqTargPosRe 1023;
BA_ "SystemSignalLongSymbol" SG_ 298 SecRowRiLegRotMotPosReqTargPosRe "SecRowRiLegRotMotPosReqTargPosReq";
BA_ "GenSigSendType" SG_ 298 SecRowRiSideSldMotPosReqSpeed 0;
BA_ "GenSigSendType" SG_ 298 SecRowRiSideSldMotPosReqTargPosR 0;
BA_ "GenSigStartValue" SG_ 298 SecRowRiSideSldMotPosReqTargPosR 1023;
BA_ "SystemSignalLongSymbol" SG_ 298 SecRowRiSideSldMotPosReqTargPosR "SecRowRiSideSldMotPosReqTargPosReq";
BA_ "GenSigSendType" SG_ 300 SecRowLeHeiMotMoveReq 0;
BA_ "GenSigSendType" SG_ 300 SecRowLeInclMotMoveReq 0;
BA_ "GenSigSendType" SG_ 300 SecRowLeSldMotMoveReq 0;
BA_ "GenSigSendType" SG_ 300 SecRowLeZeroGrvyMotMoveReq 0;
BA_ "GenSigSendType" SG_ 300 SecRowRiRotMotMoveReq 0;
BA_ "GenSigSendType" SG_ 300 SecRowRiSideSldMotMoveReq 0;
BA_ "GenSigSendType" SG_ 300 SecRowRiSldMotMoveReq 0;
BA_ "GenSigSendType" SG_ 300 SecRowRiSldMotPosReqSpeed 0;
BA_ "GenSigSendType" SG_ 300 SecRowRiSldMotPosReqTargPosReq 0;
BA_ "GenSigStartValue" SG_ 300 SecRowRiSldMotPosReqTargPosReq 1023;
BA_ "GenSigSendType" SG_ 300 SecRowRiZeroGrvyMotMoveReq 0;
BA_ "GenSigSendType" SG_ 300 SecRowRiZeroGrvyMotPosReqSpeed 0;
BA_ "GenSigSendType" SG_ 300 SecRowRiZeroGrvyMotPosReqTargPos 0;
BA_ "GenSigStartValue" SG_ 300 SecRowRiZeroGrvyMotPosReqTargPos 1023;
BA_ "SystemSignalLongSymbol" SG_ 300 SecRowRiZeroGrvyMotPosReqTargPos "SecRowRiZeroGrvyMotPosReqTargPosReq";
BA_ "GenSigSendType" SG_ 301 ThrdRowLeCushFldMotMoveReq 0;
BA_ "GenSigSendType" SG_ 301 ThrdRowLeCushFldMotPosReqSpeed 0;
BA_ "GenSigSendType" SG_ 301 ThrdRowLeCushFldMotPosReqTargPos 0;
BA_ "GenSigStartValue" SG_ 301 ThrdRowLeCushFldMotPosReqTargPos 1023;
BA_ "SystemSignalLongSymbol" SG_ 301 ThrdRowLeCushFldMotPosReqTargPos "ThrdRowLeCushFldMotPosReqTargPosReq";
BA_ "GenSigSendType" SG_ 301 ThrdRowLeInclMotMoveReq 0;
BA_ "GenSigSendType" SG_ 301 ThrdRowLeInclMotPosReqSpeed 0;
BA_ "GenSigSendType" SG_ 301 ThrdRowLeInclMotPosReqTargPosReq 0;
BA_ "GenSigStartValue" SG_ 301 ThrdRowLeInclMotPosReqTargPosReq 1023;
BA_ "GenSigSendType" SG_ 301 ThrdRowRiCushFldMotPosReqSpeed 0;
BA_ "GenSigSendType" SG_ 301 ThrdRowRiCushFldMotPosReqTargPos 0;
BA_ "GenSigStartValue" SG_ 301 ThrdRowRiCushFldMotPosReqTargPos 1023;
BA_ "SystemSignalLongSymbol" SG_ 301 ThrdRowRiCushFldMotPosReqTargPos "ThrdRowRiCushFldMotPosReqTargPosReq";
BA_ "GenSigSendType" SG_ 294 ThrdRowLeLegRotMotMoveReq 0;
BA_ "GenSigSendType" SG_ 294 ThrdRowLeLegRotMotPosReqSpeed 0;
BA_ "GenSigSendType" SG_ 294 ThrdRowLeLegRotMotPosReqTargPosR 0;
BA_ "GenSigStartValue" SG_ 294 ThrdRowLeLegRotMotPosReqTargPosR 1023;
BA_ "SystemSignalLongSymbol" SG_ 294 ThrdRowLeLegRotMotPosReqTargPosR "ThrdRowLeLegRotMotPosReqTargPosReq";
BA_ "GenSigSendType" SG_ 294 ThrdRowLeSldMotMoveReq 0;
BA_ "GenSigSendType" SG_ 294 ThrdRowLeSldMotPosReqSpeed 0;
BA_ "GenSigSendType" SG_ 294 ThrdRowLeSldMotPosReqTargPosReq 0;
BA_ "GenSigStartValue" SG_ 294 ThrdRowLeSldMotPosReqTargPosReq 1023;
BA_ "GenSigSendType" SG_ 294 ThrdRowRiInclMotPosReqSpeed 0;
BA_ "GenSigSendType" SG_ 294 ThrdRowRiInclMotPosReqTargPosReq 0;
BA_ "GenSigStartValue" SG_ 294 ThrdRowRiInclMotPosReqTargPosReq 1023;
BA_ "GenSigSendType" SG_ 303 SecRowLeRotLckMotMoveReq 0;
BA_ "GenSigSendType" SG_ 303 SecRowRiRotLckMotMoveReq 0;
BA_ "GenSigSendType" SG_ 303 ThrdRowLeCushFldLckMotReq 0;
BA_ "GenSigSendType" SG_ 303 ThrdRowRiCushFldLckMotReq 0;
BA_ "GenSigSendType" SG_ 303 ThrdRowRiCushFldMotMoveReq 0;
BA_ "GenSigSendType" SG_ 303 ThrdRowRiInclMotMoveReq 0;
BA_ "GenSigSendType" SG_ 303 ThrdRowRiLegRotMotMoveReq 0;
BA_ "GenSigSendType" SG_ 303 ThrdRowRiLegRotMotPosReqSpeed 0;
BA_ "GenSigSendType" SG_ 303 ThrdRowRiLegRotMotPosReqTargPosR 0;
BA_ "GenSigStartValue" SG_ 303 ThrdRowRiLegRotMotPosReqTargPosR 1023;
BA_ "SystemSignalLongSymbol" SG_ 303 ThrdRowRiLegRotMotPosReqTargPosR "ThrdRowRiLegRotMotPosReqTargPosReq";
BA_ "GenSigSendType" SG_ 303 ThrdRowRiSldMotMoveReq 0;
BA_ "GenSigSendType" SG_ 303 ThrdRowRiSldMotPosReqSpeed 0;
BA_ "GenSigSendType" SG_ 303 ThrdRowRiSldMotPosReqTargPosReq 0;
BA_ "GenSigStartValue" SG_ 303 ThrdRowRiSldMotPosReqTargPosReq 1023;
BA_ "GenSigSendType" SG_ 565 BrkFricTqTotAtWhlsActBrkFricTqTo 0;
BA_ "SystemSignalLongSymbol" SG_ 565 BrkFricTqTotAtWhlsActBrkFricTqTo "BrkFricTqTotAtWhlsActBrkFricTqTotAtWhlsAct";
BA_ "GenSigSendType" SG_ 565 BrkFricTqTotAtWhlsActChks 0;
BA_ "GenSigFuncType" SG_ 565 BrkFricTqTotAtWhlsActChks 15;
BA_ "GenSigDataID" SG_ 565 BrkFricTqTotAtWhlsActChks "0x7B";
BA_ "GenSigSendType" SG_ 565 BrkFricTqTotAtWhlsActCntr 0;
BA_ "GenSigFuncType" SG_ 565 BrkFricTqTotAtWhlsActCntr 16;
BA_ "GenSigSendType" SG_ 565 OxygenSplyPwrAllwd 0;
BA_ "GenSigSendType" SG_ 314 EngNSafeEngN 0;
BA_ "GenSigSendType" SG_ 314 EngNSafeEngNChks 0;
BA_ "GenSigFuncType" SG_ 314 EngNSafeEngNChks 15;
BA_ "GenSigDataID" SG_ 314 EngNSafeEngNChks "0x44";
BA_ "GenSigSendType" SG_ 314 EngNSafeEngNCntr 0;
BA_ "GenSigFuncType" SG_ 314 EngNSafeEngNCntr 16;
BA_ "GenSigSendType" SG_ 314 EngNSafeEngNGrdt 0;
BA_ "GenSigSendType" SG_ 1281 WakeUpReasonsforZCUDM 0;
VAL_ 133 CllsnWarnReIndcn 3 "LcmaIndcn_LcmaWarnLvl2" 2 "LcmaIndcn_NotUsed" 1 "LcmaIndcn_LcmaWarnLvl1" 0 "LcmaIndcn_NoLcmaWarn" ;
VAL_ 133 RctaIndcnLe 3 "LcmaIndcn_LcmaWarnLvl2" 2 "LcmaIndcn_NotUsed" 1 "LcmaIndcn_LcmaWarnLvl1" 0 "LcmaIndcn_NoLcmaWarn" ;
VAL_ 133 RctaIndcnRi 3 "LcmaIndcn_LcmaWarnLvl2" 2 "LcmaIndcn_NotUsed" 1 "LcmaIndcn_LcmaWarnLvl1" 0 "LcmaIndcn_NoLcmaWarn" ;
VAL_ 849 AmbTIndcdWithUnitAmbTIndcdUnit 2 "AmbTIndcdUnit_UkwnUnit" 1 "AmbTIndcdUnit_Fahrenheit" 0 "AmbTIndcdUnit_Celsius" ;
VAL_ 849 AmbTIndcdWithUnitQF 3 "GenQf1_AccurData" 2 "GenQf1_DataAccurNotWithinSpcn" 1 "GenQf1_TmpUndefdData" 0 "GenQf1_UndefindDataAccur" ;
VAL_ 849 CrsCtrlrMsg 7 "CrsCtrlrMsg1_BrkOvrheatd" 6 "CrsCtrlrMsg1_DrvModSeldNotOk" 5 "CrsCtrlrMsg1_CrsCtrlrCnclSpdLoLimExcdd" 4 "CrsCtrlrMsg1_SpdLoLimExcdd" 3 "CrsCtrlrMsg1_CrsCtrlrInhb" 2 "CrsCtrlrMsg1_OvrdTiMaxExcdd" 1 "CrsCtrlrMsg1_CrsCtrlrCncl" 0 "CrsCtrlrMsg1_NoMsg" ;
VAL_ 849 RMLCmftFctReq 1 "OnOff1_On" 0 "OnOff1_Off" ;
VAL_ 849 RMRCmftFctReq 1 "OnOff1_On" 0 "OnOff1_Off" ;
VAL_ 849 TurnIndcrAndHwlByDrvInt 3 "IndcrSts1_LeAndRiOn" 2 "IndcrSts1_RiOn" 1 "IndcrSts1_LeOn" 0 "IndcrSts1_Off" ;
VAL_ 528 ADTakeoverReqGroupADTakeoverAudi 3 "LowHigh_Reserved" 2 "LowHigh_High" 1 "LowHigh_Low" 0 "LowHigh_NoRequest" ;
VAL_ 528 ADTakeoverReqGroupADTakeoverMsg 7 "TakeoverMsg_Reserved3" 6 "TakeoverMsg_Reserved2" 5 "TakeoverMsg_AEB" 4 "TakeoverMsg_SafeStop" 3 "TakeoverMsg_SpeedReduce" 2 "TakeoverMsg_TakeoverRequest" 1 "TakeoverMsg_Inattention" 0 "TakeoverMsg_NoRequest" ;
VAL_ 528 AsySftyFctStsToEDRACCFctSTs 4 "FctSTs_Active" 3 "FctSTs_StandBy" 2 "FctSTs_Off" 1 "FctSTs_Faulted" 0 "FctSTs_Default" ;
VAL_ 528 AsySftyFctStsToEDRACSFB1FctSts 4 "FctSTs_Active" 3 "FctSTs_StandBy" 2 "FctSTs_Off" 1 "FctSTs_Faulted" 0 "FctSTs_Default" ;
VAL_ 528 AsySftyFctStsToEDRACSFB2FctSts 4 "FctSTs_Active" 3 "FctSTs_StandBy" 2 "FctSTs_Off" 1 "FctSTs_Faulted" 0 "FctSTs_Default" ;
VAL_ 528 AsySftyFctStsToEDRACSFCFctSts 4 "FctSTs_Active" 3 "FctSTs_StandBy" 2 "FctSTs_Off" 1 "FctSTs_Faulted" 0 "FctSTs_Default" ;
VAL_ 528 AsySftyFctStsToEDRACSFDFctSts 4 "FctSTs_Active" 3 "FctSTs_StandBy" 2 "FctSTs_Off" 1 "FctSTs_Faulted" 0 "FctSTs_Default" ;
VAL_ 528 AsySftyFctStsToEDRACSFEFctSts 4 "FctSTs_Active" 3 "FctSTs_StandBy" 2 "FctSTs_Off" 1 "FctSTs_Faulted" 0 "FctSTs_Default" ;
VAL_ 528 AsySftyFctStsToEDRAEBSFctSts 5 "AEBSFctSts_Engaged" 4 "AEBSFctSts_WarningButNotEngaged" 3 "AEBSFctSts_OnButNotEngaged" 2 "AEBSFctSts_Off" 1 "AEBSFctSts_Faulted" 0 "AEBSFctSts_Default" ;
VAL_ 528 AsySftyFctStsToEDRCSFFctSts 4 "FctSTs_Active" 3 "FctSTs_StandBy" 2 "FctSTs_Off" 1 "FctSTs_Faulted" 0 "FctSTs_Default" ;
VAL_ 528 AsySftyFctStsToEDRESFFctSts 4 "FctSTs_Active" 3 "FctSTs_StandBy" 2 "FctSTs_Off" 1 "FctSTs_Faulted" 0 "FctSTs_Default" ;
VAL_ 528 AsySftyFctStsToEDRLDWSFctSts 5 "LDWSFctSts_WarningRight" 4 "LDWSFctSts_WarningLeft" 3 "LDWSFctSts_OnButNotEngaged" 2 "LDWSFctSts_Off" 1 "LDWSFctSts_Faulted" 0 "LDWSFctSts_Default" ;
VAL_ 80 PreCrashFrontDataObjectClass 6 "ObjectClass_SensorError" 3 "ObjectClass_Pedestrian" 2 "ObjectClass_Truck" 1 "ObjectClass_Car" 0 "ObjectClass_Unknown" ;
VAL_ 521 DrvrSeatAdpvSideSpprtSetg 3 "Snvty1_HiSnvty" 2 "Snvty1_NormSnvty" 1 "Snvty1_LoSnvty" 0 "Snvty1_NotInUse" ;
VAL_ 521 DrvrSeatSideSpprtSetg 3 "Snvty1_HiSnvty" 2 "Snvty1_NormSnvty" 1 "Snvty1_LoSnvty" 0 "Snvty1_NotInUse" ;
VAL_ 521 HmiSeatHeatAutStrtRowSecLe 1 "OnOff1_On" 0 "OnOff1_Off" ;
VAL_ 521 HmiSeatHeatAutStrtRowSecRi 1 "OnOff1_On" 0 "OnOff1_Off" ;
VAL_ 521 HmiSeatHeatAutStrtRowThrdLe 1 "OnOff1_On" 0 "OnOff1_Off" ;
VAL_ 521 HmiSeatHeatAutStrtRowThrdRi 1 "OnOff1_On" 0 "OnOff1_Off" ;
VAL_ 521 HmiSeatVentAutStrtRowSecLe 1 "OnOff1_On" 0 "OnOff1_Off" ;
VAL_ 521 HmiSeatVentAutStrtRowSecRi 1 "OnOff1_On" 0 "OnOff1_Off" ;
VAL_ 521 SeatClimaDurgClimaHmiSeatHeatgFo 3 "SeatClimaLvl_Lvl3" 2 "SeatClimaLvl_Lvl2" 1 "SeatClimaLvl_Lvl1" 0 "SeatClimaLvl_Off" ;
VAL_ 521 SeatClimaDurgClimaHmiSeatHe_0001 3 "SeatClimaLvl_Lvl3" 2 "SeatClimaLvl_Lvl2" 1 "SeatClimaLvl_Lvl1" 0 "SeatClimaLvl_Off" ;
VAL_ 521 SeatClimaDurgClimaHmiSeatVentnFo 3 "SeatClimaLvl_Lvl3" 2 "SeatClimaLvl_Lvl2" 1 "SeatClimaLvl_Lvl1" 0 "SeatClimaLvl_Off" ;
VAL_ 521 SeatClimaDurgClimaHmiSeatVe_0001 3 "SeatClimaLvl_Lvl3" 2 "SeatClimaLvl_Lvl2" 1 "SeatClimaLvl_Lvl1" 0 "SeatClimaLvl_Off" ;
VAL_ 521 SeatMassgBackBlstrCtrlDrvr 2 "SwtHozlSts1_Backw" 1 "SwtHozlSts1_Fwd" 0 "SwtHozlSts1_Idle" ;
VAL_ 521 SeatMassgBackBlstrEnaDrvr 1 "Boolean_TRUE" 0 "Boolean_FALSE" ;
VAL_ 521 SeatMassgCushBlstrCtrlDrvr 2 "SwtVertSts1_Dwn" 1 "SwtVertSts1_Up" 0 "SwtVertSts1_Idle" ;
VAL_ 521 SeatMassgCushBlstrEnaDrvr 1 "Boolean_TRUE" 0 "Boolean_FALSE" ;
VAL_ 521 SeatMassgCushLiftCtrlDrvr 1 "Boolean_TRUE" 0 "Boolean_FALSE" ;
VAL_ 521 SeatMassgCushLiftEnaDrvr 1 "Boolean_TRUE" 0 "Boolean_FALSE" ;
VAL_ 521 SeatMassgLumExtnCtrlDrvr 2 "SwtHozlSts1_Backw" 1 "SwtHozlSts1_Fwd" 0 "SwtHozlSts1_Idle" ;
VAL_ 788 ChdLockPassReSts 3 "OnOffSafe1_OnOffSafeInvld2" 2 "OnOffSafe1_OnOffSafeOff" 1 "OnOffSafe1_OnOffSafeOn" 0 "OnOffSafe1_OnOffSafeInvld1" ;
VAL_ 788 HoodLatchPosn 3 "DoorPos_FullyOpen" 2 "DoorPos_SecondaryPosition" 1 "DoorPos_FullyClosed" 0 "DoorPos_Undefined" ;
VAL_ 788 HoodOpenerReqDoorOpenerReq 3 "DoorOpenerStop" 2 "DoorOpenerCls" 1 "DoorOpenerOpen" 0 "DoorOpenerIdle" ;
VAL_ 788 HoodOpenerReqTrigSrc 5 "InsdSwt" 4 "OutdSwt" 3 "Telm" 2 "HMI" 1 "KeyRem" 0 "NoTrigSrc" ;
VAL_ 1137 VehHomePrkgSysSts 28 "HomePrkgSysSts_ParkOutTakeOver" 27 "HomePrkgSysSts1_Exit" 26 "HomePrkgSysSts1_ParkOutMapBuildingNamed" 25 "HomePrkgSysSts1_ParkInMapBuildingNamed" 24 "HomePrkgSysSts1_ParkOutMapBuildingGenerate" 23 "HomePrkgSysSts1_ParkInMapBuildingGenerate" 22 "HomePrkgSysSts1_ParkOutMapBuilding" 21 "HomePrkgSysSts1_Ready" 20 "HomePrkgSysSts1_Failure" 19 "HomePrkgSysSts1_Initialization" 18 "HomePrkgSysSts1_Suspend" 17 "HomePrkgSysSts1_Abort" 16 "HomePrkgSysSts1_ParkOutCompleted" 15 "HomePrkgSysSts1_ParkInCompleted" 14 "HomePrkgSysSts1_Quit" 13 "HomePrkgSysSts1_ParkOutProcess" 12 "HomePrkgSysSts1_ParkOutPreactive" 11 "HomePrkgSysSts1_ParkInMapBuildingAPAParking" 10 "HomePrkgSysSts1_ParkInRandomParkingIn" 9 "HomePrkgSysSts1_ParkInProcess" 8 "HomePrkgSysSts1_ParkInPreactive" 7 "HomePrkgSysSts1_Interrupt" 6 "HomePrkgSysSts1_ParkInMapBuildingAPAPreactive" 5 "HomePrkgSysSts1_ParkOutCrusing" 4 "HomePrkgSysSts1_ParkInCruising" 3 "HomePrkgSysSts1_Localization" 2 "HomePrkgSysSts1_ParkInMapBuilding" 1 "HomePrkgSysSts1_Standby" 0 "HomePrkgSysSts1_Off" ;
VAL_ 819 SecRowLeInclPosQf1 3 "Qf1_DataCalcdWithDevDefd" 2 "Qf1_DevOfDataNotWithinRngAllwd" 1 "Qf1_DataTmpUndefdAndEvlnInProgs" 0 "Qf1_DevOfDataUndefd" ;
VAL_ 819 SecRowRiInclPosQf1 3 "Qf1_DataCalcdWithDevDefd" 2 "Qf1_DevOfDataNotWithinRngAllwd" 1 "Qf1_DataTmpUndefdAndEvlnInProgs" 0 "Qf1_DevOfDataUndefd" ;
VAL_ 289 CmptmtTFrntFanForCmptmtTRunng 1 "Flg1_Set" 0 "Flg1_Rst" ;
VAL_ 289 CmptmtTFrntQf 3 "CmptmtTFrntQf_SnsrDataOk" 2 "CmptmtTFrntQf_SnsrDataNotOk" 1 "CmptmtTFrntQf_FanNotRunning" 0 "CmptmtTFrntQf_SnsrDataUndefd" ;
VAL_ 289 PassSeatFoldSwt 1 "PsdNotPsd_Psd" 0 "PsdNotPsd_NotPsd" ;
VAL_ 289 PassSeatUnfoldSwt 1 "PsdNotPsd_Psd" 0 "PsdNotPsd_NotPsd" ;
VAL_ 1168 AmbTEstimdQf 1 "HvacTIfQf_SnsrDataOk" 0 "HvacTIfQf_SnsrDataNotOk" ;
VAL_ 1168 AsyNoaBltFastn 3 "AsyFirstTiActvn_Reserved" 2 "AsyFirstTiActvn_ACCFirstActication" 1 "AsyFirstTiActvn_ICCFirstActication" 0 "AsyFirstTiActvn_NoReq" ;
VAL_ 1168 ChdLockDrvrReSts 3 "OnOffSafe1_OnOffSafeInvld2" 2 "OnOffSafe1_OnOffSafeOff" 1 "OnOffSafe1_OnOffSafeOn" 0 "OnOffSafe1_OnOffSafeInvld1" ;
VAL_ 1168 SeatClimaDurgClimaHmiSeatHe_0003 3 "SeatClimaLvl_Lvl3" 2 "SeatClimaLvl_Lvl2" 1 "SeatClimaLvl_Lvl1" 0 "SeatClimaLvl_Off" ;
VAL_ 1168 SeatClimaDurgClimaHmiSeatHe_0004 3 "SeatClimaLvl_Lvl3" 2 "SeatClimaLvl_Lvl2" 1 "SeatClimaLvl_Lvl1" 0 "SeatClimaLvl_Off" ;
VAL_ 1168 SeatClimaDurgClimaHmiSeatHe_0005 3 "SeatClimaLvl_Lvl3" 2 "SeatClimaLvl_Lvl2" 1 "SeatClimaLvl_Lvl1" 0 "SeatClimaLvl_Off" ;
VAL_ 1168 SeatClimaDurgClimaHmiSeatHe_0006 3 "SeatClimaLvl_Lvl3" 2 "SeatClimaLvl_Lvl2" 1 "SeatClimaLvl_Lvl1" 0 "SeatClimaLvl_Off" ;
VAL_ 1168 SeatClimaDurgClimaHmiSeatVe_0003 3 "SeatClimaLvl_Lvl3" 2 "SeatClimaLvl_Lvl2" 1 "SeatClimaLvl_Lvl1" 0 "SeatClimaLvl_Off" ;
VAL_ 1168 SeatClimaDurgClimaHmiSeatVe_0004 3 "SeatClimaLvl_Lvl3" 2 "SeatClimaLvl_Lvl2" 1 "SeatClimaLvl_Lvl1" 0 "SeatClimaLvl_Off" ;
VAL_ 1168 SeatClimaDurgClimaHmiSeatVe_0005 3 "SeatClimaLvl_Lvl3" 2 "SeatClimaLvl_Lvl2" 1 "SeatClimaLvl_Lvl1" 0 "SeatClimaLvl_Off" ;
VAL_ 1168 SeatClimaDurgClimaHmiSeatVe_0006 3 "SeatClimaLvl_Lvl3" 2 "SeatClimaLvl_Lvl2" 1 "SeatClimaLvl_Lvl1" 0 "SeatClimaLvl_Off" ;
VAL_ 805 EfuseKL15Req1 1 "OnOff1_On" 0 "OnOff1_Off" ;
VAL_ 805 EfuseKL15Req2 1 "OnOff1_On" 0 "OnOff1_Off" ;
VAL_ 805 EfuseKL15Req3 1 "OnOff1_On" 0 "OnOff1_Off" ;
VAL_ 805 EfuseKL15Req4 1 "OnOff1_On" 0 "OnOff1_Off" ;
VAL_ 805 EfuseKL15Req5 1 "OnOff1_On" 0 "OnOff1_Off" ;
VAL_ 805 HoodSts 2 "DoorSts2_Clsd" 1 "DoorSts2_Opend" 0 "DoorSts2_Ukwn" ;
VAL_ 612 RollAgGlbQf 2 "Qly2_Vld" 1 "Qly2_NoInfo" 0 "Qly2_Flt" ;
VAL_ 612 SecLeDiagcStopReq 1 "Boolean_TRUE" 0 "Boolean_FALSE" ;
VAL_ 612 SecRiDiagcStopReq 1 "Boolean_TRUE" 0 "Boolean_FALSE" ;
VAL_ 612 SecRowRiHeatgLvl 3 "SeatClimaLvl_Lvl3" 2 "SeatClimaLvl_Lvl2" 1 "SeatClimaLvl_Lvl1" 0 "SeatClimaLvl_Off" ;
VAL_ 612 SecRowRiVentnLvl 3 "SeatClimaLvl_Lvl3" 2 "SeatClimaLvl_Lvl2" 1 "SeatClimaLvl_Lvl1" 0 "SeatClimaLvl_Off" ;
VAL_ 612 ThrdLeDiagcStopReq 1 "Boolean_TRUE" 0 "Boolean_FALSE" ;
VAL_ 612 ThrdRiDiagcStopReq 1 "Boolean_TRUE" 0 "Boolean_FALSE" ;
VAL_ 612 WinPosnStsAtDrvr 31 "WinAndRoofAndCurtPosnTyp_Movg" 30 "WinAndRoofAndCurtPosnTyp_Resd4" 29 "WinAndRoofAndCurtPosnTyp_Resd3" 28 "WinAndRoofAndCurtPosnTyp_Resd2" 27 "WinAndRoofAndCurtPosnTyp_Resd1" 26 "WinAndRoofAndCurtPosnTyp_OpenFull" 25 "WinAndRoofAndCurtPosnTyp_PercOpen96" 24 "WinAndRoofAndCurtPosnTyp_PercOpen92" 23 "WinAndRoofAndCurtPosnTyp_PercOpen88" 22 "WinAndRoofAndCurtPosnTyp_PercOpen84" 21 "WinAndRoofAndCurtPosnTyp_PercOpen80" 20 "WinAndRoofAndCurtPosnTyp_PercOpen76" 19 "WinAndRoofAndCurtPosnTyp_PercOpen72" 18 "WinAndRoofAndCurtPosnTyp_PercOpen68" 17 "WinAndRoofAndCurtPosnTyp_PercOpen64" 16 "WinAndRoofAndCurtPosnTyp_PercOpen60" 15 "WinAndRoofAndCurtPosnTyp_PercOpen56" 14 "WinAndRoofAndCurtPosnTyp_PercOpen52" 13 "WinAndRoofAndCurtPosnTyp_PercOpen48" 12 "WinAndRoofAndCurtPosnTyp_PercOpen44" 11 "WinAndRoofAndCurtPosnTyp_PercOpen40" 10 "WinAndRoofAndCurtPosnTyp_PercOpen36" 9 "WinAndRoofAndCurtPosnTyp_PercOpen32" 8 "WinAndRoofAndCurtPosnTyp_PercOpen28" 7 "WinAndRoofAndCurtPosnTyp_PercOpen24" 6 "WinAndRoofAndCurtPosnTyp_PercOpen20" 5 "WinAndRoofAndCurtPosnTyp_PercOpen16" 4 "WinAndRoofAndCurtPosnTyp_PercOpen12" 3 "WinAndRoofAndCurtPosnTyp_PercOpen8" 2 "WinAndRoofAndCurtPosnTyp_PercOpen4" 1 "WinAndRoofAndCurtPosnTyp_ClsFull" 0 "WinAndRoofAndCurtPosnTyp_PosnUkwn" ;
VAL_ 612 WinPosnStsAtReLe 31 "WinAndRoofAndCurtPosnTyp_Movg" 30 "WinAndRoofAndCurtPosnTyp_Resd4" 29 "WinAndRoofAndCurtPosnTyp_Resd3" 28 "WinAndRoofAndCurtPosnTyp_Resd2" 27 "WinAndRoofAndCurtPosnTyp_Resd1" 26 "WinAndRoofAndCurtPosnTyp_OpenFull" 25 "WinAndRoofAndCurtPosnTyp_PercOpen96" 24 "WinAndRoofAndCurtPosnTyp_PercOpen92" 23 "WinAndRoofAndCurtPosnTyp_PercOpen88" 22 "WinAndRoofAndCurtPosnTyp_PercOpen84" 21 "WinAndRoofAndCurtPosnTyp_PercOpen80" 20 "WinAndRoofAndCurtPosnTyp_PercOpen76" 19 "WinAndRoofAndCurtPosnTyp_PercOpen72" 18 "WinAndRoofAndCurtPosnTyp_PercOpen68" 17 "WinAndRoofAndCurtPosnTyp_PercOpen64" 16 "WinAndRoofAndCurtPosnTyp_PercOpen60" 15 "WinAndRoofAndCurtPosnTyp_PercOpen56" 14 "WinAndRoofAndCurtPosnTyp_PercOpen52" 13 "WinAndRoofAndCurtPosnTyp_PercOpen48" 12 "WinAndRoofAndCurtPosnTyp_PercOpen44" 11 "WinAndRoofAndCurtPosnTyp_PercOpen40" 10 "WinAndRoofAndCurtPosnTyp_PercOpen36" 9 "WinAndRoofAndCurtPosnTyp_PercOpen32" 8 "WinAndRoofAndCurtPosnTyp_PercOpen28" 7 "WinAndRoofAndCurtPosnTyp_PercOpen24" 6 "WinAndRoofAndCurtPosnTyp_PercOpen20" 5 "WinAndRoofAndCurtPosnTyp_PercOpen16" 4 "WinAndRoofAndCurtPosnTyp_PercOpen12" 3 "WinAndRoofAndCurtPosnTyp_PercOpen8" 2 "WinAndRoofAndCurtPosnTyp_PercOpen4" 1 "WinAndRoofAndCurtPosnTyp_ClsFull" 0 "WinAndRoofAndCurtPosnTyp_PosnUkwn" ;
VAL_ 32 DrvrSeatSts 3 "OccptPresSt1_Undefd2" 2 "OccptPresSt1_OccptPrsnt" 1 "OccptPresSt1_OccptNotPrsnt" 0 "OccptPresSt1_Undefd1" ;
VAL_ 32 IndcrSts 3 "IndcrSts1_LeAndRiOn" 2 "IndcrSts1_RiOn" 1 "IndcrSts1_LeOn" 0 "IndcrSts1_Off" ;
VAL_ 32 OxygenCooltFlowSts 1 "OnOff1_On" 0 "OnOff1_Off" ;
VAL_ 32 SecRowLeDivePosSeatPosQf 3 "Qf1_DataCalcdWithDevDefd" 2 "Qf1_DevOfDataNotWithinRngAllwd" 1 "Qf1_DataTmpUndefdAndEvlnInProgs" 0 "Qf1_DevOfDataUndefd" ;
VAL_ 32 TrlrLiBrkActvt 1 "OnOff1_On" 0 "OnOff1_Off" ;
VAL_ 32 TrlrLiTurnIndcrActvt 3 "IndcrSts1_LeAndRiOn" 2 "IndcrSts1_RiOn" 1 "IndcrSts1_LeOn" 0 "IndcrSts1_Off" ;
VAL_ 234 DoorSldngLeReReqDoorOpenerReq1 3 "DoorOpenerStop" 2 "DoorOpenerCls" 1 "DoorOpenerOpen" 0 "DoorOpenerIdle" ;
VAL_ 234 DoorSldngLeReReqTrigSrc2 11 "TrigSrc2_OutdOth" 10 "TrigSrc2_InsdOth" 9 "TrigSrc2_SpdCls" 8 "TrigSrc2_InsdSwt_IntelligentTouchSurface" 7 "TrigSrc2_OutdSwt_DoorHandle" 6 "TrigSrc2_InsdSwt_OverheadConsole" 5 "TrigSrc2_InsdSwt_BPillar" 4 "TrigSrc2_OutdSwt_GestureSurface" 3 "TrigSrc2_Telm" 2 "TrigSrc2_HMI" 1 "TrigSrc2_KeyRem" 0 "TrigSrc2_NoTrigSrc" ;
VAL_ 234 DoorSldngRiReReqDoorOpenerReq1 3 "DoorOpenerStop" 2 "DoorOpenerCls" 1 "DoorOpenerOpen" 0 "DoorOpenerIdle" ;
VAL_ 234 DoorSldngRiReReqTrigSrc2 11 "TrigSrc2_OutdOth" 10 "TrigSrc2_InsdOth" 9 "TrigSrc2_SpdCls" 8 "TrigSrc2_InsdSwt_IntelligentTouchSurface" 7 "TrigSrc2_OutdSwt_DoorHandle" 6 "TrigSrc2_InsdSwt_OverheadConsole" 5 "TrigSrc2_InsdSwt_BPillar" 4 "TrigSrc2_OutdSwt_GestureSurface" 3 "TrigSrc2_Telm" 2 "TrigSrc2_HMI" 1 "TrigSrc2_KeyRem" 0 "TrigSrc2_NoTrigSrc" ;
VAL_ 234 TrsmParkLockdTrsmParkLockd 3 "TrsmParkLock1_Undefd" 2 "TrsmParkLock1_NotInUse" 1 "TrsmParkLock1_ParkEngd" 0 "TrsmParkLock1_ParkNotEngd" ;
VAL_ 91 WhlDirRotlReLe 3 "WhlRotlDirStd1_Backw" 2 "WhlRotlDirStd1_Fwd" 1 "WhlRotlDirStd1_StandStill" 0 "WhlRotlDirStd1_Undefd" ;
VAL_ 91 WhlDirRotlReRi 3 "WhlRotlDirStd1_Backw" 2 "WhlRotlDirStd1_Fwd" 1 "WhlRotlDirStd1_StandStill" 0 "WhlRotlDirStd1_Undefd" ;
VAL_ 27 SteerWhlSnsrQf 3 "GenQf1_AccurData" 2 "GenQf1_DataAccurNotWithinSpcn" 1 "GenQf1_TmpUndefdData" 0 "GenQf1_UndefindDataAccur" ;
VAL_ 533 ChrgnOrDisChrgnStsFb 30 "ChrgnSts2_WirelessCharging" 29 "ChrgnSts2_BoostchargingFlt" 28 "ChrgnSts2_Boostcharging" 27 "ChrgnSts2_ACChrgnFltVehSide" 26 "ChrgnSts2_DCChargingEnd" 25 "ChrgnSts2_ACChargingSuspend" 24 "ChrgnSts2_SuperCharging" 23 "ChrgnSts2_DCChrgnFltChrgrSideComFlt" 22 "ChrgnSts2_DCChrgnFltChrgrSideEmgyFlt" 21 "ChrgnSts2_DCChrgnFltChrgrSideHwFlt" 20 "ChrgnSts2_DCChrgnFltChrgrSideConFlt" 19 "ChrgnSts2_DCChrgnFltChrgrSideTempFlt" 18 "ChrgnSts2_DCChrgnFltVehSide" 15 "ChrgnSts2_DCCharging" 14 "ChrgnSts2_ACChrgnFltChrgrSide" 12 "ChrgnSts2_DischargingFalut" 11 "ChrgnSts2_Chargingfalut" 10 "ChrgnSts2_DischargingCmpl" 9 "ChrgnSts2_DischargingEnd" 8 "ChrgnSts2_Discharging" 7 "ChrgnSts2_NoDischaring" 6 "ChrgnSts2_Booking" 5 "ChrgnSts2_Heating" 4 "ChrgnSts2_ChargingCmpl" 3 "ChrgnSts2_ChargingEnd" 2 "ChrgnSts2_ACCharging" 1 "ChrgnSts2_NoCharging" 0 "ChrgnSts2_Default" ;
VAL_ 533 DrvrPfmncAlrmReqFromDHU 6 "DrvrPfmncWarnReq_Warninglevel2" 5 "DrvrPfmncWarnReq_Warninglevel2_Navigation" 4 "DrvrPfmncWarnReq_Warninglevel1" 3 "DrvrPfmncWarnReq_Distractive" 2 "DrvrPfmncWarnReq_NoWarning" 1 "DrvrPfmncWarnReq_Unknown" 0 "DrvrPfmncWarnReq_Unavailable" ;
VAL_ 533 OxygenSplyReq 3 "OxygenSplyReq_NasalCannula" 2 "OxygenSplyReq_Diffuse" 1 "OxygenSplyReq_Off" 0 "OxygenSplyReq_NoReq" ;
VAL_ 533 SecRowSeatLeChildLockSet 1 "OnOff1_On" 0 "OnOff1_Off" ;
VAL_ 533 SecRowSeatRiChildLockSet 1 "OnOff1_On" 0 "OnOff1_Off" ;
VAL_ 533 ThrdRowSeatLeChildLockSet 1 "OnOff1_On" 0 "OnOff1_Off" ;
VAL_ 533 ThrdRowSeatRiChildLockSet 1 "OnOff1_On" 0 "OnOff1_Off" ;
VAL_ 533 UpperLowerTrSelnSwt 1 "HmiLiSetReq_Multiple" 0 "HmiLiSetReq_Single" ;
VAL_ 320 HvSysRlyStsHvSysRlySts 3 "HvActvnSts_OpenAndReqActvDcha" 2 "HvActvnSts_KeepSt" 1 "HvActvnSts_Clsd" 0 "HvActvnSts_Open" ;
VAL_ 384 TrlrLiRvsgActvt 1 "OnOff1_On" 0 "OnOff1_Off" ;
VAL_ 784 RlyPreCmdCmft 1 "OnOff1_On" 0 "OnOff1_Off" ;
VAL_ 784 SeatRowThrdLeInclPosAngleQf1 3 "Qf1_DataCalcdWithDevDefd" 2 "Qf1_DevOfDataNotWithinRngAllwd" 1 "Qf1_DataTmpUndefdAndEvlnInProgs" 0 "Qf1_DevOfDataUndefd" ;
VAL_ 784 SeatRowThrdRiInclPosAngleQf1 3 "Qf1_DataCalcdWithDevDefd" 2 "Qf1_DevOfDataNotWithinRngAllwd" 1 "Qf1_DataTmpUndefdAndEvlnInProgs" 0 "Qf1_DevOfDataUndefd" ;
VAL_ 784 WirelschrgActvReqFromHmi 1 "OnOff1_On" 0 "OnOff1_Off" ;
VAL_ 153 BattFltStsPrimBattFltStsPrm 15 "BattFltStsPrm_RlyOpenSoonIndcn" 14 "BattFltStsPrm_WakeupActvFlg" 13 "BattFltStsPrm_ResetActvFlg" 11 "BattFltStsPrm_ThermRunawayFlt" 7 "BattFltStsPrm_ScFlt_shortcircuitfault" 6 "BattFltStsPrm_OcFlt_Overcurrentfault" 5 "BattFltStsPrm_HiTFlt_Hightemperaturefault" 4 "BattFltStsPrm_UvFlt_Undervoltagefault" 3 "BattFltStsPrm_OvFlt_Overvoltagefault" 2 "BattFltStsPrm_LSocFlt_LowSocfault" 1 "BattFltStsPrm_QCFlt_QuiescCurrtanomaly" 0 "BattFltStsPrm_NoFlt_Default" ;
VAL_ 153 BattFltStsSecBattFltStsPrm 15 "BattFltStsPrm_RlyOpenSoonIndcn" 14 "BattFltStsPrm_WakeupActvFlg" 13 "BattFltStsPrm_ResetActvFlg" 11 "BattFltStsPrm_ThermRunawayFlt" 7 "BattFltStsPrm_ScFlt_shortcircuitfault" 6 "BattFltStsPrm_OcFlt_Overcurrentfault" 5 "BattFltStsPrm_HiTFlt_Hightemperaturefault" 4 "BattFltStsPrm_UvFlt_Undervoltagefault" 3 "BattFltStsPrm_OvFlt_Overvoltagefault" 2 "BattFltStsPrm_LSocFlt_LowSocfault" 1 "BattFltStsPrm_QCFlt_QuiescCurrtanomaly" 0 "BattFltStsPrm_NoFlt_Default" ;
VAL_ 153 PassAirbNotiConfirm 3 "Onoff2_Off" 2 "Onoff2_On1" 1 "Onoff2_On" 0 "Onoff2_Idle" ;
VAL_ 153 SftyAirbRollovrSuppSwt 2 "OnOffNoReq_Off" 1 "OnOffNoReq_On" 0 "OnOffNoReq_NoReq" ;
VAL_ 153 WinPosnStsAtReRi 31 "WinAndRoofAndCurtPosnTyp_Movg" 30 "WinAndRoofAndCurtPosnTyp_Resd4" 29 "WinAndRoofAndCurtPosnTyp_Resd3" 28 "WinAndRoofAndCurtPosnTyp_Resd2" 27 "WinAndRoofAndCurtPosnTyp_Resd1" 26 "WinAndRoofAndCurtPosnTyp_OpenFull" 25 "WinAndRoofAndCurtPosnTyp_PercOpen96" 24 "WinAndRoofAndCurtPosnTyp_PercOpen92" 23 "WinAndRoofAndCurtPosnTyp_PercOpen88" 22 "WinAndRoofAndCurtPosnTyp_PercOpen84" 21 "WinAndRoofAndCurtPosnTyp_PercOpen80" 20 "WinAndRoofAndCurtPosnTyp_PercOpen76" 19 "WinAndRoofAndCurtPosnTyp_PercOpen72" 18 "WinAndRoofAndCurtPosnTyp_PercOpen68" 17 "WinAndRoofAndCurtPosnTyp_PercOpen64" 16 "WinAndRoofAndCurtPosnTyp_PercOpen60" 15 "WinAndRoofAndCurtPosnTyp_PercOpen56" 14 "WinAndRoofAndCurtPosnTyp_PercOpen52" 13 "WinAndRoofAndCurtPosnTyp_PercOpen48" 12 "WinAndRoofAndCurtPosnTyp_PercOpen44" 11 "WinAndRoofAndCurtPosnTyp_PercOpen40" 10 "WinAndRoofAndCurtPosnTyp_PercOpen36" 9 "WinAndRoofAndCurtPosnTyp_PercOpen32" 8 "WinAndRoofAndCurtPosnTyp_PercOpen28" 7 "WinAndRoofAndCurtPosnTyp_PercOpen24" 6 "WinAndRoofAndCurtPosnTyp_PercOpen20" 5 "WinAndRoofAndCurtPosnTyp_PercOpen16" 4 "WinAndRoofAndCurtPosnTyp_PercOpen12" 3 "WinAndRoofAndCurtPosnTyp_PercOpen8" 2 "WinAndRoofAndCurtPosnTyp_PercOpen4" 1 "WinAndRoofAndCurtPosnTyp_ClsFull" 0 "WinAndRoofAndCurtPosnTyp_PosnUkwn" ;
VAL_ 309 EmgyBrkLiIndcrTurn 3 "OnOffCrit1_NotVld2" 2 "OnOffCrit1_On" 1 "OnOffCrit1_Off" 0 "OnOffCrit1_NotVld1" ;
VAL_ 309 SecRowRiDivePosSeatPosQf 3 "Qf1_DataCalcdWithDevDefd" 2 "Qf1_DevOfDataNotWithinRngAllwd" 1 "Qf1_DataTmpUndefdAndEvlnInProgs" 0 "Qf1_DevOfDataUndefd" ;
VAL_ 820 ExtrLtgStsAFS 3 "DevSts4_Resd" 2 "DevSts4_Err" 1 "DevSts4_On" 0 "DevSts4_Off" ;
VAL_ 820 ExtrLtgStsAHBC 3 "DevSts4_Resd" 2 "DevSts4_Err" 1 "DevSts4_On" 0 "DevSts4_Off" ;
VAL_ 820 ExtrLtgStsAHL 3 "DevSts4_Resd" 2 "DevSts4_Err" 1 "DevSts4_On" 0 "DevSts4_Off" ;
VAL_ 820 ExtrLtgStsAllWL 3 "DevSts4_Resd" 2 "DevSts4_Err" 1 "DevSts4_On" 0 "DevSts4_Off" ;
VAL_ 820 ExtrLtgStsApproach 3 "DevSts4_Resd" 2 "DevSts4_Err" 1 "DevSts4_On" 0 "DevSts4_Off" ;
VAL_ 820 ExtrLtgStsCornrgLi 3 "DevSts4_Resd" 2 "DevSts4_Err" 1 "DevSts4_On" 0 "DevSts4_Off" ;
VAL_ 820 ExtrLtgStsDBL 3 "DevSts4_Resd" 2 "DevSts4_Err" 1 "DevSts4_On" 0 "DevSts4_Off" ;
VAL_ 820 ExtrLtgStsDRL 3 "DevSts4_Resd" 2 "DevSts4_Err" 1 "DevSts4_On" 0 "DevSts4_Off" ;
VAL_ 820 ExtrLtgStsFlash 3 "DevSts4_Resd" 2 "DevSts4_Err" 1 "DevSts4_On" 0 "DevSts4_Off" ;
VAL_ 820 ExtrLtgStsFrntFog 3 "DevSts4_Resd" 2 "DevSts4_Err" 1 "DevSts4_On" 0 "DevSts4_Off" ;
VAL_ 820 ExtrLtgStsGoodbye 3 "DevSts4_Resd" 2 "DevSts4_Err" 1 "DevSts4_On" 0 "DevSts4_Off" ;
VAL_ 820 ExtrLtgStsHiBeam 3 "DevSts4_Resd" 2 "DevSts4_Err" 1 "DevSts4_On" 0 "DevSts4_Off" ;
VAL_ 820 ExtrLtgStsHomeSafe 3 "DevSts4_Resd" 2 "DevSts4_Err" 1 "DevSts4_On" 0 "DevSts4_Off" ;
VAL_ 820 ExtrLtgStsHWL 3 "DevSts4_Resd" 2 "DevSts4_Err" 1 "DevSts4_On" 0 "DevSts4_Off" ;
VAL_ 820 ExtrLtgStsLoBeam 3 "DevSts4_Resd" 2 "DevSts4_Err" 1 "DevSts4_On" 0 "DevSts4_Off" ;
VAL_ 820 ExtrLtgStsLtgShow 3 "DevSts4_Resd" 2 "DevSts4_Err" 1 "DevSts4_On" 0 "DevSts4_Off" ;
VAL_ 820 ExtrLtgStsPosLiFrnt 3 "DevSts4_Resd" 2 "DevSts4_Err" 1 "DevSts4_On" 0 "DevSts4_Off" ;
VAL_ 820 ExtrLtgStsPosLiRe 3 "DevSts4_Resd" 2 "DevSts4_Err" 1 "DevSts4_On" 0 "DevSts4_Off" ;
VAL_ 820 ExtrLtgStsReFog 3 "DevSts4_Resd" 2 "DevSts4_Err" 1 "DevSts4_On" 0 "DevSts4_Off" ;
VAL_ 820 ExtrLtgStsReverseLi 3 "DevSts4_Resd" 2 "DevSts4_Err" 1 "DevSts4_On" 0 "DevSts4_Off" ;
VAL_ 820 ExtrLtgStsStopLi 3 "DevSts4_Resd" 2 "DevSts4_Err" 1 "DevSts4_On" 0 "DevSts4_Off" ;
VAL_ 820 ExtrLtgStsTurnIndrLe 3 "DevSts4_Resd" 2 "DevSts4_Err" 1 "DevSts4_On" 0 "DevSts4_Off" ;
VAL_ 820 ExtrLtgStsTurnIndrRi 3 "DevSts4_Resd" 2 "DevSts4_Err" 1 "DevSts4_On" 0 "DevSts4_Off" ;
VAL_ 820 ExtrLtgStsWelcome 3 "DevSts4_Resd" 2 "DevSts4_Err" 1 "DevSts4_On" 0 "DevSts4_Off" ;
VAL_ 625 ActvnOfSymIllmn 1 "Boolean_TRUE" 0 "Boolean_FALSE" ;
VAL_ 625 CmptmtTReCmptmtTFrntQf 3 "CmptmtTFrntQf_SnsrDataOk" 2 "CmptmtTFrntQf_SnsrDataNotOk" 1 "CmptmtTFrntQf_FanNotRunning" 0 "CmptmtTFrntQf_SnsrDataUndefd" ;
VAL_ 625 CmptmtTReFanForCmptmtTRunng 1 "Flg1_Set" 0 "Flg1_Rst" ;
VAL_ 625 HmiSeatVentAutStrtRowThrdLe 1 "OnOff1_On" 0 "OnOff1_Off" ;
VAL_ 625 HmiSeatVentAutStrtRowThrdRi 1 "OnOff1_On" 0 "OnOff1_Off" ;
VAL_ 625 RcwmBeltReq 3 "RcwmBeltReq_Reserved" 2 "RcwmBeltReq_NoPretighten" 1 "RcwmBeltReq_Pretighten" 0 "RcwmBeltReq_Default" ;
VAL_ 625 SeatHeatRowThrdLeEna 1 "OnOff2_Off" 0 "OnOff2_On" ;
VAL_ 625 SeatHeatRowThrdRiEna 1 "OnOff2_Off" 0 "OnOff2_On" ;
VAL_ 625 SeatVentnRowSecLeEna 1 "OnOff2_Off" 0 "OnOff2_On" ;
VAL_ 625 SeatVentnRowThrdLeEna 1 "OnOff2_Off" 0 "OnOff2_On" ;
VAL_ 625 SeatVentnRowThrdRiEna 1 "OnOff2_Off" 0 "OnOff2_On" ;
VAL_ 625 WinPosnStsAtPass 31 "WinAndRoofAndCurtPosnTyp_Movg" 30 "WinAndRoofAndCurtPosnTyp_Resd4" 29 "WinAndRoofAndCurtPosnTyp_Resd3" 28 "WinAndRoofAndCurtPosnTyp_Resd2" 27 "WinAndRoofAndCurtPosnTyp_Resd1" 26 "WinAndRoofAndCurtPosnTyp_OpenFull" 25 "WinAndRoofAndCurtPosnTyp_PercOpen96" 24 "WinAndRoofAndCurtPosnTyp_PercOpen92" 23 "WinAndRoofAndCurtPosnTyp_PercOpen88" 22 "WinAndRoofAndCurtPosnTyp_PercOpen84" 21 "WinAndRoofAndCurtPosnTyp_PercOpen80" 20 "WinAndRoofAndCurtPosnTyp_PercOpen76" 19 "WinAndRoofAndCurtPosnTyp_PercOpen72" 18 "WinAndRoofAndCurtPosnTyp_PercOpen68" 17 "WinAndRoofAndCurtPosnTyp_PercOpen64" 16 "WinAndRoofAndCurtPosnTyp_PercOpen60" 15 "WinAndRoofAndCurtPosnTyp_PercOpen56" 14 "WinAndRoofAndCurtPosnTyp_PercOpen52" 13 "WinAndRoofAndCurtPosnTyp_PercOpen48" 12 "WinAndRoofAndCurtPosnTyp_PercOpen44" 11 "WinAndRoofAndCurtPosnTyp_PercOpen40" 10 "WinAndRoofAndCurtPosnTyp_PercOpen36" 9 "WinAndRoofAndCurtPosnTyp_PercOpen32" 8 "WinAndRoofAndCurtPosnTyp_PercOpen28" 7 "WinAndRoofAndCurtPosnTyp_PercOpen24" 6 "WinAndRoofAndCurtPosnTyp_PercOpen20" 5 "WinAndRoofAndCurtPosnTyp_PercOpen16" 4 "WinAndRoofAndCurtPosnTyp_PercOpen12" 3 "WinAndRoofAndCurtPosnTyp_PercOpen8" 2 "WinAndRoofAndCurtPosnTyp_PercOpen4" 1 "WinAndRoofAndCurtPosnTyp_ClsFull" 0 "WinAndRoofAndCurtPosnTyp_PosnUkwn" ;
VAL_ 532 RoadInclnQly 2 "Qly2_Vld" 1 "Qly2_NoInfo" 0 "Qly2_Flt" ;
VAL_ 532 SeatHeatRowSecLeEna 1 "OnOff2_Off" 0 "OnOff2_On" ;
VAL_ 532 SeatHeatRowSecRiEna 1 "OnOff2_Off" 0 "OnOff2_On" ;
VAL_ 532 SeatMassgFctDrvrMassgInten 3 "MassgIntenLvl_Off" 2 "MassgIntenLvl_IntenHi" 1 "MassgIntenLvl_IntenNorm" 0 "MassgIntenLvl_IntenLo" ;
VAL_ 532 SeatMassgFctDrvrMassgProg 7 "MassgProgTyp_Prog8" 6 "MassgProgTyp_Prog7" 5 "MassgProgTyp_Prog6" 4 "MassgProgTyp_Prog5" 3 "MassgProgTyp_Prog4" 2 "MassgProgTyp_Prog3" 1 "MassgProgTyp_Prog2" 0 "MassgProgTyp_Prog1" ;
VAL_ 532 SeatMassgFctDrvrOnOff 1 "OnOff1_On" 0 "OnOff1_Off" ;
VAL_ 532 SeatMassgLumHeiCtrlDrvr 2 "SwtVertSts1_Dwn" 1 "SwtVertSts1_Up" 0 "SwtVertSts1_Idle" ;
VAL_ 532 SeatMassgLumMotrEnaDrvr 2 "MotrCfgTyp_MotrWthSnsr" 1 "MotrCfgTyp_MotrWoSnsr" 0 "MotrCfgTyp_NoMotr" ;
VAL_ 532 SeatVentnRowSecRiEna 1 "OnOff2_Off" 0 "OnOff2_On" ;
VAL_ 431 ThrdLeSeatLumDisSts 1 "Boolean_TRUE" 0 "Boolean_FALSE" ;
VAL_ 431 ThrdLeSeatMassDisSts 1 "Boolean_TRUE" 0 "Boolean_FALSE" ;
VAL_ 431 ThrdLeSeatSideSpprtDisSts 1 "Boolean_TRUE" 0 "Boolean_FALSE" ;
VAL_ 431 ThrdRiSeatLumDisSts 1 "Boolean_TRUE" 0 "Boolean_FALSE" ;
VAL_ 431 ThrdRiSeatMassDisSts 1 "Boolean_TRUE" 0 "Boolean_FALSE" ;
VAL_ 431 ThrdRiSeatSideSpprtDisSts 1 "Boolean_TRUE" 0 "Boolean_FALSE" ;
VAL_ 431 ThrdRowLeSeatMotPosnCalReq 1 "Boolean_TRUE" 0 "Boolean_FALSE" ;
VAL_ 431 ThrdRowRiSeatMotPosnCalReq 1 "Boolean_TRUE" 0 "Boolean_FALSE" ;
VAL_ 431 WPRLActvReqFromHmi 1 "OnOff1_On" 0 "OnOff1_Off" ;
VAL_ 431 WPRRActvReqFromHmi 1 "OnOff1_On" 0 "OnOff1_Off" ;
VAL_ 272 WhlDirRotlFrntLe 3 "WhlRotlDirStd1_Backw" 2 "WhlRotlDirStd1_Fwd" 1 "WhlRotlDirStd1_StandStill" 0 "WhlRotlDirStd1_Undefd" ;
VAL_ 272 WhlDirRotlFrntRi 3 "WhlRotlDirStd1_Backw" 2 "WhlRotlDirStd1_Fwd" 1 "WhlRotlDirStd1_StandStill" 0 "WhlRotlDirStd1_Undefd" ;
VAL_ 272 WhlSpdCircumlFrntLeQf 3 "GenQf1_AccurData" 2 "GenQf1_DataAccurNotWithinSpcn" 1 "GenQf1_TmpUndefdData" 0 "GenQf1_UndefindDataAccur" ;
VAL_ 272 WhlSpdCircumlFrntRiQf 3 "GenQf1_AccurData" 2 "GenQf1_DataAccurNotWithinSpcn" 1 "GenQf1_TmpUndefdData" 0 "GenQf1_UndefindDataAccur" ;
VAL_ 282 TrCrashUnlckCmd 1 "Unlck" 0 "Default" ;
VAL_ 282 WhlSpdCircumlReLeQf 3 "GenQf1_AccurData" 2 "GenQf1_DataAccurNotWithinSpcn" 1 "GenQf1_TmpUndefdData" 0 "GenQf1_UndefindDataAccur" ;
VAL_ 282 WhlSpdCircumlReRiQf 3 "GenQf1_AccurData" 2 "GenQf1_DataAccurNotWithinSpcn" 1 "GenQf1_TmpUndefdData" 0 "GenQf1_UndefindDataAccur" ;
VAL_ 290 SecRowLeArmRstMotMoveReq 2 "SwtVertSts1_Dwn" 1 "SwtVertSts1_Up" 0 "SwtVertSts1_Idle" ;
VAL_ 290 SecRowLeDiveMotMoveReq 2 "SwtVertSts1_Dwn" 1 "SwtVertSts1_Up" 0 "SwtVertSts1_Idle" ;
VAL_ 292 SecRowLeLegExtMotMoveReq 2 "SwtHozlSts1_Backw" 1 "SwtHozlSts1_Fwd" 0 "SwtHozlSts1_Idle" ;
VAL_ 292 SecRowLeLegRotMotMoveReq 2 "SwtVertSts1_Dwn" 1 "SwtVertSts1_Up" 0 "SwtVertSts1_Idle" ;
VAL_ 293 SecRowLeRotMotMoveReq 2 "SwtHozlSts2_Outward" 1 "SwtHozlSts2_Inward" 0 "SwtHozlSts2_Idle" ;
VAL_ 293 SecRowLeSideSldMotMoveReq 2 "SwtHozlSts2_Outward" 1 "SwtHozlSts2_Inward" 0 "SwtHozlSts2_Idle" ;
VAL_ 296 SecRowRiArmRstMotMoveReq 2 "SwtVertSts1_Dwn" 1 "SwtVertSts1_Up" 0 "SwtVertSts1_Idle" ;
VAL_ 296 SecRowRiDiveMotMoveReq 2 "SwtVertSts1_Dwn" 1 "SwtVertSts1_Up" 0 "SwtVertSts1_Idle" ;
VAL_ 297 SecRowRiHeiMotMoveReq 2 "SwtVertSts1_Dwn" 1 "SwtVertSts1_Up" 0 "SwtVertSts1_Idle" ;
VAL_ 297 SecRowRiInclMotMoveReq 2 "SwtHozlSts1_Backw" 1 "SwtHozlSts1_Fwd" 0 "SwtHozlSts1_Idle" ;
VAL_ 298 SecRowRiLegExtMotMoveReq 2 "SwtHozlSts1_Backw" 1 "SwtHozlSts1_Fwd" 0 "SwtHozlSts1_Idle" ;
VAL_ 298 SecRowRiLegRotMotMoveReq 2 "SwtVertSts1_Dwn" 1 "SwtVertSts1_Up" 0 "SwtVertSts1_Idle" ;
VAL_ 300 SecRowLeHeiMotMoveReq 2 "SwtVertSts1_Dwn" 1 "SwtVertSts1_Up" 0 "SwtVertSts1_Idle" ;
VAL_ 300 SecRowLeInclMotMoveReq 2 "SwtHozlSts1_Backw" 1 "SwtHozlSts1_Fwd" 0 "SwtHozlSts1_Idle" ;
VAL_ 300 SecRowLeSldMotMoveReq 2 "SwtHozlSts1_Backw" 1 "SwtHozlSts1_Fwd" 0 "SwtHozlSts1_Idle" ;
VAL_ 300 SecRowLeZeroGrvyMotMoveReq 2 "SwtVertSts1_Dwn" 1 "SwtVertSts1_Up" 0 "SwtVertSts1_Idle" ;
VAL_ 300 SecRowRiRotMotMoveReq 2 "SwtHozlSts2_Outward" 1 "SwtHozlSts2_Inward" 0 "SwtHozlSts2_Idle" ;
VAL_ 300 SecRowRiSideSldMotMoveReq 2 "SwtHozlSts2_Outward" 1 "SwtHozlSts2_Inward" 0 "SwtHozlSts2_Idle" ;
VAL_ 300 SecRowRiSldMotMoveReq 2 "SwtHozlSts1_Backw" 1 "SwtHozlSts1_Fwd" 0 "SwtHozlSts1_Idle" ;
VAL_ 300 SecRowRiZeroGrvyMotMoveReq 2 "SwtVertSts1_Dwn" 1 "SwtVertSts1_Up" 0 "SwtVertSts1_Idle" ;
VAL_ 301 ThrdRowLeCushFldMotMoveReq 2 "SwtVertSts1_Dwn" 1 "SwtVertSts1_Up" 0 "SwtVertSts1_Idle" ;
VAL_ 301 ThrdRowLeInclMotMoveReq 2 "SwtHozlSts1_Backw" 1 "SwtHozlSts1_Fwd" 0 "SwtHozlSts1_Idle" ;
VAL_ 294 ThrdRowLeLegRotMotMoveReq 2 "SwtVertSts1_Dwn" 1 "SwtVertSts1_Up" 0 "SwtVertSts1_Idle" ;
VAL_ 294 ThrdRowLeSldMotMoveReq 2 "SwtHozlSts1_Backw" 1 "SwtHozlSts1_Fwd" 0 "SwtHozlSts1_Idle" ;
VAL_ 303 SecRowLeRotLckMotMoveReq 2 "LockUnlckReq1_LockUnlckReqLock" 1 "LockUnlckReq1_LockUnlckReqUnlck" 0 "LockUnlckReq1_LockUnlckReqIdle" ;
VAL_ 303 SecRowRiRotLckMotMoveReq 2 "LockUnlckReq1_LockUnlckReqLock" 1 "LockUnlckReq1_LockUnlckReqUnlck" 0 "LockUnlckReq1_LockUnlckReqIdle" ;
VAL_ 303 ThrdRowLeCushFldLckMotReq 2 "LockUnlckReq1_LockUnlckReqLock" 1 "LockUnlckReq1_LockUnlckReqUnlck" 0 "LockUnlckReq1_LockUnlckReqIdle" ;
VAL_ 303 ThrdRowRiCushFldLckMotReq 2 "LockUnlckReq1_LockUnlckReqLock" 1 "LockUnlckReq1_LockUnlckReqUnlck" 0 "LockUnlckReq1_LockUnlckReqIdle" ;
VAL_ 303 ThrdRowRiCushFldMotMoveReq 2 "SwtVertSts1_Dwn" 1 "SwtVertSts1_Up" 0 "SwtVertSts1_Idle" ;
VAL_ 303 ThrdRowRiInclMotMoveReq 2 "SwtHozlSts1_Backw" 1 "SwtHozlSts1_Fwd" 0 "SwtHozlSts1_Idle" ;
VAL_ 303 ThrdRowRiLegRotMotMoveReq 2 "SwtVertSts1_Dwn" 1 "SwtVertSts1_Up" 0 "SwtVertSts1_Idle" ;
VAL_ 303 ThrdRowRiSldMotMoveReq 2 "SwtHozlSts1_Backw" 1 "SwtHozlSts1_Fwd" 0 "SwtHozlSts1_Idle" ;
VAL_ 1281 WakeUpReasonsforZCUDM 741 "WakeupReasons_871868" 740 "WakeupReasons_871957" 739 "WakeupReasons_871729" 738 "WakeupReasons_700779" 737 "WakeupReasons_839414" 736 "WakeupReasons_675025" 735 "WakeupReasons_671146" 734 "WakeupReasons_1031929" 733 "WakeupReasons_1033548" 732 "WakeupReasons_1033537" 731 "WakeupReasons_1033479" 730 "WakeupReasons_1030765" 729 "WakeupReasons_1028674" 728 "WakeupReasons_1033567" 727 "WakeupReasons_1033543" 726 "WakeupReasons_1033549" 725 "WakeupReasons_1033554" 724 "WakeupReasons_1033563" 723 "WakeupReasons_1033558" 722 "WakeupReasons_1029384" 721 "WakeupReasons_1029383" 720 "WakeupReasons_1029382" 719 "WakeupReasons_1032619" 718 "WakeupReasons_1024928" 717 "WakeupReasons_1033547" 716 "WakeupReasons_1033541" 715 "WakeupReasons_1033562" 714 "WakeupReasons_1033564" 713 "WakeupReasons_986765" 712 "WakeupReasons_1026103" 711 "WakeupReasons_1030764" 710 "WakeupReasons_1030941" 709 "WakeupReasons_1033556" 708 "WakeupReasons_1033539" 707 "WakeupReasons_1033534" 706 "WakeupReasons_1032477" 705 "WakeupReasons_1031280" 704 "WakeupReasons_1033542" 703 "WakeupReasons_1033632" 702 "WakeupReasons_1033533" 701 "WakeupReasons_1029166" 700 "WakeupReasons_1033538" 699 "WakeupReasons_1031789" 698 "WakeupReasons_1033552" 697 "WakeupReasons_1033553" 696 "WakeupReasons_1033559" 695 "WakeupReasons_1033544" 694 "WakeupReasons_1033561" 693 "WakeupReasons_1031029" 692 "WakeupReasons_1030360" 691 "WakeupReasons_1030761" 690 "WakeupReasons_1033550" 689 "WakeupReasons_1032579" 688 "WakeupReasons_1033557" 687 "WakeupReasons_1031936" 686 "WakeupReasons_1033566" 685 "WakeupReasons_1033551" 684 "WakeupReasons_1033540" 683 "WakeupReasons_1030760" 682 "WakeupReasons_1029735" 681 "WakeupReasons_1033565" 680 "WakeupReasons_852370" 679 "WakeupReasons_1033555" 678 "WakeupReasons_1033546" 677 "WakeupReasons_1032743" 676 "WakeupReasons_1032791" 675 "WakeupReasons_1033569" 674 "WakeupReasons_1031030" 673 "WakeupReasons_1028778" 672 "WakeupReasons_1030759" 671 "WakeupReasons_1031907" 670 "WakeupReasons_1033560" 669 "WakeupReasons_1031288" 668 "WakeupReasons_1030302" 667 "WakeupReasons_1031765" 666 "WakeupReasons_1031990" 665 "WakeupReasons_1028729" 664 "WakeupReasons_1030362" 663 "WakeupReasons_1030361" 662 "WakeupReasons_1030297" 661 "WakeupReasons_1030293" 660 "WakeupReasons_527345" 659 "WakeupReasons_988154" 658 "WakeupReasons_533580" 657 "WakeupReasons_533581" 656 "WakeupReasons_533576" 655 "WakeupReasons_1030255" 654 "WakeupReasons_527348" 653 "WakeupReasons_533578" 652 "WakeupReasons_527347" 651 "WakeupReasons_527346" 650 "WakeupReasons_ADCUReserve" 649 "WakeupReasons_885767" 648 "WakeupReasons_909025" 647 "WakeupReasons_909026" 646 "WakeupReasons_858177" 645 "WakeupReasons_858169" 644 "WakeupReasons_858152" 643 "WakeupReasons_973575" 642 "WakeupReason_973574" 641 "WakeupReason_987405" 640 "WakeupReason_858187" 639 "WakeupReason_988826" 638 "WakeupReason_988821" 637 "WakeupReason_987485" 636 "WakeupReason_908128" 635 "WakeupReason_908115" 634 "WakeupReason_856234" 633 "WakeupReason_856224" 632 "WakeupReason_858189" 631 "WakeupReason_858188" 630 "WakeupReason_872056" 629 "WakeupReason_870276" 628 "WakeupReason_858191" 627 "WakeupReason_847054" 626 "WakeupReason_856465" 625 "WakeupReason_872253" 624 "WakeupReason_855003" 623 "WakeupReason_855002" 622 "WakeupReason_854947" 621 "WakeupReason_855134" 620 "WakeupReason_854839" 619 "WakeupReason_854999" 618 "WakeupReason_855029" 617 "WakeupReason_714340" 616 "WakeupReason_852947" 615 "WakeupReason_852944" 614 "WakeupReason_852646" 613 "WakeupReason_852537" 612 "WakeupReason_852388" 611 "WakeupReason_852385" 610 "WakeupReason_852298" 609 "WakeupReason_852273" 608 "WakeupReason_852248" 607 "WakeupReason_852219" 606 "WakeupReason_852218" 605 "WakeupReason_852215" 604 "WakeupReason_852200" 603 "WakeupReason_852195" 602 "WakeupReason_852194" 601 "WakeupReason_852184" 600 "WakeupReason_852180" 599 "WakeupReason_852050" 598 "WakeupReason_852010" 597 "WakeupReason_851743" 596 "WakeupReason_851482" 595 "WakeupReason_702420" 594 "WakeupReason_667533" 593 "WakeupReason_645735" 592 "WakeupReason_362462" 591 "WakeupReason_361474" 590 "WakeupReason_361441" 589 "WakeupReason_846002" 588 "WakeupReason_845930" 587 "WakeupReason_842273" 586 "WakeupReason_846372" 585 "WakeupReason_675489" 584 "WakeupReason_675452" 583 "WakeupReason_298032" 582 "WakeupReason_322113" 581 "WakeupReason_320145" 580 "WakeupReason_841275" 579 "WakeupReason_839787" 578 "WakeupReason_839181" 577 "WakeupReason_714677" 576 "WakeupReason_840035" 566 "WakeupReason_839458" 565 "WakeupReason_837760" 564 "WakeupReason_702903" 563 "WakeupReason_837962" 562 "WakeupReason_703140" 561 "WakeupReason_837833" 560 "WakeupReason_839705" 559 "WakeupReason_839473" 558 "WakeupReason_838116" 557 "WakeupReason_717832" 556 "WakeupReason_714697" 555 "WakeupReason_714799" 554 "WakeupReason_714806" 553 "WakeupReason_709196" 552 "WakeupReason_710893" 551 "WakeupReason_708964" 550 "WakeupReason_715529" 549 "WakeupReason_714265" 548 "WakeupReason_714172" 547 "WakeupReason_713799" 546 "WakeupReason_706194" 545 "WakeupReason_713568" 544 "WakeupReason_710807" 543 "WakeupReason_714679" 542 "WakeupReason_714678" 541 "WakeupReason_715842" 540 "WakeupReason_714030" 539 "WakeupReason_710922" 538 "WakeupReason_716243" 537 "WakeupReason_713786" 536 "WakeupReason_714675" 535 "WakeupReason_702478" 534 "WakeupReason_713752" 533 "WakeupReasons_700530" 532 "WakeupReasons_698631" 531 "WakeupReasons_702452" 530 "WakeupReasons_700565" 529 "WakeupReasons_702402" 528 "WakeupReasons_702439" 527 "WakeupReasons_702448" 526 "WakeupReasons_701872" 525 "WakeupReasons_699114" 524 "WakeupReasons_702240" 523 "WakeupReasons_701270" 522 "WakeupReasons_533751" 521 "WakeupReasons_698581" 520 "WakeupReasons_698130" 519 "WakeupReasons_700130" 518 "WakeupReasons_699921" 517 "WakeupReasons_699919" 516 "WakeupReasons_700486" 515 "WakeupReasons_700782" 514 "WakeupReasons_696971" 513 "WakeupReasons_700692" 512 "WakeupReasons_698385" 511 "WakeupReasons_699922" 510 "WakeupReasons_697967" 509 "WakeupReasons_700684" 508 "WakeupReasons_644379" 507 "WakeupReasons_336435" 506 "WakeupReasons_683263" 505 "WakeupReasons_700554" 504 "WakeupReasons_691992" 503 "WakeupReasons_698129" 502 "WakeupReasons_696850" 501 "WakeupReasons_702088" 500 "WakeupReasons_696612" 499 "WakeupReasons_691994" 498 "WakeupReasons_700483" 497 "WakeupReasons_702204" 496 "WakeupReasons_700603" 495 "WakeupReasons_700215" 494 "WakeupReasons_701509" 493 "WakeupReasons_701508" 492 "WakeupReasons_700484" 491 "WakeupReasons_217907" 490 "WakeupReasons_194966" 489 "WakeupReasons_702174" 488 "WakeupReasons_697145" 487 "WakeupReasons_296931" 486 "WakeupReasons_700687" 485 "WakeupReasons_700686" 484 "WakeupReasons_698409" 483 "WakeupReasons_533750" 482 "WakeupReasons_700467" 481 "WakeupReasons_687404" 480 "WakeupReasons_681813" 479 "WakeupReasons_698288" 478 "WakeupReasons_698660" 477 "WakeupReasons_691993" 476 "WakeupReasons_700485" 475 "WakeupReasons_700425" 474 "WakeupReasons_702197" 473 "WakeupReasons_637992" 472 "WakeupReasons_698488" 471 "WakeupReasons_691991" 470 "WakeupReasons_692547" 469 "WakeupReasons_693914" 468 "WakeupReasons_693024" 467 "WakeupReasons_693005" 466 "WakeupReasons_667949" 465 "WakeupReasons_686281" 464 "WakeupReasons_680764" 463 "WakeupReasons_512384" 462 "WakeupReasons_692019" 461 "WakeupReasons_533850" 460 "WakeupReasons_533849" 459 "WakeupReasons_667188" 458 "WakeupReasons_514652" 457 "WakeupReasons_514651" 456 "WakeupReasons_112024" 455 "WakeupReasons_300690" 454 "WakeupReasons_299532" 453 "WakeupReasons_299531" 452 "WakeupReasons_299120" 451 "WakeupReasons_273516" 450 "WakeupReasons_265694" 449 "WakeupReasons_692439" 448 "WakeupReasons_354831" 447 "WakeupReasons_680765" 446 "WakeupReasons_45895" 445 "WakeupReasons_644275" 444 "WakeupReasons_351189" 443 "WakeupReasons_226570" 442 "WakeupReasons_654489" 441 "WakeupReasons_110181" 440 "WakeupReasons_226569" 439 "WakeupReasons_45896" 438 "WakeupReasons_112031" 437 "WakeupReasons_110173" 436 "WakeupReasons_677781" 435 "WakeupReasons_690939" 434 "WakeupReasons_354809" 433 "WakeupReasons_692022" 432 "WakeupReasons_690593" 431 "WakeupReasons_226571" 430 "WakeupReasons_675594" 429 "WakeupReasons_226565" 428 "WakeupReasons_692020" 427 "WakeupReasons_112035" 426 "WakeupReasons_112027" 425 "WakeupReasons_354672" 424 "WakeupReasons_168967" 423 "WakeupReasons_354674" 422 "WakeupReasons_168968" 421 "WakeupReasons_641483" 420 "WakeupReasons_641482" 419 "WakeupReasons_265698" 418 "WakeupReasons_265699" 417 "WakeupReasons_360491" 416 "WakeupReasons_357498" 415 "WakeupReasons_170290" 414 "WakeupReasons_690385" 413 "WakeupReasons_692021" 412 "WakeupReasons_91254" 411 "WakeupReasons_346654" 410 "WakeupReasons_200637" 409 "WakeupReasons_170285" 408 "WakeupReasons_265678" 407 "WakeupReasons_683934" 406 "WakeupReasons_680763" 405 "WakeupReasons_682074" 404 "WakeupReasons_682154" 403 "WakeupReasons_682152" 402 "WakeupReasons_682155" 401 "WakeupReasons_682153" 400 "WakeupReasons_682078" 399 "WakeupReasons_682076" 398 "WakeupReasons_682077" 397 "WakeupReasons_676285" 396 "WakeupReasons_681023" 395 "WakeupReasons_682023" 394 "WakeupReasons_681789" 393 "WakeupReasons_682688" 392 "WakeupReasons_682037" 391 "WakeupReasons_682032" 390 "WakeupReasons_681915" 389 "WakeupReasons_674839" 388 "WakeupReasons_682034" 387 "WakeupReasons_681711" 386 "WakeupReasons_681031" 385 "WakeupReasons_681134" 384 "WakeupReasons_670462" 383 "WakeupReasons_681028" 382 "WakeupReasons_680975" 381 "WakeupReasons_680974" 380 "WakeupReasons_668523" 379 "WakeupReasons_669822" 378 "WakeupReasons_680712" 377 "WakeupReasons_671005" 376 "WakeupReasons_177214" 375 "WakeupReasons_45655" 374 "WakeupReasons_667872" 373 "WakeupReasons_264964" 372 "WakeupReasons_262871" 371 "WakeupReasons_264691" 370 "WakeupReasons_297056" 369 "WakeupReasons_233755" 368 "WakeupReasons_145161" 367 "WakeupReasons_667842" 366 "WakeupReasons_46020" 365 "WakeupReasons_667874" 364 "WakeupReasons_667981" 363 "WakeupReasons_224211" 362 "WakeupReasons_45902" 361 "WakeupReasons_329457" 360 "WakeupReasons_88458" 359 "WakeupReasons_45900" 358 "WakeupReasons_83199" 357 "WakeupReasons_532933" 356 "WakeupReasons_532932" 355 "WakeupReasons_670942" 354 "WakeupReasons_305818" 353 "WakeupReasons_75103" 352 "WakeupReasons_667987" 351 "WakeupReasons_667983" 350 "WakeupReasons_675745" 349 "WakeupReasons_356598" 348 "WakeupReasons_128671" 347 "WakeupReasons_69216" 346 "WakeupReasons_264697" 345 "WakeupReasons_264943" 344 "WakeupReasons_197644" 343 "WakeupReasons_675564" 342 "WakeupReasons_657120" 341 "WakeupReasons_265745" 340 "WakeupReasons_657121" 339 "WakeupReasons_667982" 338 "WakeupReasons_674223" 337 "WakeupReasons_127926" 336 "WakeupReasons_127924" 335 "WakeupReasons_262872" 334 "WakeupReasons_45848" 333 "WakeupReasons_45847" 332 "WakeupReasons_45846" 331 "WakeupReasons_667869" 330 "WakeupReasons_45890" 329 "WakeupReasons_45888" 328 "WakeupReasons_670962" 327 "WakeupReasons_667973" 326 "WakeupReasons_45877" 325 "WakeupReasons_667980" 324 "WakeupReasons_45876" 323 "WakeupReasons_45871" 322 "WakeupReasons_45875" 321 "WakeupReasons_45872" 320 "WakeupReasons_45870" 319 "WakeupReasons_45869" 318 "WakeupReasons_80608" 317 "WakeupReasons_45898" 316 "WakeupReasons_45897" 315 "WakeupReasons_69679" 314 "WakeupReasons_69678" 313 "WakeupReasons_45887" 312 "WakeupReasons_263473" 311 "WakeupReasons_265131" 310 "WakeupReasons_268983" 309 "WakeupReasons_139075" 308 "WakeupReasons_200090" 307 "WakeupReasons_199714" 306 "WakeupReasons_80609" 305 "WakeupReasons_106669" 304 "WakeupReasons_675742" 303 "WakeupReasons_46017" 302 "WakeupReasons_670354" 301 "WakeupReasons_667985" 300 "WakeupReasons_670966" 299 "WakeupReasons_667871" 298 "WakeupReasons_193474" 297 "WakeupReasons_113348" 296 "WakeupReasons_532556" 295 "WakeupReasons_532555" 294 "WakeupReasons_667988" 293 "WakeupReasons_182918" 292 "WakeupReasons_311279" 291 "WakeupReasons_667848" 290 "WakeupReasons_667850" 289 "WakeupReasons_668393" 288 "WakeupReasons_668395" 287 "WakeupReasons_670753" 286 "WakeupReasons_667922" 285 "WakeupReasons_669447" 284 "WakeupReasons_670928" 283 "WakeupReasons_669465" 282 "WakeupReasons_676265" 281 "WakeupReasons_667947" 280 "WakeupReasons_667879" 279 "WakeupReasons_675837" 278 "WakeupReasons_675494" 277 "WakeupReasons_674958" 276 "WakeupReasons_675064" 275 "WakeupReasons_674953" 274 "WakeupReasons_658188" 273 "WakeupReasons_337991" 272 "WakeupReasons_197653" 271 "WakeupReasons_269140" 270 "WakeupReasons_312881" 269 "WakeupReasons_215560" 268 "WakeupReasons_269034" 267 "WakeupReasons_4471" 266 "WakeupReasons_185490" 265 "WakeupReasons_185457" 264 "WakeupReasons_198452" 263 "WakeupReasons_200683" 262 "WakeupReasons_358832" 261 "WakeupReasons_NMPDUReceived" 260 "WakeupReasons_670345" 259 "WakeupReasons_109467" 258 "WakeupReasons_109466" 257 "WakeupReasons_636801" 256 "WakeupReasons_45849" 255 "WakeupReasons_45850" 254 "WakeupReasons_45851" 253 "WakeupReasons_45852" 252 "WakeupReasons_45854" 251 "WakeupReasons_45853" 250 "WakeupReasons_45856" 249 "WakeupReasons_533872" 248 "WakeupReasons_516327" 247 "WakeupReasons_359559" 246 "WakeupReasons_241902" 245 "WakeupReasons_533372" 244 "WakeupReasons_533371" 243 "WakeupReasons_533370" 242 "WakeupReasons_315981" 241 "WakeupReasons_45858" 240 "WakeupReasons_668529" 239 "WakeupReasons_670087" 238 "WakeupReasons_668531" 237 "WakeupReasons_223920" 236 "WakeupReasons_176748" 235 "WakeupReasons_146470" 234 "WakeupReasons_112799" 233 "WakeupReasons_95949" 232 "WakeupReasons_156440" 231 "WakeupReasons_166267" 230 "WakeupReasons_101727" 229 "WakeupReasons_101728" 228 "WakeupReasons_101725" 227 "WakeupReasons_101706" 226 "WakeupReasons_659350" 225 "WakeupReasons_667820" 224 "WakeupReasons_331194" 223 "WakeupReasons_652546" 222 "WakeupReasons_224553" 221 "WakeupReasons_224552" 220 "WakeupReasons_110885" 219 "WakeupReasons_667953" 218 "WakeupReasons_667962" 217 "WakeupReasons_224550" 216 "WakeupReasons_197665" 215 "WakeupReasons_225961" 214 "WakeupReasons_198433" 213 "WakeupReasons_526438" 212 "WakeupReasons_316796" 211 "WakeupReasons_335068" 210 "WakeupReasons_535214" 209 "WakeupReasons_264726" 208 "WakeupReasons_360542" 207 "WakeupReasons_531743" 206 "WakeupReasons_226967" 205 "WakeupReasons_318382" 204 "WakeupReasons_199159" 203 "WakeupReasons_223715" 202 "WakeupReasons_643973" 201 "WakeupReasons_319401" 200 "WakeupReasons_264712" 199 "WakeupReasons_526426" 198 "WakeupReasons_533050" 197 "WakeupReasons_265937" 196 "WakeupReasons_108834" 195 "WakeupReasons_636556" 194 "WakeupReasons_655340" 193 "WakeupReasons_320895" 192 "WakeupReasons_321077" 191 "WakeupReasons_321323" 190 "WakeupReasons_321319" 189 "WakeupReasons_321057" 188 "WakeupReasons_359187" 187 "WakeupReasons_321317" 186 "WakeupReasons_355214" 185 "WakeupReasons_652361" 184 "WakeupReasons_192030" 183 "WakeupReasons_534145" 182 "WakeupReasons_526445" 181 "WakeupReasons_360299" 180 "WakeupReasons_525705" 179 "WakeupReasons_534077" 178 "WakeupReasons_359211" 177 "WakeupReasons_300681" 176 "WakeupReasons_198484" 175 "WakeupReasons_356549" 174 "WakeupReasons_360543" 173 "WakeupReasons_318342" 172 "WakeupReasons_299547" 171 "WakeupReasons_646109" 170 "WakeupReasons_645753" 169 "WakeupReasons_514502" 168 "WakeupReasons_515804" 167 "WakeupReasons_298808" 166 "WakeupReasons_265330" 165 "WakeupReasons_265328" 164 "WakeupReasons_265305" 163 "WakeupReasons_361279" 162 "WakeupReasons_361272" 161 "WakeupReasons_160596" 160 "WakeupReasons_197648" 159 "WakeupReasons_658603" 158 "WakeupReasons_322857" 157 "WakeupReasons_108810" 156 "WakeupReasons_179103" 155 "WakeupReasons_321845" 154 "WakeupReasons_340667" 153 "WakeupReasons_299117" 152 "WakeupReasons_514503" 151 "WakeupReasons_532007" 150 "WakeupReasons_337565" 149 "WakeupReasons_320631" 148 "WakeupReasons_354791" 147 "WakeupReasons_317616" 146 "WakeupReasons_644550" 145 "WakeupReasons_265232" 144 "WakeupReasons_514545" 143 "WakeupReasons_526429" 142 "WakeupReasons_265569" 141 "WakeupReasons_108841" 140 "WakeupReasons_160602" 139 "WakeupReasons_160597" 138 "WakeupReasons_264958" 137 "WakeupReasons_300682" 136 "WakeupReasons_224634" 135 "WakeupReasons_224617" 134 "WakeupReasons_220322" 133 "WakeupReasons_300427" 132 "WakeupReasons_269156" 131 "WakeupReasons_145462" 130 "WakeupReasons_145454" 129 "WakeupReasons_145419" 128 "WakeupReasons_145288" 127 "WakeupReasons_145373" 126 "WakeupReasons_145385" 125 "WakeupReasons_145362" 124 "WakeupReasons_145399" 123 "WakeupReasons_145388" 122 "WakeupReasons_145330" 121 "WakeupReasons_152774" 120 "WakeupReasons_145319" 119 "WakeupReasons_145311" 118 "WakeupReasons_106774" 117 "WakeupReasons_533044" 116 "WakeupReasons_636692" 115 "WakeupReasons_355409" 114 "WakeupReasons_133749" 113 "WakeupReasons_156412" 112 "WakeupReasons_320287" 111 "WakeupReasons_201348" 110 "WakeupReasons_264962" 109 "WakeupReasons_169884" 108 "WakeupReasons_45867" 107 "WakeupReasons_45866" 106 "WakeupReasons_659549" 105 "WakeupReasons_45864" 104 "WakeupReasons_201815" 103 "WakeupReasons_224831" 102 "WakeupReasons_222553" 101 "WakeupReasons_140678" 100 "WakeupReasons_169945" 99 "WakeupReasons_95444" 98 "WakeupReasons_145688" 97 "WakeupReasons_356190" 96 "WakeupReasons_264934" 95 "WakeupReasons_264932" 94 "WakeupReasons_152786" 93 "WakeupReasons_144970" 92 "WakeupReasons_186489" 91 "WakeupReasons_144897" 90 "WakeupReasons_199172" 89 "WakeupReasons_145707" 88 "WakeupReasons_152237" 87 "WakeupReasons_67182" 86 "WakeupReasons_338820" 85 "WakeupReasons_634710" 84 "WakeupReasons_109387" 83 "WakeupReasons_320126" 82 "WakeupReasons_109367" 81 "WakeupReasons_315364" 80 "WakeupReasons_297868" 79 "WakeupReasons_645810" 78 "WakeupReasons_634696" 77 "WakeupReasons_138997" 76 "WakeupReasons_360006" 75 "WakeupReasons_224061" 74 "WakeupReasons_68481" 73 "WakeupReasons_109364" 72 "WakeupReasons_68644" 71 "WakeupReasons_224065" 70 "WakeupReasons_119273" 69 "WakeupReasons_109382" 68 "WakeupReasons_360008" 67 "WakeupReasons_68676" 66 "WakeupReasons_645094" 65 "WakeupReasons_361509" 64 "WakeupReasons_361505" 63 "WakeupReasons_360904" 62 "WakeupReasons_355601" 61 "WakeupReasons_320277" 60 "WakeupReasons_319422" 59 "WakeupReasons_320282" 58 "WakeupReasons_169894" 57 "WakeupReasons_266860" 56 "WakeupReasons_45656" 55 "WakeupReasons_21997" 54 "WakeupReasons_225696" 53 "WakeupReasons_200156" 52 "WakeupReasons_161066" 51 "WakeupReasons_185670" 50 "WakeupReasons_197826" 49 "WakeupReasons_176921" 48 "WakeupReasons_108776" 47 "WakeupReasons_265333" 46 "WakeupReasons_100281" 45 "WakeupReasons_100278" 44 "WakeupReasons_100300" 43 "WakeupReasons_100275" 42 "WakeupReasons_100298" 41 "WakeupReasons_319139" 40 "WakeupReasons_170807" 39 "WakeupReasons_200937" 38 "WakeupReasons_182033" 37 "WakeupReasons_191050" 36 "WakeupReasons_264876" 35 "WakeupReasons_197642" 34 "WakeupReasons_170865" 33 "WakeupReasons_168966" 32 "WakeupReasons_667948" 31 "WakeupReasons_169655" 30 "WakeupReasons_667945" 29 "WakeupReasons_74188" 28 "WakeupReasons_321583" 27 "WakeupReasons_88125" 26 "WakeupReasons_88123" 25 "WakeupReasons_91253" 24 "WakeupReasons_21973" 23 "WakeupReasons_140084" 22 "WakeupReasons_45657" 21 "WakeupReasons_45659" 20 "WakeupReasons_22100" 19 "WakeupReasons_22013" 18 "WakeupReasons_22005" 17 "WakeupReasons_45794" 16 "WakeupReasons_45793" 15 "WakeupReasons_21901" 14 "WakeupReasons_658500" 13 "WakeupReasons_269739" 12 "WakeupReasons_269735" 11 "WakeupReasons_269740" 10 "WakeupReasons_22060" 9 "WakeupReasons_49446" 8 "WakeupReasons_22058" 7 "WakeupReasons_45654" 6 "WakeupReasons_264933" 5 "WakeupReasons_197643" 4 "WakeupReasons_168965" 3 "WakeupReasons_667951" 2 "WakeupReasons_169654" 1 "WakeupReasons_667950" 0 "WakeupReasons_0" ;
SIG_GROUP_ 792 VehCfgPrmExt2 1 : VehCfgPrmExt2CCPBytePosn6 VehCfgPrmExt2CCPBytePosn7 VehCfgPrmExt2BlkIDBytePosn1 VehCfgPrmExt2CCPBytePosn5 VehCfgPrmExt2CCPBytePosn3 VehCfgPrmExt2CCPBytePosn2 VehCfgPrmExt2CCPBytePosn8 VehCfgPrmExt2CCPBytePosn4;
SIG_GROUP_ 849 AmbTIndcdWithUnit 1 : AmbTIndcdWithUnitAmbTIndcdUnit AmbTIndcdWithUnitQF AmbTIndcdWithUnitAmbTIndcd;
SIG_GROUP_ 528 ADTakeoverReqGroup 1 : ADTakeoverReqGroupADTakeoverAudi ADTakeoverReqGroupADTakeoverMsg ADTakeoverReqGroupCntr ADTakeoverReqGroupChks;
SIG_GROUP_ 528 AsySftyFctStsToEDR 1 : AsySftyFctStsToEDRACSFB2FctSts AsySftyFctStsToEDRAEBSFctSts AsySftyFctStsToEDRLDWSFctSts AsySftyFctStsToEDRACSFDFctSts AsySftyFctStsToEDRACCFctSTs AsySftyFctStsToEDRACSFB1FctSts AsySftyFctStsToEDRESFFctSts AsySftyFctStsToEDRACSFEFctSts AsySftyFctStsToEDRACSFCFctSts AsySftyFctStsToEDRCSFFctSts;
SIG_GROUP_ 80 PreCrashFrontData 1 : PreCrashFrontDataChks PreCrashFrontDataCntr PreCrashFrontDataClosingVelocity PreCrashFrontDataTimeToImpact PreCrashFrontDataOverLap PreCrashFrontDataObjectClass;
SIG_GROUP_ 788 HoodOpenerReq 1 : HoodOpenerReqCntr HoodOpenerReqChks HoodOpenerReqDoorOpenerReq HoodOpenerReqTrigSrc;
SIG_GROUP_ 819 SecRowLeInclPos 1 : SecRowLeInclPosAngleDeg180 SecRowLeInclPosQf1;
SIG_GROUP_ 819 IndcrPat 1 : IndcrPatCmd1WdTiOn IndcrPatCmd1WdTiOff;
SIG_GROUP_ 819 SecRowRiInclPos 1 : SecRowRiInclPosQf1 SecRowRiInclPosAngleDeg180;
SIG_GROUP_ 289 CmptmtTFrnt 1 : CmptmtTFrntCmptmtTFrnt CmptmtTFrntQf CmptmtTFrntFanForCmptmtTRunng;
SIG_GROUP_ 1168 AmbTEstimd 1 : AmbTEstimdQf AmbTEstimdAmbTEstimd;
SIG_GROUP_ 1168 SeatClimaDurgClima 1 : SeatClimaDurgClimaHmiSeatHe_0006 SeatClimaDurgClimaHmiSeatHe_0003 SeatClimaDurgClimaHmiSeatVe_0004 SeatClimaDurgClimaHmiSeatVe_0003 SeatClimaDurgClimaHmiSeatHe_0004 SeatClimaDurgClimaHmiSeatHe_0005 SeatClimaDurgClimaHmiSeatVe_0006 SeatClimaDurgClimaHmiSeatVe_0005;
SIG_GROUP_ 612 RollAgGlb 1 : RollAgGlbVal RollAgGlbQf;
SIG_GROUP_ 32 SecRowLeDivePos 1 : SecRowLeDivePosSeatPosQf SecRowLeDivePosSeatPosPerc;
SIG_GROUP_ 234 TrsmParkLockd 1 : TrsmParkLockdCntr TrsmParkLockdTrsmParkLockd TrsmParkLockdChks;
SIG_GROUP_ 234 DoorSldngLeReReq 1 : DoorSldngLeReReqChks DoorSldngLeReReqDoorOpenerReq1 DoorSldngLeReReqCntr DoorSldngLeReReqTrigSrc2;
SIG_GROUP_ 234 DoorSldngRiReReq 1 : DoorSldngRiReReqCntr DoorSldngRiReReqTrigSrc2 DoorSldngRiReReqChks DoorSldngRiReReqDoorOpenerReq1;
SIG_GROUP_ 91 WhlDirRotlRe 1 : WhlDirRotlReRi WhlDirRotlReCntr WhlDirRotlReLe WhlDirRotlReChks;
SIG_GROUP_ 27 SteerWhlSnsr 1 : SteerWhlSnsrCntr SteerWhlSnsrAgSpd SteerWhlSnsrChks SteerWhlSnsrQf SteerWhlSnsrAg;
SIG_GROUP_ 320 HvSysRlySts 1 : HvSysRlyStsCntr HvSysRlyStsChks HvSysRlyStsHvSysRlySts;
SIG_GROUP_ 784 SeatRowThrdLeInclPosAngle 1 : SeatRowThrdLeInclPosAngleAngleDe SeatRowThrdLeInclPosAngleQf1;
SIG_GROUP_ 784 SeatRowThrdRiInclPosAngle 1 : SeatRowThrdRiInclPosAngleAngleDe SeatRowThrdRiInclPosAngleQf1;
SIG_GROUP_ 153 BattFltStsPrim 1 : BattFltStsPrimBattFltStsPrm BattFltStsPrimCntr BattFltStsPrimChks;
SIG_GROUP_ 153 BattFltStsSec 1 : BattFltStsSecBattFltStsPrm BattFltStsSecCntr BattFltStsSecChks;
SIG_GROUP_ 309 SecRowRiDivePos 1 : SecRowRiDivePosSeatPosQf SecRowRiDivePosSeatPosPerc;
SIG_GROUP_ 820 ExtrLtgSts 1 : ExtrLtgStsAllWL ExtrLtgStsDBL ExtrLtgStsHomeSafe ExtrLtgStsTurnIndrRi ExtrLtgStsAHBC ExtrLtgStsLtgShow ExtrLtgStsWelcome ExtrLtgStsCntr ExtrLtgStsPosLiFrnt ExtrLtgStsHWL ExtrLtgStsPosLiRe ExtrLtgStsCornrgLi ExtrLtgStsGoodbye ExtrLtgStsDRL ExtrLtgStsFlash ExtrLtgStsFrntFog ExtrLtgStsAFS ExtrLtgStsAHL ExtrLtgStsTurnIndrLe ExtrLtgStsHiBeam ExtrLtgStsReverseLi ExtrLtgStsReFog ExtrLtgStsChks ExtrLtgStsLoBeam ExtrLtgStsApproach ExtrLtgStsStopLi;
SIG_GROUP_ 625 CmptmtTRe 1 : CmptmtTReCmptmtTFrnt CmptmtTReFanForCmptmtTRunng CmptmtTReCmptmtTFrntQf;
SIG_GROUP_ 419 ZCUDMResdSig1ToSRSSafety 1 : ZCUDMResdSig1ToSRSSafetyUInt32 ZCUDMResdSig1ToSRSSafetyChks ZCUDMResdSig1ToSRSSafetyCntr;
SIG_GROUP_ 532 SeatMassgFctDrvr 1 : SeatMassgFctDrvrOnOff SeatMassgFctDrvrMassgInten SeatMassgFctDrvrMassgProg;
SIG_GROUP_ 532 RoadIncln 1 : RoadInclnRoadIncln RoadInclnQly;
SIG_GROUP_ 272 WhlDirRotlFrnt 1 : WhlDirRotlFrntCntr WhlDirRotlFrntChks WhlDirRotlFrntLe WhlDirRotlFrntRi;
SIG_GROUP_ 272 WhlSpdCircumlFrnt 1 : WhlSpdCircumlFrntCntr WhlSpdCircumlFrntChks WhlSpdCircumlFrntRiQf WhlSpdCircumlFrntLe WhlSpdCircumlFrntLeQf WhlSpdCircumlFrntWhlSpdCircumlFr;
SIG_GROUP_ 282 WhlSpdCircumlRe 1 : WhlSpdCircumlReLe WhlSpdCircumlReCntr WhlSpdCircumlReRiQf WhlSpdCircumlReChks WhlSpdCircumlReLeQf WhlSpdCircumlReRi;
SIG_GROUP_ 290 SecRowLeDiveMotPosReq 1 : SecRowLeDiveMotPosReqSpeed SecRowLeDiveMotPosReqTargPosReq;
SIG_GROUP_ 290 SecRowLeArmRstMotPosReq 1 : SecRowLeArmRstMotPosReqSpeed SecRowLeArmRstMotPosReqTargPosRe;
SIG_GROUP_ 290 SecRowLeHeiMotPosReq 1 : SecRowLeHeiMotPosReqTargPosReq SecRowLeHeiMotPosReqSpeed;
SIG_GROUP_ 292 SecRowLeLegRotMotPosReq 1 : SecRowLeLegRotMotPosReqSpeed SecRowLeLegRotMotPosReqTargPosRe;
SIG_GROUP_ 292 SecRowLeInclMotPosReq 1 : SecRowLeInclMotPosReqSpeed SecRowLeInclMotPosReqTargPosReq;
SIG_GROUP_ 292 SecRowLeLegExtMotPosReq 1 : SecRowLeLegExtMotPosReqSpeed SecRowLeLegExtMotPosReqTargPosRe;
SIG_GROUP_ 293 SecRowLeRotMotPosReq 1 : SecRowLeRotMotPosReqSpeed SecRowLeRotMotPosReqTargPosReq;
SIG_GROUP_ 293 SecRowLeZeroGrvyMotPosReq 1 : SecRowLeZeroGrvyMotPosReqSpeed SecRowLeZeroGrvyMotPosReqTargPos;
SIG_GROUP_ 293 SecRowLeSideSldMotPosReq 1 : SecRowLeSideSldMotPosReqTargPosR SecRowLeSideSldMotPosReqSpeed;
SIG_GROUP_ 296 SecRowRiDiveMotPosReq 1 : SecRowRiDiveMotPosReqSpeed SecRowRiDiveMotPosReqTargPosReq;
SIG_GROUP_ 296 SecRowLeSldMotPosReq 1 : SecRowLeSldMotPosReqSpeed SecRowLeSldMotPosReqTargPosReq;
SIG_GROUP_ 296 SecRowRiArmRstMotPosReq 1 : SecRowRiArmRstMotPosReqTargPosRe SecRowRiArmRstMotPosReqSpeed;
SIG_GROUP_ 297 SecRowRiHeiMotPosReq 1 : SecRowRiHeiMotPosReqTargPosReq SecRowRiHeiMotPosReqSpeed;
SIG_GROUP_ 297 SecRowRiInclMotPosReq 1 : SecRowRiInclMotPosReqTargPosReq SecRowRiInclMotPosReqSpeed;
SIG_GROUP_ 297 SecRowRiRotMotPosReq 1 : SecRowRiRotMotPosReqTargPosReq SecRowRiRotMotPosReqSpeed;
SIG_GROUP_ 298 SecRowRiSideSldMotPosReq 1 : SecRowRiSideSldMotPosReqSpeed SecRowRiSideSldMotPosReqTargPosR;
SIG_GROUP_ 298 SecRowRiLegExtMotPosReq 1 : SecRowRiLegExtMotPosReqTargPosRe SecRowRiLegExtMotPosReqSpeed;
SIG_GROUP_ 298 SecRowRiLegRotMotPosReq 1 : SecRowRiLegRotMotPosReqSpeed SecRowRiLegRotMotPosReqTargPosRe;
SIG_GROUP_ 300 SecRowRiZeroGrvyMotPosReq 1 : SecRowRiZeroGrvyMotPosReqSpeed SecRowRiZeroGrvyMotPosReqTargPos;
SIG_GROUP_ 300 SecRowRiSldMotPosReq 1 : SecRowRiSldMotPosReqSpeed SecRowRiSldMotPosReqTargPosReq;
SIG_GROUP_ 301 ThrdRowRiCushFldMotPosReq 1 : ThrdRowRiCushFldMotPosReqSpeed ThrdRowRiCushFldMotPosReqTargPos;
SIG_GROUP_ 301 ThrdRowLeCushFldMotPosReq 1 : ThrdRowLeCushFldMotPosReqSpeed ThrdRowLeCushFldMotPosReqTargPos;
SIG_GROUP_ 301 ThrdRowLeInclMotPosReq 1 : ThrdRowLeInclMotPosReqTargPosReq ThrdRowLeInclMotPosReqSpeed;
SIG_GROUP_ 294 ThrdRowRiInclMotPosReq 1 : ThrdRowRiInclMotPosReqTargPosReq ThrdRowRiInclMotPosReqSpeed;
SIG_GROUP_ 294 ThrdRowLeSldMotPosReq 1 : ThrdRowLeSldMotPosReqTargPosReq ThrdRowLeSldMotPosReqSpeed;
SIG_GROUP_ 294 ThrdRowLeLegRotMotPosReq 1 : ThrdRowLeLegRotMotPosReqSpeed ThrdRowLeLegRotMotPosReqTargPosR;
SIG_GROUP_ 303 ThrdRowRiLegRotMotPosReq 1 : ThrdRowRiLegRotMotPosReqSpeed ThrdRowRiLegRotMotPosReqTargPosR;
SIG_GROUP_ 303 ThrdRowRiSldMotPosReq 1 : ThrdRowRiSldMotPosReqSpeed ThrdRowRiSldMotPosReqTargPosReq;
SIG_GROUP_ 565 BrkFricTqTotAtWhlsAct 1 : BrkFricTqTotAtWhlsActCntr BrkFricTqTotAtWhlsActBrkFricTqTo BrkFricTqTotAtWhlsActChks;
SIG_GROUP_ 314 EngNSafe 1 : EngNSafeEngNChks EngNSafeEngNCntr EngNSafeEngN EngNSafeEngNGrdt;
